VERSION "canboat-NMEA2000-curated"

NS_ :

BS_:

BU_: Vector__XXX

BO_ 2565341184 PGN_59392: 8 Vector__XXX
 SG_ Data : 0|64@1+ (1.0,0) [0|18446744073709551615] "" Vector__XXX

BO_ 2565341184 PGN_59392_isoAcknowledgement: 8 Vector__XXX
 SG_ Control : 0|8@1+ (1.0,0) [0|255] "" Vector__XXX
 SG_ Group_Function : 8|8@1+ (1.0,0) [0|255] "" Vector__XXX
 SG_ PGN : 40|24@1+ (1.0,0) [0.0|262143.0] "" Vector__XXX

BO_ 2565472256 PGN_59904_isoRequest: 8 Vector__XXX
 SG_ PGN : 0|24@1+ (1.0,0) [0.0|262143.0] "" Vector__XXX

BO_ 2565537792 PGN_60160_isoTransportProtocolDataTransfer: 8 Vector__XXX
 SG_ SID : 0|8@1+ (1.0,0) [0|255] "" Vector__XXX
 SG_ Data : 8|56@1+ (1.0,0) [0|72057594037927935] "" Vector__XXX

BO_ 2565603328 PGN_60416_isoTransportProtocolConnectionManagementAbort: 8 Vector__XXX
 SG_ Group_Function_Code : 0|8@1+ (1.0,0) [0|255] "" Vector__XXX
 SG_ Reason : 8|8@1+ (1.0,0) [0|255] "" Vector__XXX
 SG_ PGN : 40|24@1+ (1.0,0) [0.0|262143.0] "" Vector__XXX

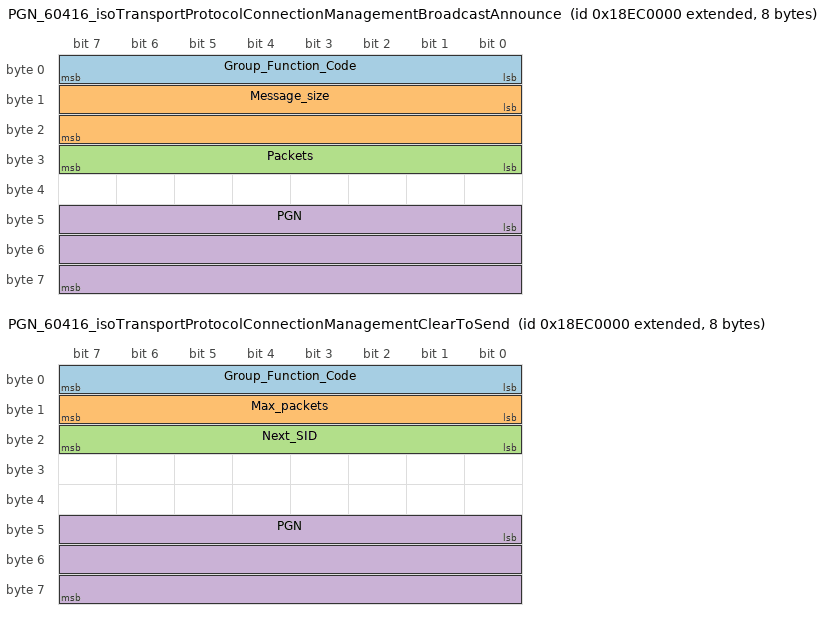
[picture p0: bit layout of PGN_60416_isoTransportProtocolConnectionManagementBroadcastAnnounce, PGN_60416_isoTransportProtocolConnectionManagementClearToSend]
BO_ 2565603328 PGN_60416_isoTransportProtocolConnectionManagementBroadcastAnnounce: 8 Vector__XXX
 SG_ Group_Function_Code : 0|8@1+ (1.0,0) [0|255] "" Vector__XXX
 SG_ Message_size : 8|16@1+ (1.0,0) [0|65535] "" Vector__XXX
 SG_ Packets : 24|8@1+ (1.0,0) [0|255] "" Vector__XXX
 SG_ PGN : 40|24@1+ (1.0,0) [0.0|262143.0] "" Vector__XXX

BO_ 2565603328 PGN_60416_isoTransportProtocolConnectionManagementClearToSend: 8 Vector__XXX
 SG_ Group_Function_Code : 0|8@1+ (1.0,0) [0|255] "" Vector__XXX
 SG_ Max_packets : 8|8@1+ (1.0,0) [0|255] "" Vector__XXX
 SG_ Next_SID : 16|8@1+ (1.0,0) [0|255] "" Vector__XXX
 SG_ PGN : 40|24@1+ (1.0,0) [0.0|262143.0] "" Vector__XXX

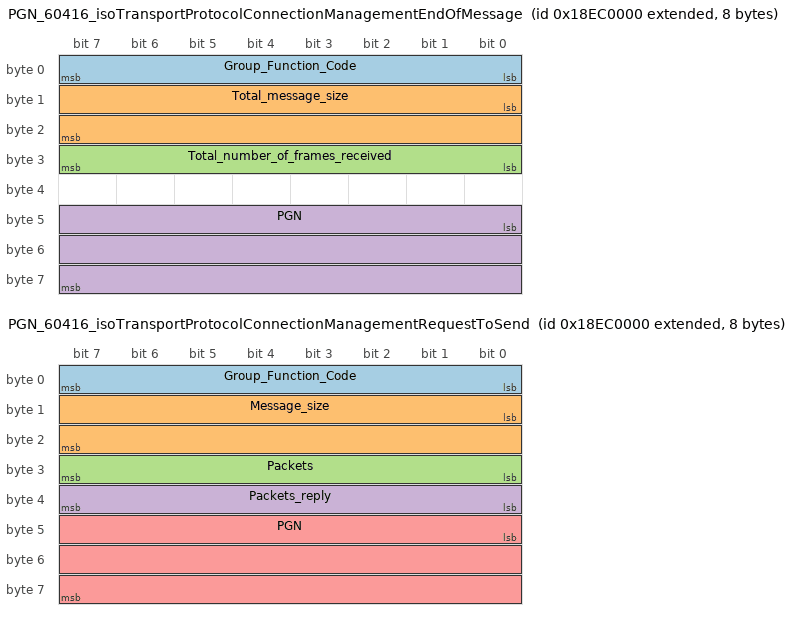
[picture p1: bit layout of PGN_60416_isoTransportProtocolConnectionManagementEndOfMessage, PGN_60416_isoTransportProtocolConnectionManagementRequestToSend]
BO_ 2565603328 PGN_60416_isoTransportProtocolConnectionManagementEndOfMessage: 8 Vector__XXX
 SG_ Group_Function_Code : 0|8@1+ (1.0,0) [0|255] "" Vector__XXX
 SG_ Total_message_size : 8|16@1+ (1.0,0) [0|65535] "" Vector__XXX
 SG_ Total_number_of_frames_received : 24|8@1+ (1.0,0) [0|255] "" Vector__XXX
 SG_ PGN : 40|24@1+ (1.0,0) [0.0|262143.0] "" Vector__XXX

BO_ 2565603328 PGN_60416_isoTransportProtocolConnectionManagementRequestToSend: 8 Vector__XXX
 SG_ Group_Function_Code : 0|8@1+ (1.0,0) [0|255] "" Vector__XXX
 SG_ Message_size : 8|16@1+ (1.0,0) [0|65535] "" Vector__XXX
 SG_ Packets : 24|8@1+ (1.0,0) [0|255] "" Vector__XXX
 SG_ Packets_reply : 32|8@1+ (1.0,0) [0|255] "" Vector__XXX
 SG_ PGN : 40|24@1+ (1.0,0) [0.0|262143.0] "" Vector__XXX

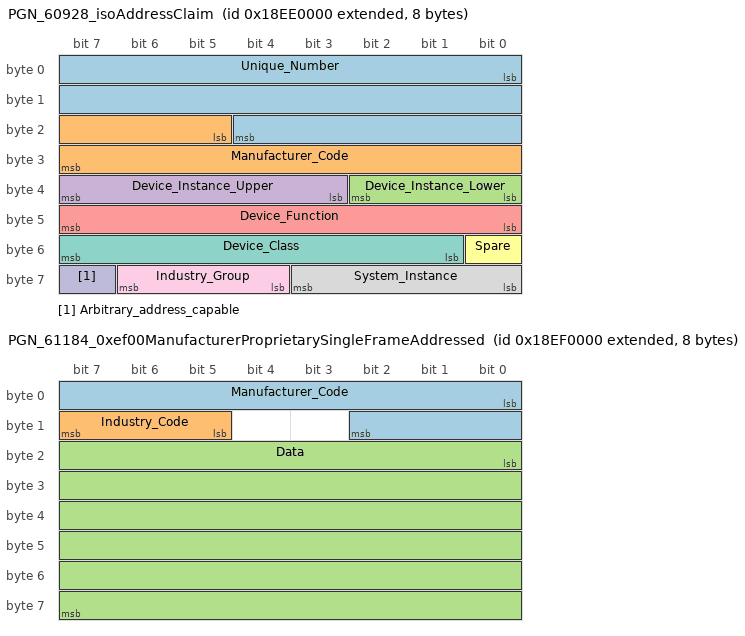
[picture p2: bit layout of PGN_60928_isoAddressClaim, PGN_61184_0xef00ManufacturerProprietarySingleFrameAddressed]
BO_ 2565734400 PGN_60928_isoAddressClaim: 8 Vector__XXX
 SG_ Unique_Number : 0|21@1+ (1.0,0) [0|2097151] "" Vector__XXX
 SG_ Manufacturer_Code : 21|11@1+ (1.0,0) [0|2047] "" Vector__XXX
 SG_ Device_Instance_Lower : 32|3@1+ (1.0,0) [0|7] "" Vector__XXX
 SG_ Device_Instance_Upper : 35|5@1+ (1.0,0) [0|31] "" Vector__XXX
 SG_ Device_Function : 40|8@1+ (1.0,0) [0|255] "" Vector__XXX
 SG_ Spare : 48|1@1+ (1.0,0) [0|1] "" Vector__XXX
 SG_ Device_Class : 49|7@1+ (1.0,0) [0|127] "" Vector__XXX
 SG_ System_Instance : 56|4@1+ (1.0,0) [0|15] "" Vector__XXX
 SG_ Industry_Group : 60|3@1+ (1.0,0) [0|7] "" Vector__XXX
 SG_ Arbitrary_address_capable : 63|1@1+ (1.0,0) [0|1] "" Vector__XXX

BO_ 2565799936 PGN_61184_0xef00ManufacturerProprietarySingleFrameAddressed: 8 Vector__XXX
 SG_ Manufacturer_Code : 0|11@1+ (1.0,0) [0|2047] "" Vector__XXX
 SG_ Industry_Code : 13|3@1+ (1.0,0) [0|7] "" Vector__XXX
 SG_ Data : 16|48@1+ (1.0,0) [0|281474976710655] "" Vector__XXX

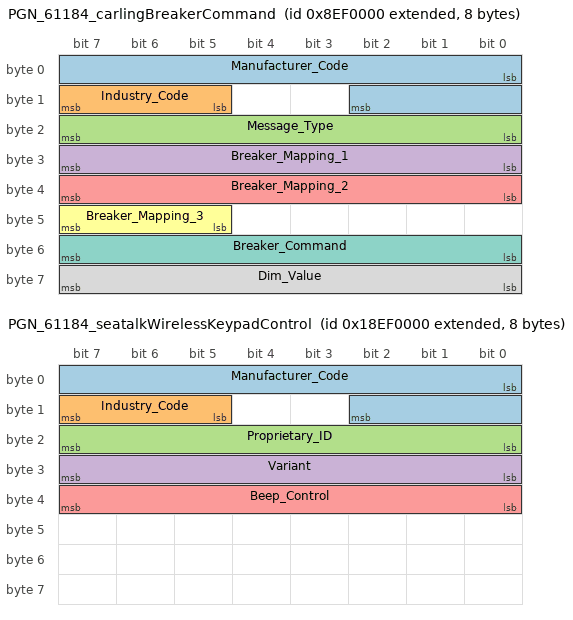
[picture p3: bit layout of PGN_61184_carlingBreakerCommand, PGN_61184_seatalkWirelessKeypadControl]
BO_ 2297364480 PGN_61184_carlingBreakerCommand: 8 Vector__XXX
 SG_ Manufacturer_Code : 0|11@1+ (1.0,0) [0|2047] "" Vector__XXX
 SG_ Industry_Code : 13|3@1+ (1.0,0) [0|7] "" Vector__XXX
 SG_ Message_Type : 16|8@1+ (1.0,0) [0|255] "" Vector__XXX
 SG_ Breaker_Mapping_1 : 24|8@1+ (1.0,0) [0|255] "" Vector__XXX
 SG_ Breaker_Mapping_2 : 32|8@1+ (1.0,0) [0|255] "" Vector__XXX
 SG_ Breaker_Mapping_3 : 45|3@1+ (1.0,0) [0|7] "" Vector__XXX
 SG_ Breaker_Command : 48|8@1+ (1.0,0) [0|255] "" Vector__XXX
 SG_ Dim_Value : 56|8@1+ (1.0,0) [0|255] "" Vector__XXX

BO_ 2565799936 PGN_61184_seatalkWirelessKeypadControl: 8 Vector__XXX
 SG_ Manufacturer_Code : 0|11@1+ (1.0,0) [0|2047] "" Vector__XXX
 SG_ Industry_Code : 13|3@1+ (1.0,0) [0|7] "" Vector__XXX
 SG_ Proprietary_ID : 16|8@1+ (1.0,0) [0|255] "" Vector__XXX
 SG_ Variant : 24|8@1+ (1.0,0) [0|255] "" Vector__XXX
 SG_ Beep_Control : 32|8@1+ (1.0,0) [0|255] "" Vector__XXX

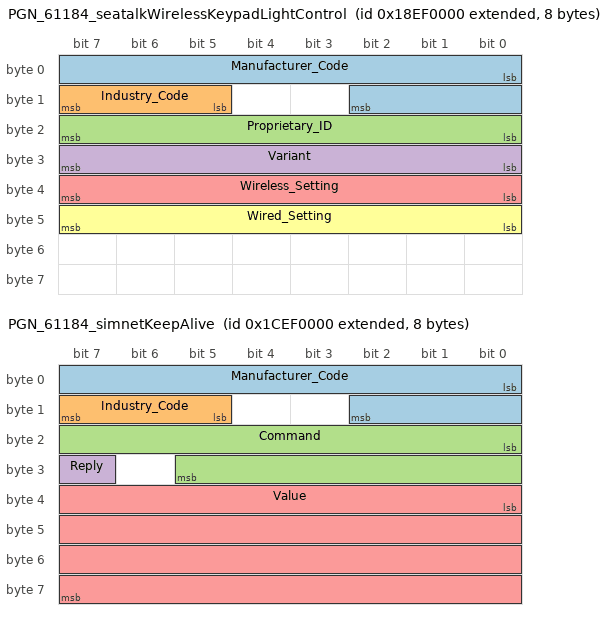
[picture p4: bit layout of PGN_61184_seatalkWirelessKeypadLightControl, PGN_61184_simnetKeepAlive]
BO_ 2565799936 PGN_61184_seatalkWirelessKeypadLightControl: 8 Vector__XXX
 SG_ Manufacturer_Code : 0|11@1+ (1.0,0) [0|2047] "" Vector__XXX
 SG_ Industry_Code : 13|3@1+ (1.0,0) [0|7] "" Vector__XXX
 SG_ Proprietary_ID : 16|8@1+ (1.0,0) [0|255] "" Vector__XXX
 SG_ Variant : 24|8@1+ (1.0,0) [0|255] "" Vector__XXX
 SG_ Wireless_Setting : 32|8@1+ (1.0,0) [0|255] "" Vector__XXX
 SG_ Wired_Setting : 40|8@1+ (1.0,0) [0|255] "" Vector__XXX

BO_ 2632908800 PGN_61184_simnetKeepAlive: 8 Vector__XXX
 SG_ Manufacturer_Code : 0|11@1+ (1.0,0) [0|2047] "" Vector__XXX
 SG_ Industry_Code : 13|3@1+ (1.0,0) [0|7] "" Vector__XXX
 SG_ Command : 16|14@1+ (1.0,0) [0|16383] "" Vector__XXX
 SG_ Reply : 31|1@1+ (1.0,0) [0|1] "" Vector__XXX
 SG_ Value : 32|32@1+ (1.0,0) [0|4294967295] "" Vector__XXX

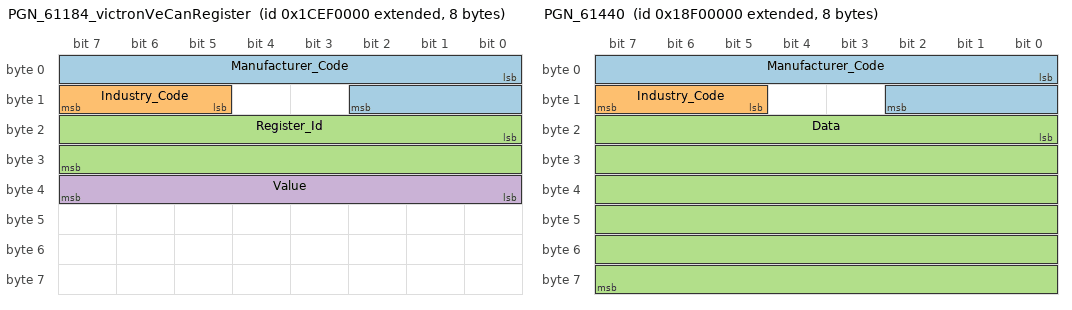
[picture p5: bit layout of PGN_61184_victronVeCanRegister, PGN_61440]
BO_ 2632908800 PGN_61184_victronVeCanRegister: 8 Vector__XXX
 SG_ Manufacturer_Code : 0|11@1+ (1.0,0) [0|2047] "" Vector__XXX
 SG_ Industry_Code : 13|3@1+ (1.0,0) [0|7] "" Vector__XXX
 SG_ Register_Id : 16|16@1+ (1.0,0) [0|65535] "" Vector__XXX
 SG_ Value : 32|8@1+ (1.0,0) [0|255] "" Vector__XXX

BO_ 2565865472 PGN_61440: 8 Vector__XXX
 SG_ Manufacturer_Code : 0|11@1+ (1.0,0) [0|2047] "" Vector__XXX
 SG_ Industry_Code : 13|3@1+ (1.0,0) [0|7] "" Vector__XXX
 SG_ Data : 16|48@1+ (1.0,0) [0|281474976710655] "" Vector__XXX

BO_ 2365450496 PGN_65001_bus1PhaseCBasicAcQuantities: 8 Vector__XXX
 SG_ Line_Line_AC_RMS_Voltage : 0|16@1+ (1.0,0) [0|65535] "" Vector__XXX
 SG_ Line_Neutral_AC_RMS_Voltage : 16|16@1+ (1.0,0) [0|65535] "" Vector__XXX
 SG_ AC_Frequency : 32|16@1+ (0.0078125,0) [0.0|511.9921875] "" Vector__XXX

BO_ 2365450752 PGN_65002_bus1PhaseBBasicAcQuantities: 8 Vector__XXX
 SG_ Line_Line_AC_RMS_Voltage : 0|16@1+ (1.0,0) [0|65535] "" Vector__XXX
 SG_ Line_Neutral_AC_RMS_Voltage : 16|16@1+ (1.0,0) [0|65535] "" Vector__XXX
 SG_ AC_Frequency : 32|16@1+ (0.0078125,0) [0.0|511.9921875] "" Vector__XXX

BO_ 2365451008 PGN_65003_bus1PhaseABasicAcQuantities: 8 Vector__XXX
 SG_ Line_Line_AC_RMS_Voltage : 0|16@1+ (1.0,0) [0|65535] "" Vector__XXX
 SG_ Line_Neutral_AC_RMS_Voltage : 16|16@1+ (1.0,0) [0|65535] "" Vector__XXX
 SG_ AC_Frequency : 32|16@1+ (0.0078125,0) [0.0|511.9921875] "" Vector__XXX

BO_ 2365451264 PGN_65004_bus1AverageBasicAcQuantities: 8 Vector__XXX
 SG_ Line_Line_AC_RMS_Voltage : 0|16@1+ (1.0,0) [0|65535] "" Vector__XXX
 SG_ Line_Neutral_AC_RMS_Voltage : 16|16@1+ (1.0,0) [0|65535] "" Vector__XXX
 SG_ AC_Frequency : 32|16@1+ (0.0078125,0) [0.0|511.9921875] "" Vector__XXX

BO_ 2365451520 PGN_65005_utilityTotalAcEnergy: 8 Vector__XXX
 SG_ Total_Energy_Export : 0|32@1+ (1.0,0) [0|4294967295] "" Vector__XXX
 SG_ Total_Energy_Import : 32|32@1+ (1.0,0) [0|4294967295] "" Vector__XXX

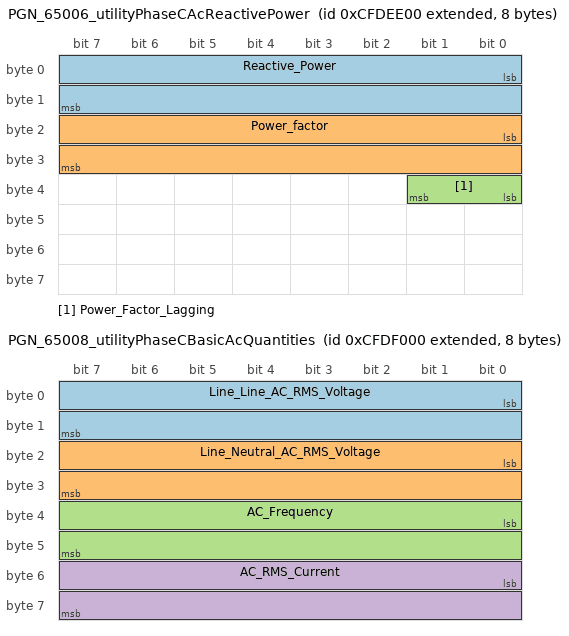
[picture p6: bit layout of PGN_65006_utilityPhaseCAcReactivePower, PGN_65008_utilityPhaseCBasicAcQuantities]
BO_ 2365451776 PGN_65006_utilityPhaseCAcReactivePower: 8 Vector__XXX
 SG_ Reactive_Power : 0|16@1+ (1.0,0) [0|65535] "VAR" Vector__XXX
 SG_ Power_factor : 16|16@1+ (6.103515625e-05,0) [0.0|3.99993896484375] "Cos Phi" Vector__XXX
 SG_ Power_Factor_Lagging : 32|2@1+ (1.0,0) [0|3] "" Vector__XXX

BO_ 2365452032 PGN_65007_utilityPhaseCAcPower: 8 Vector__XXX
 SG_ Real_Power : 0|32@1- (1.0,0) [-2147483648|2147483647] "" Vector__XXX
 SG_ Apparent_Power : 32|32@1- (1.0,0) [-2147483648|2147483647] "" Vector__XXX

BO_ 2365452288 PGN_65008_utilityPhaseCBasicAcQuantities: 8 Vector__XXX
 SG_ Line_Line_AC_RMS_Voltage : 0|16@1+ (1.0,0) [0|65535] "" Vector__XXX
 SG_ Line_Neutral_AC_RMS_Voltage : 16|16@1+ (1.0,0) [0|65535] "" Vector__XXX
 SG_ AC_Frequency : 32|16@1+ (0.0078125,0) [0.0|511.9921875] "" Vector__XXX
 SG_ AC_RMS_Current : 48|16@1+ (1.0,0) [0|65535] "" Vector__XXX

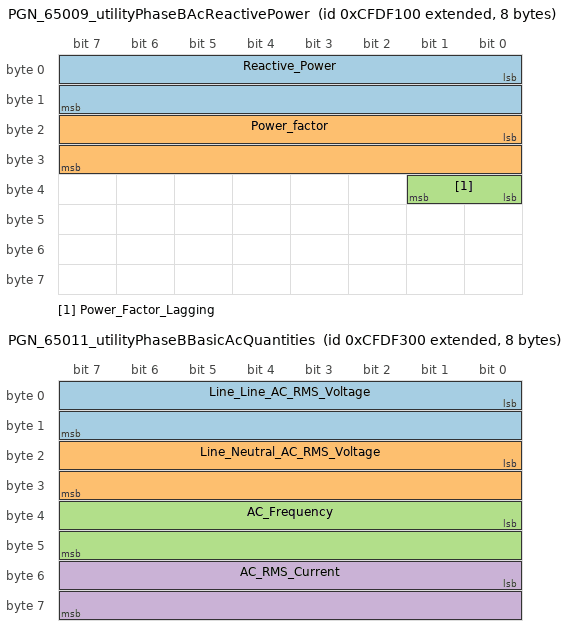
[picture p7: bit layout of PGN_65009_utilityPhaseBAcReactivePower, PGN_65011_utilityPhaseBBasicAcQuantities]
BO_ 2365452544 PGN_65009_utilityPhaseBAcReactivePower: 8 Vector__XXX
 SG_ Reactive_Power : 0|16@1+ (1.0,0) [0|65535] "VAR" Vector__XXX
 SG_ Power_factor : 16|16@1+ (6.103515625e-05,0) [0.0|3.99993896484375] "Cos Phi" Vector__XXX
 SG_ Power_Factor_Lagging : 32|2@1+ (1.0,0) [0|3] "" Vector__XXX

BO_ 2365452800 PGN_65010_utilityPhaseBAcPower: 8 Vector__XXX
 SG_ Real_Power : 0|32@1- (1.0,0) [-2147483648|2147483647] "" Vector__XXX
 SG_ Apparent_Power : 32|32@1- (1.0,0) [-2147483648|2147483647] "" Vector__XXX

BO_ 2365453056 PGN_65011_utilityPhaseBBasicAcQuantities: 8 Vector__XXX
 SG_ Line_Line_AC_RMS_Voltage : 0|16@1+ (1.0,0) [0|65535] "" Vector__XXX
 SG_ Line_Neutral_AC_RMS_Voltage : 16|16@1+ (1.0,0) [0|65535] "" Vector__XXX
 SG_ AC_Frequency : 32|16@1+ (0.0078125,0) [0.0|511.9921875] "" Vector__XXX
 SG_ AC_RMS_Current : 48|16@1+ (1.0,0) [0|65535] "" Vector__XXX

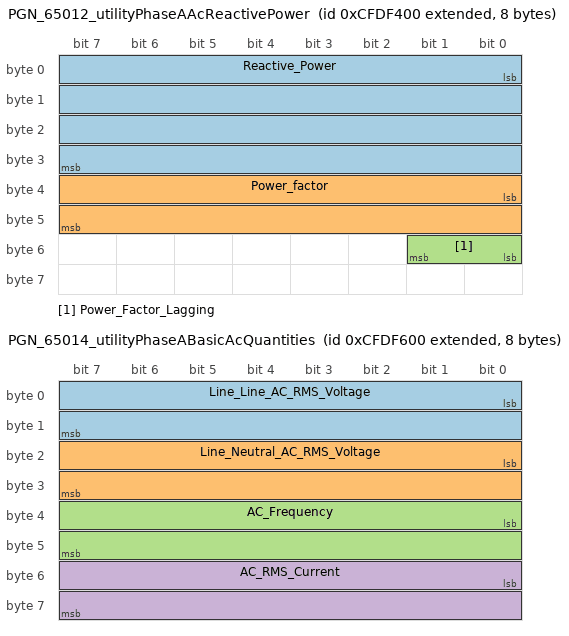
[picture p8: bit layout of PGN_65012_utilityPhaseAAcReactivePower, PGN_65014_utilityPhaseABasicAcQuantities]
BO_ 2365453312 PGN_65012_utilityPhaseAAcReactivePower: 8 Vector__XXX
 SG_ Reactive_Power : 0|32@1- (1.0,0) [-2147483648|2147483647] "" Vector__XXX
 SG_ Power_factor : 32|16@1+ (6.103515625e-05,0) [0.0|3.99993896484375] "Cos Phi" Vector__XXX
 SG_ Power_Factor_Lagging : 48|2@1+ (1.0,0) [0|3] "" Vector__XXX

BO_ 2365453568 PGN_65013_utilityPhaseAAcPower: 8 Vector__XXX
 SG_ Real_Power : 0|32@1- (1.0,0) [-2147483648|2147483647] "" Vector__XXX
 SG_ Apparent_Power : 32|32@1- (1.0,0) [-2147483648|2147483647] "" Vector__XXX

BO_ 2365453824 PGN_65014_utilityPhaseABasicAcQuantities: 8 Vector__XXX
 SG_ Line_Line_AC_RMS_Voltage : 0|16@1+ (1.0,0) [0|65535] "" Vector__XXX
 SG_ Line_Neutral_AC_RMS_Voltage : 16|16@1+ (1.0,0) [0|65535] "" Vector__XXX
 SG_ AC_Frequency : 32|16@1+ (0.0078125,0) [0.0|511.9921875] "" Vector__XXX
 SG_ AC_RMS_Current : 48|16@1+ (1.0,0) [0|65535] "" Vector__XXX

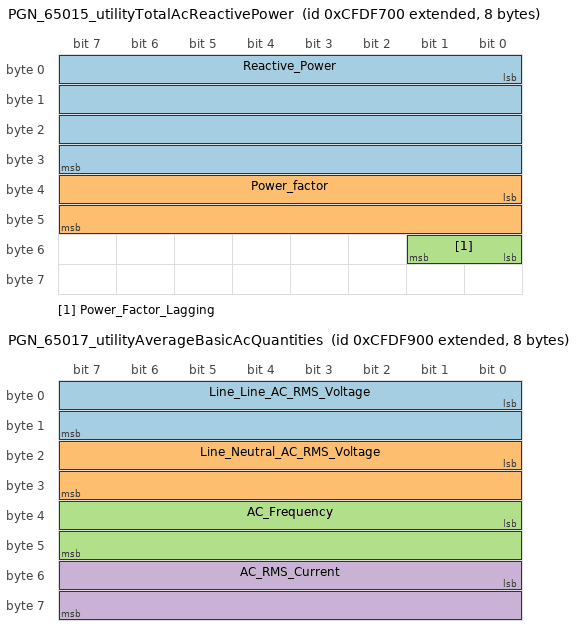
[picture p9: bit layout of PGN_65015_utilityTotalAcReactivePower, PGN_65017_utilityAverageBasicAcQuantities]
BO_ 2365454080 PGN_65015_utilityTotalAcReactivePower: 8 Vector__XXX
 SG_ Reactive_Power : 0|32@1- (1.0,0) [-2147483648|2147483647] "" Vector__XXX
 SG_ Power_factor : 32|16@1+ (6.103515625e-05,0) [0.0|3.99993896484375] "Cos Phi" Vector__XXX
 SG_ Power_Factor_Lagging : 48|2@1+ (1.0,0) [0|3] "" Vector__XXX

BO_ 2365454336 PGN_65016_utilityTotalAcPower: 8 Vector__XXX
 SG_ Real_Power : 0|32@1- (1.0,0) [-2147483648|2147483647] "" Vector__XXX
 SG_ Apparent_Power : 32|32@1- (1.0,0) [-2147483648|2147483647] "" Vector__XXX

BO_ 2365454592 PGN_65017_utilityAverageBasicAcQuantities: 8 Vector__XXX
 SG_ Line_Line_AC_RMS_Voltage : 0|16@1+ (1.0,0) [0|65535] "" Vector__XXX
 SG_ Line_Neutral_AC_RMS_Voltage : 16|16@1+ (1.0,0) [0|65535] "" Vector__XXX
 SG_ AC_Frequency : 32|16@1+ (0.0078125,0) [0.0|511.9921875] "" Vector__XXX
 SG_ AC_RMS_Current : 48|16@1+ (1.0,0) [0|65535] "" Vector__XXX

BO_ 2365454848 PGN_65018_generatorTotalAcEnergy: 8 Vector__XXX
 SG_ Total_Energy_Export : 0|32@1+ (1.0,0) [0|4294967295] "" Vector__XXX
 SG_ Total_Energy_Import : 32|32@1+ (1.0,0) [0|4294967295] "" Vector__XXX

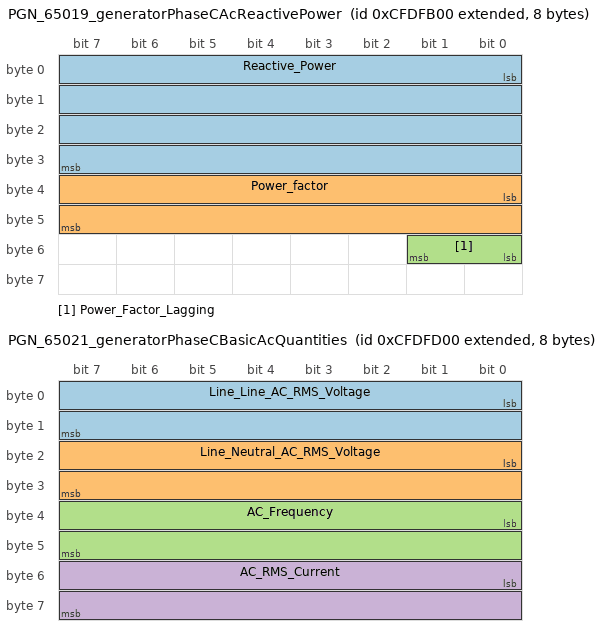
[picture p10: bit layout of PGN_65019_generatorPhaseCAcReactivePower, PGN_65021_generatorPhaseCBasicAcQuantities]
BO_ 2365455104 PGN_65019_generatorPhaseCAcReactivePower: 8 Vector__XXX
 SG_ Reactive_Power : 0|32@1- (1.0,0) [-2147483648|2147483647] "" Vector__XXX
 SG_ Power_factor : 32|16@1+ (6.103515625e-05,0) [0.0|3.99993896484375] "Cos Phi" Vector__XXX
 SG_ Power_Factor_Lagging : 48|2@1+ (1.0,0) [0|3] "" Vector__XXX

BO_ 2365455360 PGN_65020_generatorPhaseCAcPower: 8 Vector__XXX
 SG_ Real_Power : 0|32@1- (1.0,0) [-2147483648|2147483647] "" Vector__XXX
 SG_ Apparent_Power : 32|32@1- (1.0,0) [-2147483648|2147483647] "" Vector__XXX

BO_ 2365455616 PGN_65021_generatorPhaseCBasicAcQuantities: 8 Vector__XXX
 SG_ Line_Line_AC_RMS_Voltage : 0|16@1+ (1.0,0) [0|65535] "" Vector__XXX
 SG_ Line_Neutral_AC_RMS_Voltage : 16|16@1+ (1.0,0) [0|65535] "" Vector__XXX
 SG_ AC_Frequency : 32|16@1+ (0.0078125,0) [0.0|511.9921875] "" Vector__XXX
 SG_ AC_RMS_Current : 48|16@1+ (1.0,0) [0|65535] "" Vector__XXX

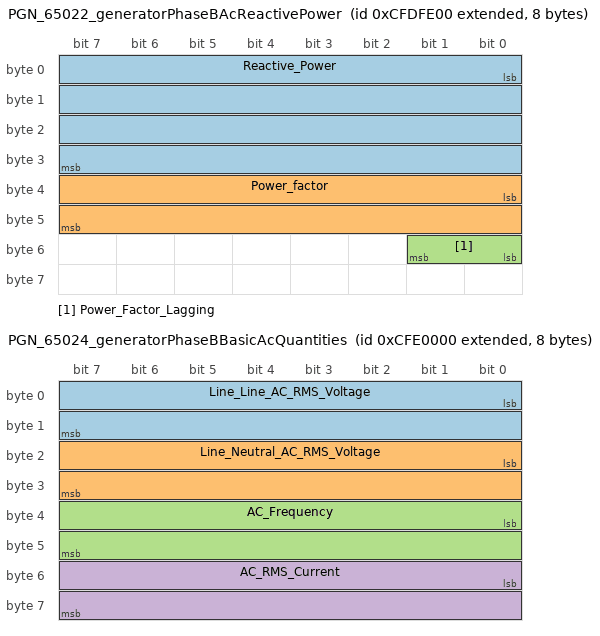
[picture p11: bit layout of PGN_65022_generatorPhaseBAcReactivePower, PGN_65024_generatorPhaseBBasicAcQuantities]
BO_ 2365455872 PGN_65022_generatorPhaseBAcReactivePower: 8 Vector__XXX
 SG_ Reactive_Power : 0|32@1- (1.0,0) [-2147483648|2147483647] "" Vector__XXX
 SG_ Power_factor : 32|16@1+ (6.103515625e-05,0) [0.0|3.99993896484375] "Cos Phi" Vector__XXX
 SG_ Power_Factor_Lagging : 48|2@1+ (1.0,0) [0|3] "" Vector__XXX

BO_ 2365456128 PGN_65023_generatorPhaseBAcPower: 8 Vector__XXX
 SG_ Real_Power : 0|32@1- (1.0,0) [-2147483648|2147483647] "" Vector__XXX
 SG_ Apparent_Power : 32|32@1- (1.0,0) [-2147483648|2147483647] "" Vector__XXX

BO_ 2365456384 PGN_65024_generatorPhaseBBasicAcQuantities: 8 Vector__XXX
 SG_ Line_Line_AC_RMS_Voltage : 0|16@1+ (1.0,0) [0|65535] "" Vector__XXX
 SG_ Line_Neutral_AC_RMS_Voltage : 16|16@1+ (1.0,0) [0|65535] "" Vector__XXX
 SG_ AC_Frequency : 32|16@1+ (0.0078125,0) [0.0|511.9921875] "" Vector__XXX
 SG_ AC_RMS_Current : 48|16@1+ (1.0,0) [0|65535] "" Vector__XXX

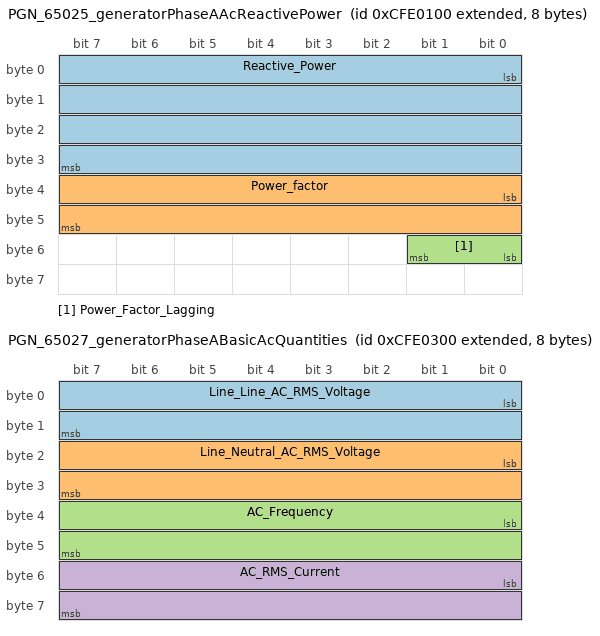
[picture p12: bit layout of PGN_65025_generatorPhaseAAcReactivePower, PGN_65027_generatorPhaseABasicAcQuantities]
BO_ 2365456640 PGN_65025_generatorPhaseAAcReactivePower: 8 Vector__XXX
 SG_ Reactive_Power : 0|32@1- (1.0,0) [-2147483648|2147483647] "" Vector__XXX
 SG_ Power_factor : 32|16@1+ (6.103515625e-05,0) [0.0|3.99993896484375] "Cos Phi" Vector__XXX
 SG_ Power_Factor_Lagging : 48|2@1+ (1.0,0) [0|3] "" Vector__XXX

BO_ 2365456896 PGN_65026_generatorPhaseAAcPower: 8 Vector__XXX
 SG_ Real_Power : 0|32@1- (1.0,0) [-2147483648|2147483647] "" Vector__XXX
 SG_ Apparent_Power : 32|32@1- (1.0,0) [-2147483648|2147483647] "" Vector__XXX

BO_ 2365457152 PGN_65027_generatorPhaseABasicAcQuantities: 8 Vector__XXX
 SG_ Line_Line_AC_RMS_Voltage : 0|16@1+ (1.0,0) [0|65535] "" Vector__XXX
 SG_ Line_Neutral_AC_RMS_Voltage : 16|16@1+ (1.0,0) [0|65535] "" Vector__XXX
 SG_ AC_Frequency : 32|16@1+ (0.0078125,0) [0.0|511.9921875] "" Vector__XXX
 SG_ AC_RMS_Current : 48|16@1+ (1.0,0) [0|65535] "" Vector__XXX

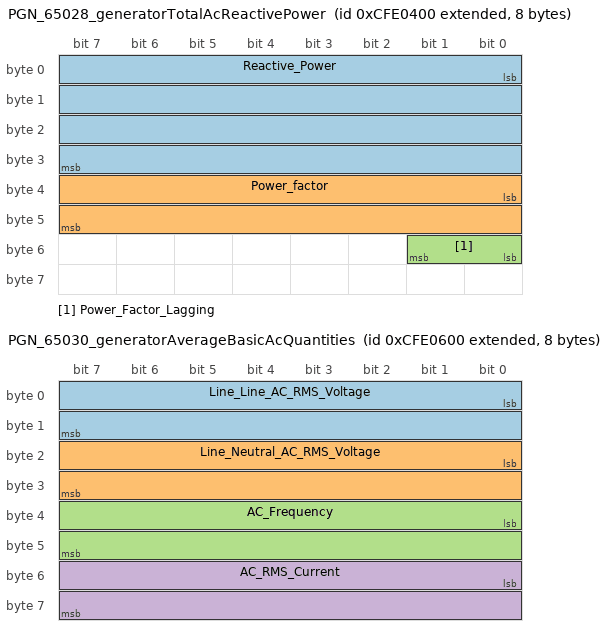
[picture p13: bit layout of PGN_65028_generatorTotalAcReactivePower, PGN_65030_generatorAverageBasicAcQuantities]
BO_ 2365457408 PGN_65028_generatorTotalAcReactivePower: 8 Vector__XXX
 SG_ Reactive_Power : 0|32@1- (1.0,0) [-2147483648|2147483647] "" Vector__XXX
 SG_ Power_factor : 32|16@1+ (6.103515625e-05,0) [0.0|3.99993896484375] "Cos Phi" Vector__XXX
 SG_ Power_Factor_Lagging : 48|2@1+ (1.0,0) [0|3] "" Vector__XXX

BO_ 2365457664 PGN_65029_generatorTotalAcPower: 8 Vector__XXX
 SG_ Real_Power : 0|32@1- (1.0,0) [-2147483648|2147483647] "" Vector__XXX
 SG_ Apparent_Power : 32|32@1- (1.0,0) [-2147483648|2147483647] "" Vector__XXX

BO_ 2365457920 PGN_65030_generatorAverageBasicAcQuantities: 8 Vector__XXX
 SG_ Line_Line_AC_RMS_Voltage : 0|16@1+ (1.0,0) [0|65535] "" Vector__XXX
 SG_ Line_Neutral_AC_RMS_Voltage : 16|16@1+ (1.0,0) [0|65535] "" Vector__XXX
 SG_ AC_Frequency : 32|16@1+ (0.0078125,0) [0.0|511.9921875] "" Vector__XXX
 SG_ AC_RMS_Current : 48|16@1+ (1.0,0) [0|65535] "" Vector__XXX

BO_ 2566838272 PGN_65240_isoCommandedAddress: 9 Vector__XXX
 SG_ Unique_Number : 0|21@1+ (1.0,0) [0|2097151] "" Vector__XXX
 SG_ Manufacturer_Code : 21|11@1+ (1.0,0) [0|2047] "" Vector__XXX
 SG_ Device_Instance_Lower : 32|3@1+ (1.0,0) [0|7] "" Vector__XXX
 SG_ Device_Instance_Upper : 35|5@1+ (1.0,0) [0|31] "" Vector__XXX
 SG_ Device_Function : 40|8@1+ (1.0,0) [0|255] "" Vector__XXX
 SG_ Device_Class : 49|7@1+ (1.0,0) [0|127] "" Vector__XXX
 SG_ System_Instance : 56|4@1+ (1.0,0) [0|15] "" Vector__XXX
 SG_ Industry_Code : 60|3@1+ (1.0,0) [0|7] "" Vector__XXX
 SG_ New_Source_Address : 64|8@1+ (1.0,0) [0|255] "" Vector__XXX

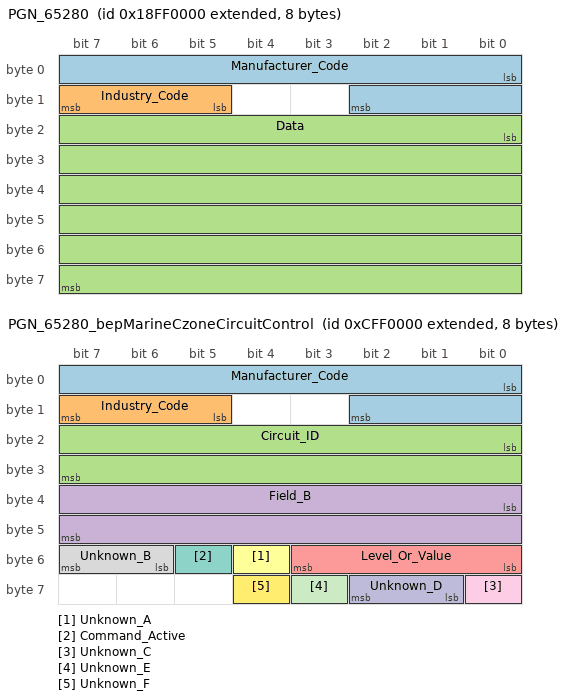
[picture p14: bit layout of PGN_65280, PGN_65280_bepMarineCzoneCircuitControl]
BO_ 2566848512 PGN_65280: 8 Vector__XXX
 SG_ Manufacturer_Code : 0|11@1+ (1.0,0) [0|2047] "" Vector__XXX
 SG_ Industry_Code : 13|3@1+ (1.0,0) [0|7] "" Vector__XXX
 SG_ Data : 16|48@1+ (1.0,0) [0|281474976710655] "" Vector__XXX

BO_ 2365521920 PGN_65280_bepMarineCzoneCircuitControl: 8 Vector__XXX
 SG_ Manufacturer_Code : 0|11@1+ (1.0,0) [0|2047] "" Vector__XXX
 SG_ Industry_Code : 13|3@1+ (1.0,0) [0|7] "" Vector__XXX
 SG_ Circuit_ID : 16|16@1+ (1.0,0) [0|65535] "" Vector__XXX
 SG_ Field_B : 32|16@1+ (1.0,0) [0|65535] "" Vector__XXX
 SG_ Level_Or_Value : 48|4@1+ (1.0,0) [0|15] "" Vector__XXX
 SG_ Unknown_A : 52|1@1+ (1.0,0) [0|1] "" Vector__XXX
 SG_ Command_Active : 53|1@1+ (1.0,0) [0|1] "" Vector__XXX
 SG_ Unknown_B : 54|2@1+ (1.0,0) [0|3] "" Vector__XXX
 SG_ Unknown_C : 56|1@1+ (1.0,0) [0|1] "" Vector__XXX
 SG_ Unknown_D : 57|2@1+ (1.0,0) [0|3] "" Vector__XXX
 SG_ Unknown_E : 59|1@1+ (1.0,0) [0|1] "" Vector__XXX
 SG_ Unknown_F : 60|1@1+ (1.0,0) [0|1] "" Vector__XXX

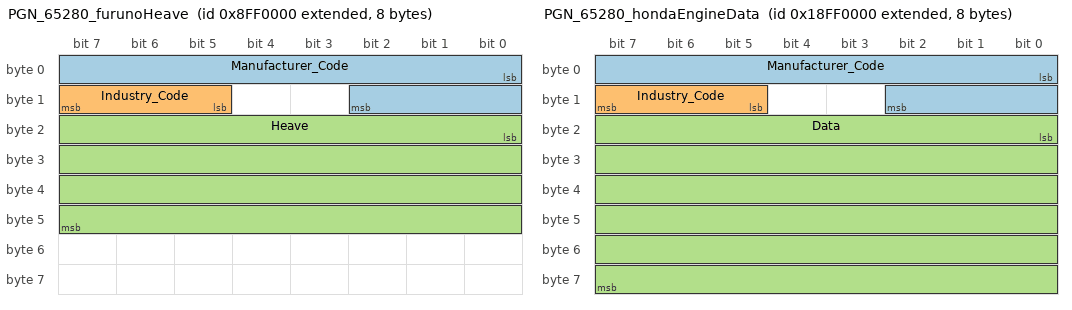
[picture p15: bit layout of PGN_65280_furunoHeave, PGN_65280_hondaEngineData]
BO_ 2298413056 PGN_65280_furunoHeave: 8 Vector__XXX
 SG_ Manufacturer_Code : 0|11@1+ (1.0,0) [0|2047] "" Vector__XXX
 SG_ Industry_Code : 13|3@1+ (1.0,0) [0|7] "" Vector__XXX
 SG_ Heave : 16|32@1- (0.001,0) [-2147483.648|2147483.647] "" Vector__XXX

BO_ 2566848512 PGN_65280_hondaEngineData: 8 Vector__XXX
 SG_ Manufacturer_Code : 0|11@1+ (1.0,0) [0|2047] "" Vector__XXX
 SG_ Industry_Code : 13|3@1+ (1.0,0) [0|7] "" Vector__XXX
 SG_ Data : 16|48@1+ (1.0,0) [0|281474976710655] "" Vector__XXX

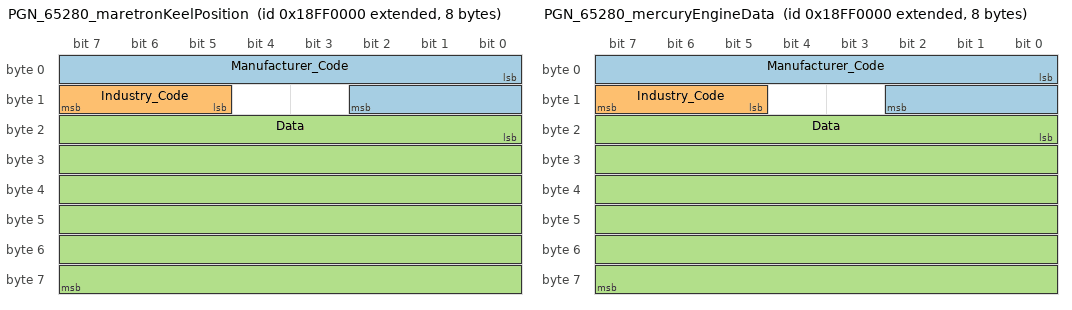
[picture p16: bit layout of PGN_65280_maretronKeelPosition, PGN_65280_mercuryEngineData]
BO_ 2566848512 PGN_65280_maretronKeelPosition: 8 Vector__XXX
 SG_ Manufacturer_Code : 0|11@1+ (1.0,0) [0|2047] "" Vector__XXX
 SG_ Industry_Code : 13|3@1+ (1.0,0) [0|7] "" Vector__XXX
 SG_ Data : 16|48@1+ (1.0,0) [0|281474976710655] "" Vector__XXX

BO_ 2566848512 PGN_65280_mercuryEngineData: 8 Vector__XXX
 SG_ Manufacturer_Code : 0|11@1+ (1.0,0) [0|2047] "" Vector__XXX
 SG_ Industry_Code : 13|3@1+ (1.0,0) [0|7] "" Vector__XXX
 SG_ Data : 16|48@1+ (1.0,0) [0|281474976710655] "" Vector__XXX

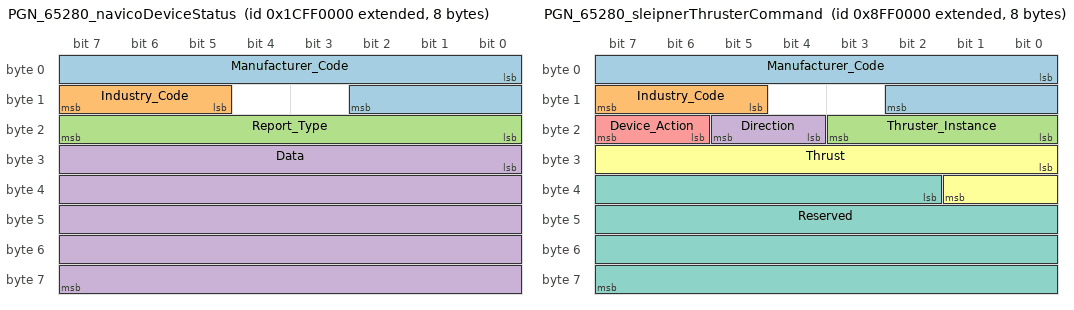
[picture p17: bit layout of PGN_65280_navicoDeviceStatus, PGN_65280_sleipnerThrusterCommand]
BO_ 2633957376 PGN_65280_navicoDeviceStatus: 8 Vector__XXX
 SG_ Manufacturer_Code : 0|11@1+ (1.0,0) [0|2047] "" Vector__XXX
 SG_ Industry_Code : 13|3@1+ (1.0,0) [0|7] "" Vector__XXX
 SG_ Report_Type : 16|8@1+ (1.0,0) [0|255] "" Vector__XXX
 SG_ Data : 24|40@1+ (1.0,0) [0|1099511627775] "" Vector__XXX

BO_ 2298413056 PGN_65280_sleipnerThrusterCommand: 8 Vector__XXX
 SG_ Manufacturer_Code : 0|11@1+ (1.0,0) [0|2047] "" Vector__XXX
 SG_ Industry_Code : 13|3@1+ (1.0,0) [0|7] "" Vector__XXX
 SG_ Thruster_Instance : 16|4@1+ (1.0,0) [0|15] "" Vector__XXX
 SG_ Direction : 20|2@1+ (1.0,0) [0|3] "" Vector__XXX
 SG_ Device_Action : 22|2@1+ (1.0,0) [0|3] "" Vector__XXX
 SG_ Thrust : 24|10@1+ (0.1,0) [0.0|102.30000000000001] "%" Vector__XXX
 SG_ Reserved : 34|30@1+ (1.0,0) [0|1073741823] "" Vector__XXX

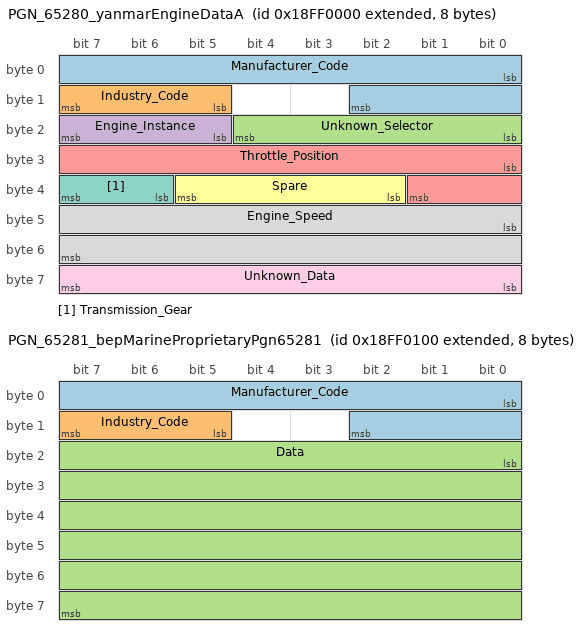
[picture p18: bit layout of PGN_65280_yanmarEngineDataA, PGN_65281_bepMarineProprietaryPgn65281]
BO_ 2566848512 PGN_65280_yanmarEngineDataA: 8 Vector__XXX
 SG_ Manufacturer_Code : 0|11@1+ (1.0,0) [0|2047] "" Vector__XXX
 SG_ Industry_Code : 13|3@1+ (1.0,0) [0|7] "" Vector__XXX
 SG_ Unknown_Selector : 16|5@1+ (1.0,0) [0|31] "" Vector__XXX
 SG_ Engine_Instance : 21|3@1+ (1.0,0) [0|7] "" Vector__XXX
 SG_ Throttle_Position : 24|10@1+ (0.1,0) [0.0|102.30000000000001] "%" Vector__XXX
 SG_ Spare : 34|4@1+ (1.0,0) [0|15] "" Vector__XXX
 SG_ Transmission_Gear : 38|2@1+ (1.0,0) [0|3] "" Vector__XXX
 SG_ Engine_Speed : 40|16@1+ (1.0,0) [0|65535] "rpm" Vector__XXX
 SG_ Unknown_Data : 56|8@1+ (1.0,0) [0|255] "" Vector__XXX

BO_ 2566848768 PGN_65281_bepMarineProprietaryPgn65281: 8 Vector__XXX
 SG_ Manufacturer_Code : 0|11@1+ (1.0,0) [0|2047] "" Vector__XXX
 SG_ Industry_Code : 13|3@1+ (1.0,0) [0|7] "" Vector__XXX
 SG_ Data : 16|48@1+ (1.0,0) [0|281474976710655] "" Vector__XXX

BO_ 2566848768 PGN_65281_yanmarEngineDataB: 8 Vector__XXX
 SG_ Manufacturer_Code : 0|11@1+ (1.0,0) [0|2047] "" Vector__XXX
 SG_ Industry_Code : 13|3@1+ (1.0,0) [0|7] "" Vector__XXX
 SG_ Data : 16|48@1+ (1.0,0) [0|281474976710655] "" Vector__XXX

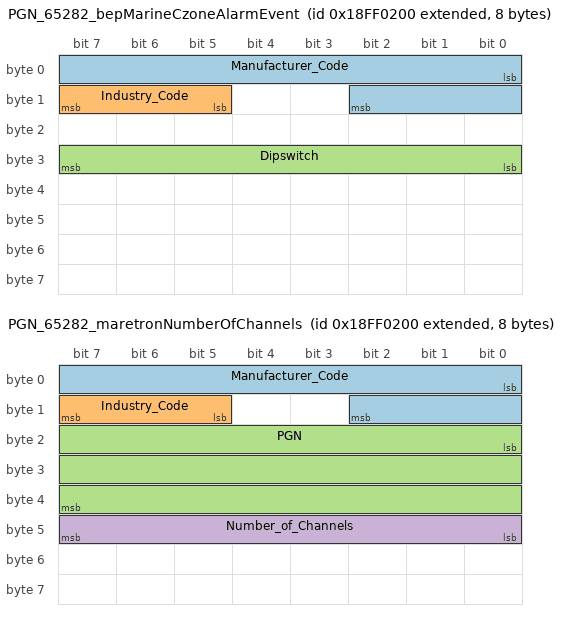
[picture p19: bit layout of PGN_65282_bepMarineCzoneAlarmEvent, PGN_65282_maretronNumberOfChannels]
BO_ 2566849024 PGN_65282_bepMarineCzoneAlarmEvent: 8 Vector__XXX
 SG_ Manufacturer_Code : 0|11@1+ (1.0,0) [0|2047] "" Vector__XXX
 SG_ Industry_Code : 13|3@1+ (1.0,0) [0|7] "" Vector__XXX
 SG_ Dipswitch : 24|8@1+ (1.0,0) [0|255] "" Vector__XXX

BO_ 2566849024 PGN_65282_maretronNumberOfChannels: 8 Vector__XXX
 SG_ Manufacturer_Code : 0|11@1+ (1.0,0) [0|2047] "" Vector__XXX
 SG_ Industry_Code : 13|3@1+ (1.0,0) [0|7] "" Vector__XXX
 SG_ PGN : 16|24@1+ (1.0,0) [0.0|262143.0] "" Vector__XXX
 SG_ Number_of_Channels : 40|8@1+ (1.0,0) [0|255] "" Vector__XXX

CM_ BO_ 2565341184 "NMEA2000: PGN 59392 - 0xE800-0xEE00: Standardized single-frame addressed (type: Single)";
CM_ BO_ 2565341184 "NMEA2000: PGN 59392 - ISO Acknowledgement (type: Single)";
CM_ BO_ 2565472256 "NMEA2000: PGN 59904 - ISO Request (type: Single)";
CM_ BO_ 2565537792 "NMEA2000: PGN 60160 - ISO Transport Protocol, Data Transfer (type: Single)";
CM_ BO_ 2565603328 "NMEA2000: PGN 60416 - ISO Transport Protocol, Connection Management - Abort (type: Single)";
CM_ BO_ 2565603328 "NMEA2000: PGN 60416 - ISO Transport Protocol, Connection Management - Broadcast Announce (type: Single)";
CM_ BO_ 2565603328 "NMEA2000: PGN 60416 - ISO Transport Protocol, Connection Management - Clear To Send (type: Single)";
CM_ BO_ 2565603328 "NMEA2000: PGN 60416 - ISO Transport Protocol, Connection Management - End Of Message (type: Single)";
CM_ BO_ 2565603328 "NMEA2000: PGN 60416 - ISO Transport Protocol, Connection Management - Request To Send (type: Single)";
CM_ BO_ 2565734400 "NMEA2000: PGN 60928 - ISO Address Claim (type: Single)";
CM_ BO_ 2565799936 "NMEA2000: PGN 61184 - 0xEF00: Manufacturer Proprietary single-frame addressed (type: Single)";
CM_ BO_ 2297364480 "NMEA2000: PGN 61184 - Carling: Breaker Command (type: Single)";
CM_ BO_ 2565799936 "NMEA2000: PGN 61184 - Seatalk: Wireless Keypad Control (type: Single)";
CM_ BO_ 2565799936 "NMEA2000: PGN 61184 - Seatalk: Wireless Keypad Light Control (type: Single)";
CM_ BO_ 2632908800 "NMEA2000: PGN 61184 - Simnet: Keep Alive (type: Single)";
CM_ BO_ 2632908800 "NMEA2000: PGN 61184 - Victron: VE.Can Register (type: Single)";
CM_ BO_ 2565865472 "NMEA2000: PGN 61440 - 0xF000-0xFEFF: Standardized single-frame non-addressed (type: Single)";
CM_ BO_ 2365450496 "NMEA2000: PGN 65001 - Bus #1 Phase C Basic AC Quantities (type: Single)";
CM_ BO_ 2365450752 "NMEA2000: PGN 65002 - Bus #1 Phase B Basic AC Quantities (type: Single)";
CM_ BO_ 2365451008 "NMEA2000: PGN 65003 - Bus #1 Phase A Basic AC Quantities (type: Single)";
CM_ BO_ 2365451264 "NMEA2000: PGN 65004 - Bus #1 Average Basic AC Quantities (type: Single)";
CM_ BO_ 2365451520 "NMEA2000: PGN 65005 - Utility Total AC Energy (type: Single)";
CM_ BO_ 2365451776 "NMEA2000: PGN 65006 - Utility Phase C AC Reactive Power (type: Single)";
CM_ BO_ 2365452032 "NMEA2000: PGN 65007 - Utility Phase C AC Power (type: Single)";
CM_ BO_ 2365452288 "NMEA2000: PGN 65008 - Utility Phase C Basic AC Quantities (type: Single)";
CM_ BO_ 2365452544 "NMEA2000: PGN 65009 - Utility Phase B AC Reactive Power (type: Single)";
CM_ BO_ 2365452800 "NMEA2000: PGN 65010 - Utility Phase B AC Power (type: Single)";
CM_ BO_ 2365453056 "NMEA2000: PGN 65011 - Utility Phase B Basic AC Quantities (type: Single)";
CM_ BO_ 2365453312 "NMEA2000: PGN 65012 - Utility Phase A AC Reactive Power (type: Single)";
CM_ BO_ 2365453568 "NMEA2000: PGN 65013 - Utility Phase A AC Power (type: Single)";
CM_ BO_ 2365453824 "NMEA2000: PGN 65014 - Utility Phase A Basic AC Quantities (type: Single)";
CM_ BO_ 2365454080 "NMEA2000: PGN 65015 - Utility Total AC Reactive Power (type: Single)";
CM_ BO_ 2365454336 "NMEA2000: PGN 65016 - Utility Total AC Power (type: Single)";
CM_ BO_ 2365454592 "NMEA2000: PGN 65017 - Utility Average Basic AC Quantities (type: Single)";
CM_ BO_ 2365454848 "NMEA2000: PGN 65018 - Generator Total AC Energy (type: Single)";
CM_ BO_ 2365455104 "NMEA2000: PGN 65019 - Generator Phase C AC Reactive Power (type: Single)";
CM_ BO_ 2365455360 "NMEA2000: PGN 65020 - Generator Phase C AC Power (type: Single)";
CM_ BO_ 2365455616 "NMEA2000: PGN 65021 - Generator Phase C Basic AC Quantities (type: Single)";
CM_ BO_ 2365455872 "NMEA2000: PGN 65022 - Generator Phase B AC Reactive Power (type: Single)";
CM_ BO_ 2365456128 "NMEA2000: PGN 65023 - Generator Phase B AC Power (type: Single)";
CM_ BO_ 2365456384 "NMEA2000: PGN 65024 - Generator Phase B Basic AC Quantities (type: Single)";
CM_ BO_ 2365456640 "NMEA2000: PGN 65025 - Generator Phase A AC Reactive Power (type: Single)";
CM_ BO_ 2365456896 "NMEA2000: PGN 65026 - Generator Phase A AC Power (type: Single)";
CM_ BO_ 2365457152 "NMEA2000: PGN 65027 - Generator Phase A Basic AC Quantities (type: Single)";
CM_ BO_ 2365457408 "NMEA2000: PGN 65028 - Generator Total AC Reactive Power (type: Single)";
CM_ BO_ 2365457664 "NMEA2000: PGN 65029 - Generator Total AC Power (type: Single)";
CM_ BO_ 2365457920 "NMEA2000: PGN 65030 - Generator Average Basic AC Quantities (type: Single)";
CM_ BO_ 2566838272 "NMEA2000: PGN 65240 - ISO Commanded Address (type: ISO)";
CM_ BO_ 2566848512 "NMEA2000: PGN 65280 - 0xFF00-0xFFFF: Manufacturer Proprietary single-frame non-addressed (type: Single)";
CM_ BO_ 2365521920 "NMEA2000: PGN 65280 - BEP Marine: CZone Circuit Control (type: Single)";
CM_ BO_ 2298413056 "NMEA2000: PGN 65280 - Furuno: Heave (type: Single)";
CM_ BO_ 2566848512 "NMEA2000: PGN 65280 - Honda: Engine Data (type: Single)";
CM_ BO_ 2566848512 "NMEA2000: PGN 65280 - Maretron: Keel Position (type: Single)";
CM_ BO_ 2566848512 "NMEA2000: PGN 65280 - Mercury: Engine Data (type: Single)";
CM_ BO_ 2633957376 "NMEA2000: PGN 65280 - Navico: Device Status (type: Single)";
CM_ BO_ 2298413056 "NMEA2000: PGN 65280 - Sleipner: Thruster Command (type: Single)";
CM_ BO_ 2566848512 "NMEA2000: PGN 65280 - Yanmar: Engine Data A (type: Single)";
CM_ BO_ 2566848768 "NMEA2000: PGN 65281 - BEP Marine: Proprietary PGN 65281 (type: Single)";
CM_ BO_ 2566848768 "NMEA2000: PGN 65281 - Yanmar: Engine Data B (type: Single)";
CM_ BO_ 2566849024 "NMEA2000: PGN 65282 - BEP Marine: CZone Alarm Event (type: Single)";
CM_ BO_ 2566849024 "NMEA2000: PGN 65282 - Maretron: Number of Channels (type: Single)";
CM_ SG_ 2565341184 Data "canboat type: BINARY";
CM_ SG_ 2565341184 Control "canboat type: LOOKUP";
CM_ SG_ 2565341184 Group_Function "canboat type: UINT8";
CM_ SG_ 2565341184 PGN "Parameter Group Number of requested information; canboat type: PGN";
CM_ SG_ 2565472256 PGN "canboat type: PGN";
CM_ SG_ 2565537792 SID "Sequence number of multi-packet frame; canboat type: UINT8";
CM_ SG_ 2565537792 Data "Multi-packet packetized data - 56 bits organized as seven 8-bit bytes, each of the bytes is transmitted in the same order as it would in a standard (i.e., single frame) message. Unused bytes shall be filled with 0xFF.; canboat type: BINARY";
CM_ SG_ 2565603328 Group_Function_Code "Abort; canboat type: LOOKUP";
CM_ SG_ 2565603328 Reason "canboat type: BINARY";
CM_ SG_ 2565603328 PGN "canboat type: PGN";
CM_ SG_ 2565603328 Group_Function_Code "BAM; canboat type: LOOKUP";
CM_ SG_ 2565603328 Message_size "bytes; canboat type: UINT16";
CM_ SG_ 2565603328 Packets "frames; canboat type: UINT8";
CM_ SG_ 2565603328 PGN "canboat type: PGN";
CM_ SG_ 2565603328 Group_Function_Code "CTS; canboat type: LOOKUP";
CM_ SG_ 2565603328 Max_packets "Number of frames that can be sent before another CTS is required; canboat type: UINT8";
CM_ SG_ 2565603328 Next_SID "Number of next frame to be transmitted; canboat type: UINT8";
CM_ SG_ 2565603328 PGN "canboat type: PGN";
CM_ SG_ 2565603328 Group_Function_Code "EOM; canboat type: LOOKUP";
CM_ SG_ 2565603328 Total_message_size "bytes; canboat type: UINT16";
CM_ SG_ 2565603328 Total_number_of_frames_received "Total number of of frames received; canboat type: UINT8";
CM_ SG_ 2565603328 PGN "canboat type: PGN";
CM_ SG_ 2565603328 Group_Function_Code "RTS; canboat type: LOOKUP";
CM_ SG_ 2565603328 Message_size "bytes; canboat type: UINT16";
CM_ SG_ 2565603328 Packets "packets; canboat type: UINT8";
CM_ SG_ 2565603328 Packets_reply "packets sent in response to CTS; canboat type: UINT8";
CM_ SG_ 2565603328 PGN "canboat type: PGN";
CM_ SG_ 2565734400 Unique_Number "ISO Identity Number; canboat type: UNSIGNED_INTEGER";
CM_ SG_ 2565734400 Manufacturer_Code "canboat type: LOOKUP";
CM_ SG_ 2565734400 Device_Instance_Lower "ISO ECU Instance; canboat type: UNSIGNED_INTEGER";
CM_ SG_ 2565734400 Device_Instance_Upper "ISO Function Instance; canboat type: UNSIGNED_INTEGER";
CM_ SG_ 2565734400 Device_Function "ISO Function; canboat type: INDIRECT_LOOKUP";
CM_ SG_ 2565734400 Spare "canboat type: SPARE";
CM_ SG_ 2565734400 Device_Class "canboat type: LOOKUP";
CM_ SG_ 2565734400 System_Instance "ISO Device Class Instance; canboat type: UNSIGNED_INTEGER";
CM_ SG_ 2565734400 Industry_Group "canboat type: LOOKUP";
CM_ SG_ 2565734400 Arbitrary_address_capable "Field indicates whether the device is capable to claim arbitrary source address. Value is 1 for NMEA200 devices. Could be 0 for J1939 device claims; canboat type: LOOKUP";
CM_ SG_ 2565799936 Manufacturer_Code "canboat type: LOOKUP";
CM_ SG_ 2565799936 Industry_Code "canboat type: LOOKUP";
CM_ SG_ 2565799936 Data "canboat type: BINARY";
CM_ SG_ 2297364480 Manufacturer_Code "Carling Technologies Inc. (Moritz Aerospace); canboat type: LOOKUP";
CM_ SG_ 2297364480 Industry_Code "Marine Industry; canboat type: LOOKUP";
CM_ SG_ 2297364480 Message_Type "Breaker Command; canboat type: UINT8";
CM_ SG_ 2297364480 Breaker_Mapping_1 "canboat type: UINT8";
CM_ SG_ 2297364480 Breaker_Mapping_2 "canboat type: UINT8";
CM_ SG_ 2297364480 Breaker_Mapping_3 "canboat type: UNSIGNED_INTEGER";
CM_ SG_ 2297364480 Breaker_Command "canboat type: UINT8";
CM_ SG_ 2297364480 Dim_Value "canboat type: UINT8";
CM_ SG_ 2565799936 Manufacturer_Code "Raymarine; canboat type: LOOKUP";
CM_ SG_ 2565799936 Industry_Code "Marine Industry; canboat type: LOOKUP";
CM_ SG_ 2565799936 Proprietary_ID "canboat type: UINT8";
CM_ SG_ 2565799936 Variant "canboat type: UINT8";
CM_ SG_ 2565799936 Beep_Control "canboat type: UINT8";
CM_ SG_ 2565799936 Manufacturer_Code "Raymarine; canboat type: LOOKUP";
CM_ SG_ 2565799936 Industry_Code "Marine Industry; canboat type: LOOKUP";
CM_ SG_ 2565799936 Proprietary_ID "Wireless Keypad Light Control; canboat type: UINT8";
CM_ SG_ 2565799936 Variant "canboat type: UINT8";
CM_ SG_ 2565799936 Wireless_Setting "canboat type: UINT8";
CM_ SG_ 2565799936 Wired_Setting "canboat type: UINT8";
CM_ SG_ 2632908800 Manufacturer_Code "Simrad; canboat type: LOOKUP";
CM_ SG_ 2632908800 Industry_Code "Marine Industry; canboat type: LOOKUP";
CM_ SG_ 2632908800 Command "Command selector; 49 keeps the addressed device awake; canboat type: UNSIGNED_INTEGER";
CM_ SG_ 2632908800 Reply "0 = request, 1 = reply; canboat type: UNSIGNED_INTEGER";
CM_ SG_ 2632908800 Value "Only meaningful in a reply (carries a status); left unset (0xFF) in a request; canboat type: BINARY";
CM_ SG_ 2632908800 Manufacturer_Code "Victron Energy; canboat type: LOOKUP";
CM_ SG_ 2632908800 Industry_Code "Marine Industry; canboat type: LOOKUP";
CM_ SG_ 2632908800 Register_Id "canboat type: DYNAMIC_FIELD_KEY";
CM_ SG_ 2632908800 Value "Register value; its type is selected by Register Id; canboat type: DYNAMIC_FIELD_VALUE";
CM_ SG_ 2565865472 Manufacturer_Code "canboat type: LOOKUP";
CM_ SG_ 2565865472 Industry_Code "canboat type: LOOKUP";
CM_ SG_ 2565865472 Data "canboat type: BINARY";
CM_ SG_ 2365450496 Line_Line_AC_RMS_Voltage "canboat type: VOLTAGE_UFIX16_V";
CM_ SG_ 2365450496 Line_Neutral_AC_RMS_Voltage "canboat type: VOLTAGE_UFIX16_V";
CM_ SG_ 2365450496 AC_Frequency "canboat type: FREQUENCY_UFIX16";
CM_ SG_ 2365450752 Line_Line_AC_RMS_Voltage "canboat type: VOLTAGE_UFIX16_V";
CM_ SG_ 2365450752 Line_Neutral_AC_RMS_Voltage "canboat type: VOLTAGE_UFIX16_V";
CM_ SG_ 2365450752 AC_Frequency "canboat type: FREQUENCY_UFIX16";
CM_ SG_ 2365451008 Line_Line_AC_RMS_Voltage "canboat type: VOLTAGE_UFIX16_V";
CM_ SG_ 2365451008 Line_Neutral_AC_RMS_Voltage "canboat type: VOLTAGE_UFIX16_V";
CM_ SG_ 2365451008 AC_Frequency "canboat type: FREQUENCY_UFIX16";
CM_ SG_ 2365451264 Line_Line_AC_RMS_Voltage "canboat type: VOLTAGE_UFIX16_V";
CM_ SG_ 2365451264 Line_Neutral_AC_RMS_Voltage "canboat type: VOLTAGE_UFIX16_V";
CM_ SG_ 2365451264 AC_Frequency "canboat type: FREQUENCY_UFIX16";
CM_ SG_ 2365451520 Total_Energy_Export "canboat type: ENERGY_UINT32";
CM_ SG_ 2365451520 Total_Energy_Import "canboat type: ENERGY_UINT32";
CM_ SG_ 2365451776 Reactive_Power "canboat type: POWER_UINT16_VAR";
CM_ SG_ 2365451776 Power_factor "canboat type: UINT16";
CM_ SG_ 2365451776 Power_Factor_Lagging "canboat type: LOOKUP";
CM_ SG_ 2365452032 Real_Power "canboat type: POWER_FIX32_OFFSET";
CM_ SG_ 2365452032 Apparent_Power "canboat type: POWER_FIX32_VA_OFFSET";
CM_ SG_ 2365452288 Line_Line_AC_RMS_Voltage "canboat type: VOLTAGE_UFIX16_V";
CM_ SG_ 2365452288 Line_Neutral_AC_RMS_Voltage "canboat type: VOLTAGE_UFIX16_V";
CM_ SG_ 2365452288 AC_Frequency "canboat type: FREQUENCY_UFIX16";
CM_ SG_ 2365452288 AC_RMS_Current "canboat type: CURRENT_UFIX16_A";
CM_ SG_ 2365452544 Reactive_Power "canboat type: POWER_UINT16_VAR";
CM_ SG_ 2365452544 Power_factor "canboat type: UINT16";
CM_ SG_ 2365452544 Power_Factor_Lagging "canboat type: LOOKUP";
CM_ SG_ 2365452800 Real_Power "canboat type: POWER_FIX32_OFFSET";
CM_ SG_ 2365452800 Apparent_Power "canboat type: POWER_FIX32_VA_OFFSET";
CM_ SG_ 2365453056 Line_Line_AC_RMS_Voltage "canboat type: VOLTAGE_UFIX16_V";
CM_ SG_ 2365453056 Line_Neutral_AC_RMS_Voltage "canboat type: VOLTAGE_UFIX16_V";
CM_ SG_ 2365453056 AC_Frequency "canboat type: FREQUENCY_UFIX16";
CM_ SG_ 2365453056 AC_RMS_Current "canboat type: CURRENT_UFIX16_A";
CM_ SG_ 2365453312 Reactive_Power "canboat type: POWER_FIX32_VAR_OFFSET";
CM_ SG_ 2365453312 Power_factor "canboat type: UINT16";
CM_ SG_ 2365453312 Power_Factor_Lagging "canboat type: LOOKUP";
CM_ SG_ 2365453568 Real_Power "canboat type: POWER_FIX32_OFFSET";
CM_ SG_ 2365453568 Apparent_Power "canboat type: POWER_FIX32_VA_OFFSET";
CM_ SG_ 2365453824 Line_Line_AC_RMS_Voltage "canboat type: VOLTAGE_UFIX16_V";
CM_ SG_ 2365453824 Line_Neutral_AC_RMS_Voltage "canboat type: VOLTAGE_UFIX16_V";
CM_ SG_ 2365453824 AC_Frequency "canboat type: FREQUENCY_UFIX16";
CM_ SG_ 2365453824 AC_RMS_Current "canboat type: CURRENT_UFIX16_A";
CM_ SG_ 2365454080 Reactive_Power "canboat type: POWER_FIX32_VAR_OFFSET";
CM_ SG_ 2365454080 Power_factor "canboat type: UINT16";
CM_ SG_ 2365454080 Power_Factor_Lagging "canboat type: LOOKUP";
CM_ SG_ 2365454336 Real_Power "canboat type: POWER_FIX32_OFFSET";
CM_ SG_ 2365454336 Apparent_Power "canboat type: POWER_FIX32_VA_OFFSET";
CM_ SG_ 2365454592 Line_Line_AC_RMS_Voltage "canboat type: VOLTAGE_UFIX16_V";
CM_ SG_ 2365454592 Line_Neutral_AC_RMS_Voltage "canboat type: VOLTAGE_UFIX16_V";
CM_ SG_ 2365454592 AC_Frequency "canboat type: FREQUENCY_UFIX16";
CM_ SG_ 2365454592 AC_RMS_Current "canboat type: CURRENT_UFIX16_A";
CM_ SG_ 2365454848 Total_Energy_Export "canboat type: ENERGY_UINT32";
CM_ SG_ 2365454848 Total_Energy_Import "canboat type: ENERGY_UINT32";
CM_ SG_ 2365455104 Reactive_Power "canboat type: POWER_FIX32_VAR_OFFSET";
CM_ SG_ 2365455104 Power_factor "canboat type: UINT16";
CM_ SG_ 2365455104 Power_Factor_Lagging "canboat type: LOOKUP";
CM_ SG_ 2365455360 Real_Power "canboat type: POWER_FIX32_OFFSET";
CM_ SG_ 2365455360 Apparent_Power "canboat type: POWER_FIX32_VA_OFFSET";
CM_ SG_ 2365455616 Line_Line_AC_RMS_Voltage "canboat type: VOLTAGE_UFIX16_V";
CM_ SG_ 2365455616 Line_Neutral_AC_RMS_Voltage "canboat type: VOLTAGE_UFIX16_V";
CM_ SG_ 2365455616 AC_Frequency "canboat type: FREQUENCY_UFIX16";
CM_ SG_ 2365455616 AC_RMS_Current "canboat type: CURRENT_UFIX16_A";
CM_ SG_ 2365455872 Reactive_Power "canboat type: POWER_FIX32_VAR_OFFSET";
CM_ SG_ 2365455872 Power_factor "canboat type: UINT16";
CM_ SG_ 2365455872 Power_Factor_Lagging "canboat type: LOOKUP";
CM_ SG_ 2365456128 Real_Power "canboat type: POWER_FIX32_OFFSET";
CM_ SG_ 2365456128 Apparent_Power "canboat type: POWER_FIX32_VA_OFFSET";
CM_ SG_ 2365456384 Line_Line_AC_RMS_Voltage "canboat type: VOLTAGE_UFIX16_V";
CM_ SG_ 2365456384 Line_Neutral_AC_RMS_Voltage "canboat type: VOLTAGE_UFIX16_V";
CM_ SG_ 2365456384 AC_Frequency "canboat type: FREQUENCY_UFIX16";
CM_ SG_ 2365456384 AC_RMS_Current "canboat type: CURRENT_UFIX16_A";
CM_ SG_ 2365456640 Reactive_Power "canboat type: POWER_FIX32_VAR_OFFSET";
CM_ SG_ 2365456640 Power_factor "canboat type: UINT16";
CM_ SG_ 2365456640 Power_Factor_Lagging "canboat type: LOOKUP";
CM_ SG_ 2365456896 Real_Power "canboat type: POWER_FIX32_OFFSET";
CM_ SG_ 2365456896 Apparent_Power "canboat type: POWER_FIX32_VA_OFFSET";
CM_ SG_ 2365457152 Line_Line_AC_RMS_Voltage "canboat type: VOLTAGE_UFIX16_V";
CM_ SG_ 2365457152 Line_Neutral_AC_RMS_Voltage "canboat type: VOLTAGE_UFIX16_V";
CM_ SG_ 2365457152 AC_Frequency "canboat type: FREQUENCY_UFIX16";
CM_ SG_ 2365457152 AC_RMS_Current "canboat type: CURRENT_UFIX16_A";
CM_ SG_ 2365457408 Reactive_Power "canboat type: POWER_FIX32_VAR_OFFSET";
CM_ SG_ 2365457408 Power_factor "canboat type: UINT16";
CM_ SG_ 2365457408 Power_Factor_Lagging "canboat type: LOOKUP";
CM_ SG_ 2365457664 Real_Power "canboat type: POWER_FIX32_OFFSET";
CM_ SG_ 2365457664 Apparent_Power "canboat type: POWER_FIX32_VA_OFFSET";
CM_ SG_ 2365457920 Line_Line_AC_RMS_Voltage "canboat type: VOLTAGE_UFIX16_V";
CM_ SG_ 2365457920 Line_Neutral_AC_RMS_Voltage "canboat type: VOLTAGE_UFIX16_V";
CM_ SG_ 2365457920 AC_Frequency "canboat type: FREQUENCY_UFIX16";
CM_ SG_ 2365457920 AC_RMS_Current "canboat type: CURRENT_UFIX16_A";
CM_ SG_ 2566838272 Unique_Number "ISO Identity Number; canboat type: BINARY";
CM_ SG_ 2566838272 Manufacturer_Code "canboat type: LOOKUP";
CM_ SG_ 2566838272 Device_Instance_Lower "ISO ECU Instance; canboat type: UNSIGNED_INTEGER";
CM_ SG_ 2566838272 Device_Instance_Upper "ISO Function Instance; canboat type: UNSIGNED_INTEGER";
CM_ SG_ 2566838272 Device_Function "ISO Function; canboat type: INDIRECT_LOOKUP";
CM_ SG_ 2566838272 Device_Class "canboat type: LOOKUP";
CM_ SG_ 2566838272 System_Instance "ISO Device Class Instance; canboat type: UNSIGNED_INTEGER";
CM_ SG_ 2566838272 Industry_Code "canboat type: LOOKUP";
CM_ SG_ 2566838272 New_Source_Address "canboat type: UINT8";
CM_ SG_ 2566848512 Manufacturer_Code "canboat type: LOOKUP";
CM_ SG_ 2566848512 Industry_Code "canboat type: LOOKUP";
CM_ SG_ 2566848512 Data "canboat type: BINARY";
CM_ SG_ 2365521920 Manufacturer_Code "BEP Marine; canboat type: LOOKUP";
CM_ SG_ 2365521920 Industry_Code "Marine Industry; canboat type: LOOKUP";
CM_ SG_ 2365521920 Circuit_ID "Low 16 bits of the .zcf-stored 32-bit circuit ID; canboat type: UINT16";
CM_ SG_ 2365521920 Field_B "Purpose unknown; observed 0x0000 in all known traffic; canboat type: UINT16";
CM_ SG_ 2365521920 Level_Or_Value "0x1 for ON, 0x2 for OFF; possibly a control mode; canboat type: UNSIGNED_INTEGER";
CM_ SG_ 2365521920 Unknown_A "canboat type: UNSIGNED_INTEGER";
CM_ SG_ 2365521920 Command_Active "Receiver ignores frame if zero; canboat type: UNSIGNED_INTEGER";
CM_ SG_ 2365521920 Unknown_B "canboat type: UNSIGNED_INTEGER";
CM_ SG_ 2365521920 Unknown_C "canboat type: UNSIGNED_INTEGER";
CM_ SG_ 2365521920 Unknown_D "canboat type: UNSIGNED_INTEGER";
CM_ SG_ 2365521920 Unknown_E "canboat type: UNSIGNED_INTEGER";
CM_ SG_ 2365521920 Unknown_F "canboat type: UNSIGNED_INTEGER";
CM_ SG_ 2298413056 Manufacturer_Code "Furuno; canboat type: LOOKUP";
CM_ SG_ 2298413056 Industry_Code "Marine Industry; canboat type: LOOKUP";
CM_ SG_ 2298413056 Heave "canboat type: DISTANCE_FIX32_MM";
CM_ SG_ 2566848512 Manufacturer_Code "Honda Motor; canboat type: LOOKUP";
CM_ SG_ 2566848512 Industry_Code "Marine Industry; canboat type: LOOKUP";
CM_ SG_ 2566848512 Data "canboat type: BINARY";
CM_ SG_ 2566848512 Manufacturer_Code "Maretron; canboat type: LOOKUP";
CM_ SG_ 2566848512 Industry_Code "Marine Industry; canboat type: LOOKUP";
CM_ SG_ 2566848512 Data "canboat type: BINARY";
CM_ SG_ 2566848512 Manufacturer_Code "Mercury Marine; canboat type: LOOKUP";
CM_ SG_ 2566848512 Industry_Code "Marine Industry; canboat type: LOOKUP";
CM_ SG_ 2566848512 Data "canboat type: BINARY";
CM_ SG_ 2633957376 Manufacturer_Code "Navico; canboat type: LOOKUP";
CM_ SG_ 2633957376 Industry_Code "Marine Industry; canboat type: LOOKUP";
CM_ SG_ 2633957376 Report_Type "Tracks the emitting device's software platform: 4 = NOS, 5 = NEON. NOS devices broadcast this roughly four times a second, NEON devices at a much lower rate.; canboat type: UINT8";
CM_ SG_ 2633957376 Data "Payload; constant in all observed traffic; canboat type: BINARY";
CM_ SG_ 2298413056 Manufacturer_Code "Sleipner Motor; canboat type: LOOKUP";
CM_ SG_ 2298413056 Industry_Code "Marine Industry; canboat type: LOOKUP";
CM_ SG_ 2298413056 Thruster_Instance "Selects the thruster (pair) the command applies to; canboat type: UNSIGNED_INTEGER";
CM_ SG_ 2298413056 Direction "canboat type: LOOKUP";
CM_ SG_ 2298413056 Device_Action "canboat type: LOOKUP";
CM_ SG_ 2298413056 Thrust "Commanded thrust, 0 to 100%; canboat type: UNSIGNED_INTEGER";
CM_ SG_ 2298413056 Reserved "Zero in every observed frame, including at full deflection; canboat type: BINARY";
CM_ SG_ 2566848512 Manufacturer_Code "Yanmar Marine; canboat type: LOOKUP";
CM_ SG_ 2566848512 Industry_Code "Marine Industry; canboat type: LOOKUP";
CM_ SG_ 2566848512 Unknown_Selector "Observed as 1; the individual bit semantics are not yet known.; canboat type: UNSIGNED_INTEGER";
CM_ SG_ 2566848512 Engine_Instance "Uses the standard NMEA 2000 engine-instance values; observed as 0 for port and 1 for starboard.; canboat type: LOOKUP";
CM_ SG_ 2566848512 Throttle_Position "Observed control-lever position with 0.1 percent resolution.; canboat type: UNSIGNED_INTEGER";
CM_ SG_ 2566848512 Spare "canboat type: SPARE";
CM_ SG_ 2566848512 Transmission_Gear "Observed as Forward, Neutral, and Reverse, matching PGN 127493 for the corresponding engine instance.; canboat type: LOOKUP";
CM_ SG_ 2566848512 Engine_Speed "Observed whole engine RPM; agrees with PGN 127488 after applying that PGN's 0.25 RPM resolution.; canboat type: UINT16";
CM_ SG_ 2566848512 Unknown_Data "Observed as 0x64.; canboat type: BINARY";
CM_ SG_ 2566848768 Manufacturer_Code "BEP Marine; canboat type: LOOKUP";
CM_ SG_ 2566848768 Industry_Code "Marine Industry; canboat type: LOOKUP";
CM_ SG_ 2566848768 Data "canboat type: BINARY";
CM_ SG_ 2566848768 Manufacturer_Code "Yanmar Marine; canboat type: LOOKUP";
CM_ SG_ 2566848768 Industry_Code "Marine Industry; canboat type: LOOKUP";
CM_ SG_ 2566848768 Data "canboat type: BINARY";
CM_ SG_ 2566849024 Manufacturer_Code "BEP Marine; canboat type: LOOKUP";
CM_ SG_ 2566849024 Industry_Code "Marine Industry; canboat type: LOOKUP";
CM_ SG_ 2566849024 Dipswitch "canboat type: UINT8";
CM_ SG_ 2566849024 Manufacturer_Code "Maretron; canboat type: LOOKUP";
CM_ SG_ 2566849024 Industry_Code "Marine Industry; canboat type: LOOKUP";
CM_ SG_ 2566849024 PGN "PGN for which the number of channels is reported; canboat type: PGN";
CM_ SG_ 2566849024 Number_of_Channels "canboat type: UINT8";

VAL_ 2565341184 Control 0 "ACK" 1 "NAK" 2 "Access Denied" 3 "Address Busy" ;
VAL_ 2565603328 Group_Function_Code 0 "ACK" 16 "RTS" 17 "CTS" 19 "EOM" 32 "BAM" 255 "Abort" ;
VAL_ 2565603328 Group_Function_Code 0 "ACK" 16 "RTS" 17 "CTS" 19 "EOM" 32 "BAM" 255 "Abort" ;
VAL_ 2565603328 Group_Function_Code 0 "ACK" 16 "RTS" 17 "CTS" 19 "EOM" 32 "BAM" 255 "Abort" ;
VAL_ 2565603328 Group_Function_Code 0 "ACK" 16 "RTS" 17 "CTS" 19 "EOM" 32 "BAM" 255 "Abort" ;
VAL_ 2565603328 Group_Function_Code 0 "ACK" 16 "RTS" 17 "CTS" 19 "EOM" 32 "BAM" 255 "Abort" ;
VAL_ 2565734400 Manufacturer_Code 69 "ARKS Enterprises" 78 "FW Murphy/Enovation Controls" 80 "Twin Disc" 85 "Kohler Power Systems" 88 "Hemisphere GPS" 135 "Airmar" 137 "Maretron" 140 "Lowrance" 144 "Mercury Marine" 147 "Nautibus Electronic" 148 "Blue Water Data" 154 "Westerbeke" 157 "ISSPRO" 161 "Offshore Systems (UK)" 163 "Evinrude/BRP" 165 "CPAC Systems" 168 "Xantrex Technology" 169 "Marlin Technologies" 172 "Yanmar Marine" 174 "Volvo Penta" 176 "Carling Technologies Inc. (Moritz Aerospace)" 185 "Beede Instruments" 192 "Floscan Instrument" 193 "Nobeltec" 198 "Mystic Valley Communications" 199 "Actia" 201 "Disenos Y Technologia" 211 "Digital Switching Systems" 215 "Xintex/Atena" 224 "EMMI NETWORK" 228 "ZF" 229 "Garmin" 233 "Yacht Monitoring Solutions" 235 "Sailormade Marine Telemetry/Tetra Technology" 243 "Eride" 257 "Honda Motor" 272 "Groco" 273 "Actisense" 274 "Amphenol LTW Technology" 275 "Navico" 283 "Hamilton Jet" 285 "Sea Recovery" 286 "Coelmo SRL Italy" 295 "BEP Marine" 304 "Empir Bus" 305 "NovAtel" 306 "Sleipner Motor" 307 "MBW Technologies" 315 "ICOM" 328 "Qwerty" 329 "Dief" 341 "Boening Automationstechnologie" 345 "Korean Maritime University" 351 "Thrane and Thrane" 355 "Mastervolt" 356 "Fischer Panda Generators" 358 "Victron Energy" 370 "Rolls Royce Marine" 373 "Electronic Design" 374 "Northern Lights" 378 "Glendinning" 381 "B & G" 384 "Rose Point Navigation Systems" 385 "Johnson Outdoors Marine Electronics Inc Geonav" 394 "Capi 2" 396 "Beyond Measure" 400 "Livorsi Marine" 404 "ComNav" 409 "Chetco" 419 "Fusion Electronics" 421 "Standard Horizon" 422 "True Heading" 426 "Egersund Marine Electronics" 427 "em-trak Marine Electronics" 431 "Tohatsu Co, JP" 437 "Digital Yacht" 438 "Comar Systems Limited" 440 "Cummins" 443 "VDO (aka Continental-Corporation)" 451 "Parker Hannifin aka Village Marine Tech" 459 "Alltek Marine Electronics" 460 "SAN GIORGIO S.E.I.N" 466 "Veethree Electronics & Marine" 470 "SI-TEX Marine Electronics" 471 "Sea Cross Marine" 475 "GME aka Standard Communications" 476 "Humminbird Marine Electronics" 478 "Ocean Sat" 481 "Chetco Digital Instruments" 493 "Watcheye" 499 "Lcj Capteurs" 502 "Attwood Marine" 503 "Naviop S.R.L." 504 "Vesper Marine" 510 "Marinesoft" 513 "Simarine" 517 "NoLand Engineering" 518 "Transas USA" 529 "National Instruments Korea" 530 "National Marine Electronics Association" 532 "Onwa Marine" 540 "Webasto" 571 "Marinecraft (South Korea)" 573 "McMurdo Group aka Orolia" 578 "Advansea" 579 "KVH" 580 "San Jose Technology" 583 "Yacht Control" 586 "Suzuki Motor" 591 "US Coast Guard" 595 "Ship Module aka Customware" 600 "Aquatic AV" 605 "Aventics" 606 "Intellian" 612 "SamwonIT" 614 "Arlt Tecnologies" 637 "Bavaria Yachts" 641 "Diverse Yacht Services" 644 "Wema U.S.A dba KUS" 658 "Shenzhen Jiuzhou Himunication" 688 "Rockford" 699 "Harman International" 704 "JL Audio" 708 "Lars Thrane" 715 "Autonnic" 717 "Yacht Devices" 734 "REAP Systems" 735 "AEM Performance Electronics" 739 "LxNav" 741 "Littelfuse, Inc (formerly Carling Technologies)" 743 "DaeMyung" 744 "Woosung" 748 "ISOTTA IFRA srl" 773 "Clarion US" 776 "HMI Systems" 777 "Ocean Signal" 778 "Seakeeper" 781 "Poly Planar" 785 "Fischer Panda DE" 795 "Broyda Industries" 796 "Canadian Automotive" 797 "Tides Marine" 798 "Lumishore" 799 "Still Water Designs and Audio" 802 "BJ Technologies (Beneteau)" 803 "Gill Sensors" 811 "Blue Water Desalination" 815 "FLIR" 824 "Undheim Systems" 826 "Lewmar" 838 "TeamSurv" 844 "Fell Marine" 847 "Oceanvolt" 862 "Prospec" 868 "Data Panel" 890 "L3 Technologies" 894 "Rhodan Marine Systems" 896 "Nexfour Solutions" 905 "ASA Electronics" 909 "Marines Co (South Korea)" 911 "Nautic-on" 917 "Sentinel" 929 "JL Marine Systems" 930 "Ecotronix" 944 "Zontisa Marine" 951 "EXOR International" 962 "Timbolier Industries" 963 "TJC Micro" 968 "Cox Powertrain" 969 "Blue Seas" 981 "Kobelt Manufacturing" 992 "Blue Ocean IOT" 997 "Xenta Systems" 999 "Signal K" 1004 "Ultraflex" 1008 "Lintest SmartBoat" 1011 "Soundmax" 1020 "Team Italia Marine (Onyx Marine Automation s.r.l)" 1021 "Entratech" 1022 "ITC" 1029 "The Marine Guardian" 1047 "Sonic" 1051 "ProNav" 1053 "Vetus Maxwell INC." 1056 "Lithium Pros" 1059 "Boatrax" 1062 "Marol Co ltd" 1065 "CALYPSO Instruments" 1066 "Spot Zero Water" 1069 "Lithionics Battery" 1070 "Quick-teck Electronics" 1075 "Uniden America" 1083 "Nauticoncept" 1084 "Shadow-Caster LED lighting" 1085 "Wet Sounds" 1088 "E-T-A Circuit Breakers" 1092 "Scheiber" 1100 "Smart Yachts International Limited" 1109 "Dockmate" 1114 "Bobs Machine" 1118 "L3Harris ASV" 1119 "Balmar" 1120 "Elettromedia" 1127 "Electromaax" 1140 "Across Oceans Systems" 1145 "Kiwi Yachting" 1150 "BSB Artificial Intelligence" 1151 "Orca Technologies" 1154 "TBS Electronics" 1158 "Technoton Electroics" 1160 "MG Energy Systems" 1169 "Sea Machine Robotics" 1171 "Vista Manufacturing" 1183 "Zipwake" 1186 "Sailmon" 1192 "Airmoniq Pro Kft" 1194 "Sierra Marine" 1200 "Xinuo Information Technology (Xiamen)" 1218 "Septentrio" 1233 "NKE Marine Electronics" 1238 "SuperTrack Aps" 1239 "Honda Electronics" 1245 "Raritan Engineering" 1249 "Integrated Power Solutions AG" 1260 "Interactive Technologies" 1283 "LTG-Tech" 1299 "Energy Solutions (UK)" 1300 "WATT Fuel Cell" 1302 "Pro Mainer" 1305 "Dragonfly Energy" 1306 "Koden Electronics" 1311 "Humphree" 1316 "Hinkley Yachts" 1317 "Global Marine Management GmbH (GMM)" 1320 "Triskel Marine" 1330 "Warwick Control Technologies" 1331 "Dolphin Charger" 1337 "Barnacle Systems" 1348 "Radian IoT" 1353 "Ocean LED Marine" 1359 "BluNav" 1361 "OVA (Nantong Saiyang Electronics Co., Ltd)" 1368 "RAD Propulsion" 1369 "Electric Yacht" 1372 "Elco Motor Yachts" 1384 "Tecnoseal Foundry S.r.l" 1385 "Pro Charging Systems" 1389 "EVEX" 1398 "Gobius Sensor Technology" 1403 "Arco Marine" 1408 "Lenco Marine" 1413 "Naocontrol" 1417 "Revatek" 1438 "Aeolionics" 1439 "PredictWind" 1440 "Egis Mobile Electric" 1445 "Starboard Yacht Group" 1446 "Roswell Marine" 1451 "ePropulsion (Guangdong ePropulsion Technology Ltd.)" 1452 "Micro-Air" 1453 "Vital Battery" 1458 "Ride Controller" 1460 "Tocaro Blue" 1461 "Vanquish Yachts" 1471 "FT Technologies" 1478 "Alps Alpine" 1481 "E-Force Marine" 1482 "CMC Marine" 1483 "Nanjing Sandemarine Information Technology" 1850 "Teleflex Marine (SeaStar Solutions)" 1851 "Raymarine" 1852 "Navionics" 1853 "Japan Radio" 1854 "Northstar Technologies" 1855 "Furuno" 1856 "Trimble" 1857 "Simrad" 1858 "Litton" 1859 "Kvasar" 1860 "MMP" 1861 "Vector Cantech" 1862 "Yamaha Marine" 1863 "Faria Instruments" ;
VAL_ 2565734400 Device_Class 0 "Reserved for 2000 Use" 10 "System tools" 20 "Safety systems" 25 "Internetwork device" 30 "Electrical Distribution" 35 "Electrical Generation" 40 "Steering and Control surfaces" 50 "Propulsion" 60 "Navigation" 70 "Communication" 75 "Sensor Communication Interface" 80 "Instrumentation/general systems" 85 "External Environment" 90 "Internal Environment" 100 "Deck + cargo + fishing equipment systems" 110 "Human Interface" 120 "Display" 125 "Entertainment" ;
VAL_ 2565734400 Industry_Group 0 "Global" 1 "Highway" 2 "Agriculture" 3 "Construction" 4 "Marine Industry" 5 "Industrial" ;
VAL_ 2565734400 Arbitrary_address_capable 0 "No" 1 "Yes" ;
VAL_ 2565799936 Manufacturer_Code 69 "ARKS Enterprises" 78 "FW Murphy/Enovation Controls" 80 "Twin Disc" 85 "Kohler Power Systems" 88 "Hemisphere GPS" 135 "Airmar" 137 "Maretron" 140 "Lowrance" 144 "Mercury Marine" 147 "Nautibus Electronic" 148 "Blue Water Data" 154 "Westerbeke" 157 "ISSPRO" 161 "Offshore Systems (UK)" 163 "Evinrude/BRP" 165 "CPAC Systems" 168 "Xantrex Technology" 169 "Marlin Technologies" 172 "Yanmar Marine" 174 "Volvo Penta" 176 "Carling Technologies Inc. (Moritz Aerospace)" 185 "Beede Instruments" 192 "Floscan Instrument" 193 "Nobeltec" 198 "Mystic Valley Communications" 199 "Actia" 201 "Disenos Y Technologia" 211 "Digital Switching Systems" 215 "Xintex/Atena" 224 "EMMI NETWORK" 228 "ZF" 229 "Garmin" 233 "Yacht Monitoring Solutions" 235 "Sailormade Marine Telemetry/Tetra Technology" 243 "Eride" 257 "Honda Motor" 272 "Groco" 273 "Actisense" 274 "Amphenol LTW Technology" 275 "Navico" 283 "Hamilton Jet" 285 "Sea Recovery" 286 "Coelmo SRL Italy" 295 "BEP Marine" 304 "Empir Bus" 305 "NovAtel" 306 "Sleipner Motor" 307 "MBW Technologies" 315 "ICOM" 328 "Qwerty" 329 "Dief" 341 "Boening Automationstechnologie" 345 "Korean Maritime University" 351 "Thrane and Thrane" 355 "Mastervolt" 356 "Fischer Panda Generators" 358 "Victron Energy" 370 "Rolls Royce Marine" 373 "Electronic Design" 374 "Northern Lights" 378 "Glendinning" 381 "B & G" 384 "Rose Point Navigation Systems" 385 "Johnson Outdoors Marine Electronics Inc Geonav" 394 "Capi 2" 396 "Beyond Measure" 400 "Livorsi Marine" 404 "ComNav" 409 "Chetco" 419 "Fusion Electronics" 421 "Standard Horizon" 422 "True Heading" 426 "Egersund Marine Electronics" 427 "em-trak Marine Electronics" 431 "Tohatsu Co, JP" 437 "Digital Yacht" 438 "Comar Systems Limited" 440 "Cummins" 443 "VDO (aka Continental-Corporation)" 451 "Parker Hannifin aka Village Marine Tech" 459 "Alltek Marine Electronics" 460 "SAN GIORGIO S.E.I.N" 466 "Veethree Electronics & Marine" 470 "SI-TEX Marine Electronics" 471 "Sea Cross Marine" 475 "GME aka Standard Communications" 476 "Humminbird Marine Electronics" 478 "Ocean Sat" 481 "Chetco Digital Instruments" 493 "Watcheye" 499 "Lcj Capteurs" 502 "Attwood Marine" 503 "Naviop S.R.L." 504 "Vesper Marine" 510 "Marinesoft" 513 "Simarine" 517 "NoLand Engineering" 518 "Transas USA" 529 "National Instruments Korea" 530 "National Marine Electronics Association" 532 "Onwa Marine" 540 "Webasto" 571 "Marinecraft (South Korea)" 573 "McMurdo Group aka Orolia" 578 "Advansea" 579 "KVH" 580 "San Jose Technology" 583 "Yacht Control" 586 "Suzuki Motor" 591 "US Coast Guard" 595 "Ship Module aka Customware" 600 "Aquatic AV" 605 "Aventics" 606 "Intellian" 612 "SamwonIT" 614 "Arlt Tecnologies" 637 "Bavaria Yachts" 641 "Diverse Yacht Services" 644 "Wema U.S.A dba KUS" 658 "Shenzhen Jiuzhou Himunication" 688 "Rockford" 699 "Harman International" 704 "JL Audio" 708 "Lars Thrane" 715 "Autonnic" 717 "Yacht Devices" 734 "REAP Systems" 735 "AEM Performance Electronics" 739 "LxNav" 741 "Littelfuse, Inc (formerly Carling Technologies)" 743 "DaeMyung" 744 "Woosung" 748 "ISOTTA IFRA srl" 773 "Clarion US" 776 "HMI Systems" 777 "Ocean Signal" 778 "Seakeeper" 781 "Poly Planar" 785 "Fischer Panda DE" 795 "Broyda Industries" 796 "Canadian Automotive" 797 "Tides Marine" 798 "Lumishore" 799 "Still Water Designs and Audio" 802 "BJ Technologies (Beneteau)" 803 "Gill Sensors" 811 "Blue Water Desalination" 815 "FLIR" 824 "Undheim Systems" 826 "Lewmar" 838 "TeamSurv" 844 "Fell Marine" 847 "Oceanvolt" 862 "Prospec" 868 "Data Panel" 890 "L3 Technologies" 894 "Rhodan Marine Systems" 896 "Nexfour Solutions" 905 "ASA Electronics" 909 "Marines Co (South Korea)" 911 "Nautic-on" 917 "Sentinel" 929 "JL Marine Systems" 930 "Ecotronix" 944 "Zontisa Marine" 951 "EXOR International" 962 "Timbolier Industries" 963 "TJC Micro" 968 "Cox Powertrain" 969 "Blue Seas" 981 "Kobelt Manufacturing" 992 "Blue Ocean IOT" 997 "Xenta Systems" 999 "Signal K" 1004 "Ultraflex" 1008 "Lintest SmartBoat" 1011 "Soundmax" 1020 "Team Italia Marine (Onyx Marine Automation s.r.l)" 1021 "Entratech" 1022 "ITC" 1029 "The Marine Guardian" 1047 "Sonic" 1051 "ProNav" 1053 "Vetus Maxwell INC." 1056 "Lithium Pros" 1059 "Boatrax" 1062 "Marol Co ltd" 1065 "CALYPSO Instruments" 1066 "Spot Zero Water" 1069 "Lithionics Battery" 1070 "Quick-teck Electronics" 1075 "Uniden America" 1083 "Nauticoncept" 1084 "Shadow-Caster LED lighting" 1085 "Wet Sounds" 1088 "E-T-A Circuit Breakers" 1092 "Scheiber" 1100 "Smart Yachts International Limited" 1109 "Dockmate" 1114 "Bobs Machine" 1118 "L3Harris ASV" 1119 "Balmar" 1120 "Elettromedia" 1127 "Electromaax" 1140 "Across Oceans Systems" 1145 "Kiwi Yachting" 1150 "BSB Artificial Intelligence" 1151 "Orca Technologies" 1154 "TBS Electronics" 1158 "Technoton Electroics" 1160 "MG Energy Systems" 1169 "Sea Machine Robotics" 1171 "Vista Manufacturing" 1183 "Zipwake" 1186 "Sailmon" 1192 "Airmoniq Pro Kft" 1194 "Sierra Marine" 1200 "Xinuo Information Technology (Xiamen)" 1218 "Septentrio" 1233 "NKE Marine Electronics" 1238 "SuperTrack Aps" 1239 "Honda Electronics" 1245 "Raritan Engineering" 1249 "Integrated Power Solutions AG" 1260 "Interactive Technologies" 1283 "LTG-Tech" 1299 "Energy Solutions (UK)" 1300 "WATT Fuel Cell" 1302 "Pro Mainer" 1305 "Dragonfly Energy" 1306 "Koden Electronics" 1311 "Humphree" 1316 "Hinkley Yachts" 1317 "Global Marine Management GmbH (GMM)" 1320 "Triskel Marine" 1330 "Warwick Control Technologies" 1331 "Dolphin Charger" 1337 "Barnacle Systems" 1348 "Radian IoT" 1353 "Ocean LED Marine" 1359 "BluNav" 1361 "OVA (Nantong Saiyang Electronics Co., Ltd)" 1368 "RAD Propulsion" 1369 "Electric Yacht" 1372 "Elco Motor Yachts" 1384 "Tecnoseal Foundry S.r.l" 1385 "Pro Charging Systems" 1389 "EVEX" 1398 "Gobius Sensor Technology" 1403 "Arco Marine" 1408 "Lenco Marine" 1413 "Naocontrol" 1417 "Revatek" 1438 "Aeolionics" 1439 "PredictWind" 1440 "Egis Mobile Electric" 1445 "Starboard Yacht Group" 1446 "Roswell Marine" 1451 "ePropulsion (Guangdong ePropulsion Technology Ltd.)" 1452 "Micro-Air" 1453 "Vital Battery" 1458 "Ride Controller" 1460 "Tocaro Blue" 1461 "Vanquish Yachts" 1471 "FT Technologies" 1478 "Alps Alpine" 1481 "E-Force Marine" 1482 "CMC Marine" 1483 "Nanjing Sandemarine Information Technology" 1850 "Teleflex Marine (SeaStar Solutions)" 1851 "Raymarine" 1852 "Navionics" 1853 "Japan Radio" 1854 "Northstar Technologies" 1855 "Furuno" 1856 "Trimble" 1857 "Simrad" 1858 "Litton" 1859 "Kvasar" 1860 "MMP" 1861 "Vector Cantech" 1862 "Yamaha Marine" 1863 "Faria Instruments" ;
VAL_ 2565799936 Industry_Code 0 "Global" 1 "Highway" 2 "Agriculture" 3 "Construction" 4 "Marine Industry" 5 "Industrial" ;
VAL_ 2297364480 Manufacturer_Code 69 "ARKS Enterprises" 78 "FW Murphy/Enovation Controls" 80 "Twin Disc" 85 "Kohler Power Systems" 88 "Hemisphere GPS" 135 "Airmar" 137 "Maretron" 140 "Lowrance" 144 "Mercury Marine" 147 "Nautibus Electronic" 148 "Blue Water Data" 154 "Westerbeke" 157 "ISSPRO" 161 "Offshore Systems (UK)" 163 "Evinrude/BRP" 165 "CPAC Systems" 168 "Xantrex Technology" 169 "Marlin Technologies" 172 "Yanmar Marine" 174 "Volvo Penta" 176 "Carling Technologies Inc. (Moritz Aerospace)" 185 "Beede Instruments" 192 "Floscan Instrument" 193 "Nobeltec" 198 "Mystic Valley Communications" 199 "Actia" 201 "Disenos Y Technologia" 211 "Digital Switching Systems" 215 "Xintex/Atena" 224 "EMMI NETWORK" 228 "ZF" 229 "Garmin" 233 "Yacht Monitoring Solutions" 235 "Sailormade Marine Telemetry/Tetra Technology" 243 "Eride" 257 "Honda Motor" 272 "Groco" 273 "Actisense" 274 "Amphenol LTW Technology" 275 "Navico" 283 "Hamilton Jet" 285 "Sea Recovery" 286 "Coelmo SRL Italy" 295 "BEP Marine" 304 "Empir Bus" 305 "NovAtel" 306 "Sleipner Motor" 307 "MBW Technologies" 315 "ICOM" 328 "Qwerty" 329 "Dief" 341 "Boening Automationstechnologie" 345 "Korean Maritime University" 351 "Thrane and Thrane" 355 "Mastervolt" 356 "Fischer Panda Generators" 358 "Victron Energy" 370 "Rolls Royce Marine" 373 "Electronic Design" 374 "Northern Lights" 378 "Glendinning" 381 "B & G" 384 "Rose Point Navigation Systems" 385 "Johnson Outdoors Marine Electronics Inc Geonav" 394 "Capi 2" 396 "Beyond Measure" 400 "Livorsi Marine" 404 "ComNav" 409 "Chetco" 419 "Fusion Electronics" 421 "Standard Horizon" 422 "True Heading" 426 "Egersund Marine Electronics" 427 "em-trak Marine Electronics" 431 "Tohatsu Co, JP" 437 "Digital Yacht" 438 "Comar Systems Limited" 440 "Cummins" 443 "VDO (aka Continental-Corporation)" 451 "Parker Hannifin aka Village Marine Tech" 459 "Alltek Marine Electronics" 460 "SAN GIORGIO S.E.I.N" 466 "Veethree Electronics & Marine" 470 "SI-TEX Marine Electronics" 471 "Sea Cross Marine" 475 "GME aka Standard Communications" 476 "Humminbird Marine Electronics" 478 "Ocean Sat" 481 "Chetco Digital Instruments" 493 "Watcheye" 499 "Lcj Capteurs" 502 "Attwood Marine" 503 "Naviop S.R.L." 504 "Vesper Marine" 510 "Marinesoft" 513 "Simarine" 517 "NoLand Engineering" 518 "Transas USA" 529 "National Instruments Korea" 530 "National Marine Electronics Association" 532 "Onwa Marine" 540 "Webasto" 571 "Marinecraft (South Korea)" 573 "McMurdo Group aka Orolia" 578 "Advansea" 579 "KVH" 580 "San Jose Technology" 583 "Yacht Control" 586 "Suzuki Motor" 591 "US Coast Guard" 595 "Ship Module aka Customware" 600 "Aquatic AV" 605 "Aventics" 606 "Intellian" 612 "SamwonIT" 614 "Arlt Tecnologies" 637 "Bavaria Yachts" 641 "Diverse Yacht Services" 644 "Wema U.S.A dba KUS" 658 "Shenzhen Jiuzhou Himunication" 688 "Rockford" 699 "Harman International" 704 "JL Audio" 708 "Lars Thrane" 715 "Autonnic" 717 "Yacht Devices" 734 "REAP Systems" 735 "AEM Performance Electronics" 739 "LxNav" 741 "Littelfuse, Inc (formerly Carling Technologies)" 743 "DaeMyung" 744 "Woosung" 748 "ISOTTA IFRA srl" 773 "Clarion US" 776 "HMI Systems" 777 "Ocean Signal" 778 "Seakeeper" 781 "Poly Planar" 785 "Fischer Panda DE" 795 "Broyda Industries" 796 "Canadian Automotive" 797 "Tides Marine" 798 "Lumishore" 799 "Still Water Designs and Audio" 802 "BJ Technologies (Beneteau)" 803 "Gill Sensors" 811 "Blue Water Desalination" 815 "FLIR" 824 "Undheim Systems" 826 "Lewmar" 838 "TeamSurv" 844 "Fell Marine" 847 "Oceanvolt" 862 "Prospec" 868 "Data Panel" 890 "L3 Technologies" 894 "Rhodan Marine Systems" 896 "Nexfour Solutions" 905 "ASA Electronics" 909 "Marines Co (South Korea)" 911 "Nautic-on" 917 "Sentinel" 929 "JL Marine Systems" 930 "Ecotronix" 944 "Zontisa Marine" 951 "EXOR International" 962 "Timbolier Industries" 963 "TJC Micro" 968 "Cox Powertrain" 969 "Blue Seas" 981 "Kobelt Manufacturing" 992 "Blue Ocean IOT" 997 "Xenta Systems" 999 "Signal K" 1004 "Ultraflex" 1008 "Lintest SmartBoat" 1011 "Soundmax" 1020 "Team Italia Marine (Onyx Marine Automation s.r.l)" 1021 "Entratech" 1022 "ITC" 1029 "The Marine Guardian" 1047 "Sonic" 1051 "ProNav" 1053 "Vetus Maxwell INC." 1056 "Lithium Pros" 1059 "Boatrax" 1062 "Marol Co ltd" 1065 "CALYPSO Instruments" 1066 "Spot Zero Water" 1069 "Lithionics Battery" 1070 "Quick-teck Electronics" 1075 "Uniden America" 1083 "Nauticoncept" 1084 "Shadow-Caster LED lighting" 1085 "Wet Sounds" 1088 "E-T-A Circuit Breakers" 1092 "Scheiber" 1100 "Smart Yachts International Limited" 1109 "Dockmate" 1114 "Bobs Machine" 1118 "L3Harris ASV" 1119 "Balmar" 1120 "Elettromedia" 1127 "Electromaax" 1140 "Across Oceans Systems" 1145 "Kiwi Yachting" 1150 "BSB Artificial Intelligence" 1151 "Orca Technologies" 1154 "TBS Electronics" 1158 "Technoton Electroics" 1160 "MG Energy Systems" 1169 "Sea Machine Robotics" 1171 "Vista Manufacturing" 1183 "Zipwake" 1186 "Sailmon" 1192 "Airmoniq Pro Kft" 1194 "Sierra Marine" 1200 "Xinuo Information Technology (Xiamen)" 1218 "Septentrio" 1233 "NKE Marine Electronics" 1238 "SuperTrack Aps" 1239 "Honda Electronics" 1245 "Raritan Engineering" 1249 "Integrated Power Solutions AG" 1260 "Interactive Technologies" 1283 "LTG-Tech" 1299 "Energy Solutions (UK)" 1300 "WATT Fuel Cell" 1302 "Pro Mainer" 1305 "Dragonfly Energy" 1306 "Koden Electronics" 1311 "Humphree" 1316 "Hinkley Yachts" 1317 "Global Marine Management GmbH (GMM)" 1320 "Triskel Marine" 1330 "Warwick Control Technologies" 1331 "Dolphin Charger" 1337 "Barnacle Systems" 1348 "Radian IoT" 1353 "Ocean LED Marine" 1359 "BluNav" 1361 "OVA (Nantong Saiyang Electronics Co., Ltd)" 1368 "RAD Propulsion" 1369 "Electric Yacht" 1372 "Elco Motor Yachts" 1384 "Tecnoseal Foundry S.r.l" 1385 "Pro Charging Systems" 1389 "EVEX" 1398 "Gobius Sensor Technology" 1403 "Arco Marine" 1408 "Lenco Marine" 1413 "Naocontrol" 1417 "Revatek" 1438 "Aeolionics" 1439 "PredictWind" 1440 "Egis Mobile Electric" 1445 "Starboard Yacht Group" 1446 "Roswell Marine" 1451 "ePropulsion (Guangdong ePropulsion Technology Ltd.)" 1452 "Micro-Air" 1453 "Vital Battery" 1458 "Ride Controller" 1460 "Tocaro Blue" 1461 "Vanquish Yachts" 1471 "FT Technologies" 1478 "Alps Alpine" 1481 "E-Force Marine" 1482 "CMC Marine" 1483 "Nanjing Sandemarine Information Technology" 1850 "Teleflex Marine (SeaStar Solutions)" 1851 "Raymarine" 1852 "Navionics" 1853 "Japan Radio" 1854 "Northstar Technologies" 1855 "Furuno" 1856 "Trimble" 1857 "Simrad" 1858 "Litton" 1859 "Kvasar" 1860 "MMP" 1861 "Vector Cantech" 1862 "Yamaha Marine" 1863 "Faria Instruments" ;
VAL_ 2297364480 Industry_Code 0 "Global" 1 "Highway" 2 "Agriculture" 3 "Construction" 4 "Marine Industry" 5 "Industrial" ;
VAL_ 2565799936 Manufacturer_Code 69 "ARKS Enterprises" 78 "FW Murphy/Enovation Controls" 80 "Twin Disc" 85 "Kohler Power Systems" 88 "Hemisphere GPS" 135 "Airmar" 137 "Maretron" 140 "Lowrance" 144 "Mercury Marine" 147 "Nautibus Electronic" 148 "Blue Water Data" 154 "Westerbeke" 157 "ISSPRO" 161 "Offshore Systems (UK)" 163 "Evinrude/BRP" 165 "CPAC Systems" 168 "Xantrex Technology" 169 "Marlin Technologies" 172 "Yanmar Marine" 174 "Volvo Penta" 176 "Carling Technologies Inc. (Moritz Aerospace)" 185 "Beede Instruments" 192 "Floscan Instrument" 193 "Nobeltec" 198 "Mystic Valley Communications" 199 "Actia" 201 "Disenos Y Technologia" 211 "Digital Switching Systems" 215 "Xintex/Atena" 224 "EMMI NETWORK" 228 "ZF" 229 "Garmin" 233 "Yacht Monitoring Solutions" 235 "Sailormade Marine Telemetry/Tetra Technology" 243 "Eride" 257 "Honda Motor" 272 "Groco" 273 "Actisense" 274 "Amphenol LTW Technology" 275 "Navico" 283 "Hamilton Jet" 285 "Sea Recovery" 286 "Coelmo SRL Italy" 295 "BEP Marine" 304 "Empir Bus" 305 "NovAtel" 306 "Sleipner Motor" 307 "MBW Technologies" 315 "ICOM" 328 "Qwerty" 329 "Dief" 341 "Boening Automationstechnologie" 345 "Korean Maritime University" 351 "Thrane and Thrane" 355 "Mastervolt" 356 "Fischer Panda Generators" 358 "Victron Energy" 370 "Rolls Royce Marine" 373 "Electronic Design" 374 "Northern Lights" 378 "Glendinning" 381 "B & G" 384 "Rose Point Navigation Systems" 385 "Johnson Outdoors Marine Electronics Inc Geonav" 394 "Capi 2" 396 "Beyond Measure" 400 "Livorsi Marine" 404 "ComNav" 409 "Chetco" 419 "Fusion Electronics" 421 "Standard Horizon" 422 "True Heading" 426 "Egersund Marine Electronics" 427 "em-trak Marine Electronics" 431 "Tohatsu Co, JP" 437 "Digital Yacht" 438 "Comar Systems Limited" 440 "Cummins" 443 "VDO (aka Continental-Corporation)" 451 "Parker Hannifin aka Village Marine Tech" 459 "Alltek Marine Electronics" 460 "SAN GIORGIO S.E.I.N" 466 "Veethree Electronics & Marine" 470 "SI-TEX Marine Electronics" 471 "Sea Cross Marine" 475 "GME aka Standard Communications" 476 "Humminbird Marine Electronics" 478 "Ocean Sat" 481 "Chetco Digital Instruments" 493 "Watcheye" 499 "Lcj Capteurs" 502 "Attwood Marine" 503 "Naviop S.R.L." 504 "Vesper Marine" 510 "Marinesoft" 513 "Simarine" 517 "NoLand Engineering" 518 "Transas USA" 529 "National Instruments Korea" 530 "National Marine Electronics Association" 532 "Onwa Marine" 540 "Webasto" 571 "Marinecraft (South Korea)" 573 "McMurdo Group aka Orolia" 578 "Advansea" 579 "KVH" 580 "San Jose Technology" 583 "Yacht Control" 586 "Suzuki Motor" 591 "US Coast Guard" 595 "Ship Module aka Customware" 600 "Aquatic AV" 605 "Aventics" 606 "Intellian" 612 "SamwonIT" 614 "Arlt Tecnologies" 637 "Bavaria Yachts" 641 "Diverse Yacht Services" 644 "Wema U.S.A dba KUS" 658 "Shenzhen Jiuzhou Himunication" 688 "Rockford" 699 "Harman International" 704 "JL Audio" 708 "Lars Thrane" 715 "Autonnic" 717 "Yacht Devices" 734 "REAP Systems" 735 "AEM Performance Electronics" 739 "LxNav" 741 "Littelfuse, Inc (formerly Carling Technologies)" 743 "DaeMyung" 744 "Woosung" 748 "ISOTTA IFRA srl" 773 "Clarion US" 776 "HMI Systems" 777 "Ocean Signal" 778 "Seakeeper" 781 "Poly Planar" 785 "Fischer Panda DE" 795 "Broyda Industries" 796 "Canadian Automotive" 797 "Tides Marine" 798 "Lumishore" 799 "Still Water Designs and Audio" 802 "BJ Technologies (Beneteau)" 803 "Gill Sensors" 811 "Blue Water Desalination" 815 "FLIR" 824 "Undheim Systems" 826 "Lewmar" 838 "TeamSurv" 844 "Fell Marine" 847 "Oceanvolt" 862 "Prospec" 868 "Data Panel" 890 "L3 Technologies" 894 "Rhodan Marine Systems" 896 "Nexfour Solutions" 905 "ASA Electronics" 909 "Marines Co (South Korea)" 911 "Nautic-on" 917 "Sentinel" 929 "JL Marine Systems" 930 "Ecotronix" 944 "Zontisa Marine" 951 "EXOR International" 962 "Timbolier Industries" 963 "TJC Micro" 968 "Cox Powertrain" 969 "Blue Seas" 981 "Kobelt Manufacturing" 992 "Blue Ocean IOT" 997 "Xenta Systems" 999 "Signal K" 1004 "Ultraflex" 1008 "Lintest SmartBoat" 1011 "Soundmax" 1020 "Team Italia Marine (Onyx Marine Automation s.r.l)" 1021 "Entratech" 1022 "ITC" 1029 "The Marine Guardian" 1047 "Sonic" 1051 "ProNav" 1053 "Vetus Maxwell INC." 1056 "Lithium Pros" 1059 "Boatrax" 1062 "Marol Co ltd" 1065 "CALYPSO Instruments" 1066 "Spot Zero Water" 1069 "Lithionics Battery" 1070 "Quick-teck Electronics" 1075 "Uniden America" 1083 "Nauticoncept" 1084 "Shadow-Caster LED lighting" 1085 "Wet Sounds" 1088 "E-T-A Circuit Breakers" 1092 "Scheiber" 1100 "Smart Yachts International Limited" 1109 "Dockmate" 1114 "Bobs Machine" 1118 "L3Harris ASV" 1119 "Balmar" 1120 "Elettromedia" 1127 "Electromaax" 1140 "Across Oceans Systems" 1145 "Kiwi Yachting" 1150 "BSB Artificial Intelligence" 1151 "Orca Technologies" 1154 "TBS Electronics" 1158 "Technoton Electroics" 1160 "MG Energy Systems" 1169 "Sea Machine Robotics" 1171 "Vista Manufacturing" 1183 "Zipwake" 1186 "Sailmon" 1192 "Airmoniq Pro Kft" 1194 "Sierra Marine" 1200 "Xinuo Information Technology (Xiamen)" 1218 "Septentrio" 1233 "NKE Marine Electronics" 1238 "SuperTrack Aps" 1239 "Honda Electronics" 1245 "Raritan Engineering" 1249 "Integrated Power Solutions AG" 1260 "Interactive Technologies" 1283 "LTG-Tech" 1299 "Energy Solutions (UK)" 1300 "WATT Fuel Cell" 1302 "Pro Mainer" 1305 "Dragonfly Energy" 1306 "Koden Electronics" 1311 "Humphree" 1316 "Hinkley Yachts" 1317 "Global Marine Management GmbH (GMM)" 1320 "Triskel Marine" 1330 "Warwick Control Technologies" 1331 "Dolphin Charger" 1337 "Barnacle Systems" 1348 "Radian IoT" 1353 "Ocean LED Marine" 1359 "BluNav" 1361 "OVA (Nantong Saiyang Electronics Co., Ltd)" 1368 "RAD Propulsion" 1369 "Electric Yacht" 1372 "Elco Motor Yachts" 1384 "Tecnoseal Foundry S.r.l" 1385 "Pro Charging Systems" 1389 "EVEX" 1398 "Gobius Sensor Technology" 1403 "Arco Marine" 1408 "Lenco Marine" 1413 "Naocontrol" 1417 "Revatek" 1438 "Aeolionics" 1439 "PredictWind" 1440 "Egis Mobile Electric" 1445 "Starboard Yacht Group" 1446 "Roswell Marine" 1451 "ePropulsion (Guangdong ePropulsion Technology Ltd.)" 1452 "Micro-Air" 1453 "Vital Battery" 1458 "Ride Controller" 1460 "Tocaro Blue" 1461 "Vanquish Yachts" 1471 "FT Technologies" 1478 "Alps Alpine" 1481 "E-Force Marine" 1482 "CMC Marine" 1483 "Nanjing Sandemarine Information Technology" 1850 "Teleflex Marine (SeaStar Solutions)" 1851 "Raymarine" 1852 "Navionics" 1853 "Japan Radio" 1854 "Northstar Technologies" 1855 "Furuno" 1856 "Trimble" 1857 "Simrad" 1858 "Litton" 1859 "Kvasar" 1860 "MMP" 1861 "Vector Cantech" 1862 "Yamaha Marine" 1863 "Faria Instruments" ;
VAL_ 2565799936 Industry_Code 0 "Global" 1 "Highway" 2 "Agriculture" 3 "Construction" 4 "Marine Industry" 5 "Industrial" ;
VAL_ 2565799936 Manufacturer_Code 69 "ARKS Enterprises" 78 "FW Murphy/Enovation Controls" 80 "Twin Disc" 85 "Kohler Power Systems" 88 "Hemisphere GPS" 135 "Airmar" 137 "Maretron" 140 "Lowrance" 144 "Mercury Marine" 147 "Nautibus Electronic" 148 "Blue Water Data" 154 "Westerbeke" 157 "ISSPRO" 161 "Offshore Systems (UK)" 163 "Evinrude/BRP" 165 "CPAC Systems" 168 "Xantrex Technology" 169 "Marlin Technologies" 172 "Yanmar Marine" 174 "Volvo Penta" 176 "Carling Technologies Inc. (Moritz Aerospace)" 185 "Beede Instruments" 192 "Floscan Instrument" 193 "Nobeltec" 198 "Mystic Valley Communications" 199 "Actia" 201 "Disenos Y Technologia" 211 "Digital Switching Systems" 215 "Xintex/Atena" 224 "EMMI NETWORK" 228 "ZF" 229 "Garmin" 233 "Yacht Monitoring Solutions" 235 "Sailormade Marine Telemetry/Tetra Technology" 243 "Eride" 257 "Honda Motor" 272 "Groco" 273 "Actisense" 274 "Amphenol LTW Technology" 275 "Navico" 283 "Hamilton Jet" 285 "Sea Recovery" 286 "Coelmo SRL Italy" 295 "BEP Marine" 304 "Empir Bus" 305 "NovAtel" 306 "Sleipner Motor" 307 "MBW Technologies" 315 "ICOM" 328 "Qwerty" 329 "Dief" 341 "Boening Automationstechnologie" 345 "Korean Maritime University" 351 "Thrane and Thrane" 355 "Mastervolt" 356 "Fischer Panda Generators" 358 "Victron Energy" 370 "Rolls Royce Marine" 373 "Electronic Design" 374 "Northern Lights" 378 "Glendinning" 381 "B & G" 384 "Rose Point Navigation Systems" 385 "Johnson Outdoors Marine Electronics Inc Geonav" 394 "Capi 2" 396 "Beyond Measure" 400 "Livorsi Marine" 404 "ComNav" 409 "Chetco" 419 "Fusion Electronics" 421 "Standard Horizon" 422 "True Heading" 426 "Egersund Marine Electronics" 427 "em-trak Marine Electronics" 431 "Tohatsu Co, JP" 437 "Digital Yacht" 438 "Comar Systems Limited" 440 "Cummins" 443 "VDO (aka Continental-Corporation)" 451 "Parker Hannifin aka Village Marine Tech" 459 "Alltek Marine Electronics" 460 "SAN GIORGIO S.E.I.N" 466 "Veethree Electronics & Marine" 470 "SI-TEX Marine Electronics" 471 "Sea Cross Marine" 475 "GME aka Standard Communications" 476 "Humminbird Marine Electronics" 478 "Ocean Sat" 481 "Chetco Digital Instruments" 493 "Watcheye" 499 "Lcj Capteurs" 502 "Attwood Marine" 503 "Naviop S.R.L." 504 "Vesper Marine" 510 "Marinesoft" 513 "Simarine" 517 "NoLand Engineering" 518 "Transas USA" 529 "National Instruments Korea" 530 "National Marine Electronics Association" 532 "Onwa Marine" 540 "Webasto" 571 "Marinecraft (South Korea)" 573 "McMurdo Group aka Orolia" 578 "Advansea" 579 "KVH" 580 "San Jose Technology" 583 "Yacht Control" 586 "Suzuki Motor" 591 "US Coast Guard" 595 "Ship Module aka Customware" 600 "Aquatic AV" 605 "Aventics" 606 "Intellian" 612 "SamwonIT" 614 "Arlt Tecnologies" 637 "Bavaria Yachts" 641 "Diverse Yacht Services" 644 "Wema U.S.A dba KUS" 658 "Shenzhen Jiuzhou Himunication" 688 "Rockford" 699 "Harman International" 704 "JL Audio" 708 "Lars Thrane" 715 "Autonnic" 717 "Yacht Devices" 734 "REAP Systems" 735 "AEM Performance Electronics" 739 "LxNav" 741 "Littelfuse, Inc (formerly Carling Technologies)" 743 "DaeMyung" 744 "Woosung" 748 "ISOTTA IFRA srl" 773 "Clarion US" 776 "HMI Systems" 777 "Ocean Signal" 778 "Seakeeper" 781 "Poly Planar" 785 "Fischer Panda DE" 795 "Broyda Industries" 796 "Canadian Automotive" 797 "Tides Marine" 798 "Lumishore" 799 "Still Water Designs and Audio" 802 "BJ Technologies (Beneteau)" 803 "Gill Sensors" 811 "Blue Water Desalination" 815 "FLIR" 824 "Undheim Systems" 826 "Lewmar" 838 "TeamSurv" 844 "Fell Marine" 847 "Oceanvolt" 862 "Prospec" 868 "Data Panel" 890 "L3 Technologies" 894 "Rhodan Marine Systems" 896 "Nexfour Solutions" 905 "ASA Electronics" 909 "Marines Co (South Korea)" 911 "Nautic-on" 917 "Sentinel" 929 "JL Marine Systems" 930 "Ecotronix" 944 "Zontisa Marine" 951 "EXOR International" 962 "Timbolier Industries" 963 "TJC Micro" 968 "Cox Powertrain" 969 "Blue Seas" 981 "Kobelt Manufacturing" 992 "Blue Ocean IOT" 997 "Xenta Systems" 999 "Signal K" 1004 "Ultraflex" 1008 "Lintest SmartBoat" 1011 "Soundmax" 1020 "Team Italia Marine (Onyx Marine Automation s.r.l)" 1021 "Entratech" 1022 "ITC" 1029 "The Marine Guardian" 1047 "Sonic" 1051 "ProNav" 1053 "Vetus Maxwell INC." 1056 "Lithium Pros" 1059 "Boatrax" 1062 "Marol Co ltd" 1065 "CALYPSO Instruments" 1066 "Spot Zero Water" 1069 "Lithionics Battery" 1070 "Quick-teck Electronics" 1075 "Uniden America" 1083 "Nauticoncept" 1084 "Shadow-Caster LED lighting" 1085 "Wet Sounds" 1088 "E-T-A Circuit Breakers" 1092 "Scheiber" 1100 "Smart Yachts International Limited" 1109 "Dockmate" 1114 "Bobs Machine" 1118 "L3Harris ASV" 1119 "Balmar" 1120 "Elettromedia" 1127 "Electromaax" 1140 "Across Oceans Systems" 1145 "Kiwi Yachting" 1150 "BSB Artificial Intelligence" 1151 "Orca Technologies" 1154 "TBS Electronics" 1158 "Technoton Electroics" 1160 "MG Energy Systems" 1169 "Sea Machine Robotics" 1171 "Vista Manufacturing" 1183 "Zipwake" 1186 "Sailmon" 1192 "Airmoniq Pro Kft" 1194 "Sierra Marine" 1200 "Xinuo Information Technology (Xiamen)" 1218 "Septentrio" 1233 "NKE Marine Electronics" 1238 "SuperTrack Aps" 1239 "Honda Electronics" 1245 "Raritan Engineering" 1249 "Integrated Power Solutions AG" 1260 "Interactive Technologies" 1283 "LTG-Tech" 1299 "Energy Solutions (UK)" 1300 "WATT Fuel Cell" 1302 "Pro Mainer" 1305 "Dragonfly Energy" 1306 "Koden Electronics" 1311 "Humphree" 1316 "Hinkley Yachts" 1317 "Global Marine Management GmbH (GMM)" 1320 "Triskel Marine" 1330 "Warwick Control Technologies" 1331 "Dolphin Charger" 1337 "Barnacle Systems" 1348 "Radian IoT" 1353 "Ocean LED Marine" 1359 "BluNav" 1361 "OVA (Nantong Saiyang Electronics Co., Ltd)" 1368 "RAD Propulsion" 1369 "Electric Yacht" 1372 "Elco Motor Yachts" 1384 "Tecnoseal Foundry S.r.l" 1385 "Pro Charging Systems" 1389 "EVEX" 1398 "Gobius Sensor Technology" 1403 "Arco Marine" 1408 "Lenco Marine" 1413 "Naocontrol" 1417 "Revatek" 1438 "Aeolionics" 1439 "PredictWind" 1440 "Egis Mobile Electric" 1445 "Starboard Yacht Group" 1446 "Roswell Marine" 1451 "ePropulsion (Guangdong ePropulsion Technology Ltd.)" 1452 "Micro-Air" 1453 "Vital Battery" 1458 "Ride Controller" 1460 "Tocaro Blue" 1461 "Vanquish Yachts" 1471 "FT Technologies" 1478 "Alps Alpine" 1481 "E-Force Marine" 1482 "CMC Marine" 1483 "Nanjing Sandemarine Information Technology" 1850 "Teleflex Marine (SeaStar Solutions)" 1851 "Raymarine" 1852 "Navionics" 1853 "Japan Radio" 1854 "Northstar Technologies" 1855 "Furuno" 1856 "Trimble" 1857 "Simrad" 1858 "Litton" 1859 "Kvasar" 1860 "MMP" 1861 "Vector Cantech" 1862 "Yamaha Marine" 1863 "Faria Instruments" ;
VAL_ 2565799936 Industry_Code 0 "Global" 1 "Highway" 2 "Agriculture" 3 "Construction" 4 "Marine Industry" 5 "Industrial" ;
VAL_ 2632908800 Manufacturer_Code 69 "ARKS Enterprises" 78 "FW Murphy/Enovation Controls" 80 "Twin Disc" 85 "Kohler Power Systems" 88 "Hemisphere GPS" 135 "Airmar" 137 "Maretron" 140 "Lowrance" 144 "Mercury Marine" 147 "Nautibus Electronic" 148 "Blue Water Data" 154 "Westerbeke" 157 "ISSPRO" 161 "Offshore Systems (UK)" 163 "Evinrude/BRP" 165 "CPAC Systems" 168 "Xantrex Technology" 169 "Marlin Technologies" 172 "Yanmar Marine" 174 "Volvo Penta" 176 "Carling Technologies Inc. (Moritz Aerospace)" 185 "Beede Instruments" 192 "Floscan Instrument" 193 "Nobeltec" 198 "Mystic Valley Communications" 199 "Actia" 201 "Disenos Y Technologia" 211 "Digital Switching Systems" 215 "Xintex/Atena" 224 "EMMI NETWORK" 228 "ZF" 229 "Garmin" 233 "Yacht Monitoring Solutions" 235 "Sailormade Marine Telemetry/Tetra Technology" 243 "Eride" 257 "Honda Motor" 272 "Groco" 273 "Actisense" 274 "Amphenol LTW Technology" 275 "Navico" 283 "Hamilton Jet" 285 "Sea Recovery" 286 "Coelmo SRL Italy" 295 "BEP Marine" 304 "Empir Bus" 305 "NovAtel" 306 "Sleipner Motor" 307 "MBW Technologies" 315 "ICOM" 328 "Qwerty" 329 "Dief" 341 "Boening Automationstechnologie" 345 "Korean Maritime University" 351 "Thrane and Thrane" 355 "Mastervolt" 356 "Fischer Panda Generators" 358 "Victron Energy" 370 "Rolls Royce Marine" 373 "Electronic Design" 374 "Northern Lights" 378 "Glendinning" 381 "B & G" 384 "Rose Point Navigation Systems" 385 "Johnson Outdoors Marine Electronics Inc Geonav" 394 "Capi 2" 396 "Beyond Measure" 400 "Livorsi Marine" 404 "ComNav" 409 "Chetco" 419 "Fusion Electronics" 421 "Standard Horizon" 422 "True Heading" 426 "Egersund Marine Electronics" 427 "em-trak Marine Electronics" 431 "Tohatsu Co, JP" 437 "Digital Yacht" 438 "Comar Systems Limited" 440 "Cummins" 443 "VDO (aka Continental-Corporation)" 451 "Parker Hannifin aka Village Marine Tech" 459 "Alltek Marine Electronics" 460 "SAN GIORGIO S.E.I.N" 466 "Veethree Electronics & Marine" 470 "SI-TEX Marine Electronics" 471 "Sea Cross Marine" 475 "GME aka Standard Communications" 476 "Humminbird Marine Electronics" 478 "Ocean Sat" 481 "Chetco Digital Instruments" 493 "Watcheye" 499 "Lcj Capteurs" 502 "Attwood Marine" 503 "Naviop S.R.L." 504 "Vesper Marine" 510 "Marinesoft" 513 "Simarine" 517 "NoLand Engineering" 518 "Transas USA" 529 "National Instruments Korea" 530 "National Marine Electronics Association" 532 "Onwa Marine" 540 "Webasto" 571 "Marinecraft (South Korea)" 573 "McMurdo Group aka Orolia" 578 "Advansea" 579 "KVH" 580 "San Jose Technology" 583 "Yacht Control" 586 "Suzuki Motor" 591 "US Coast Guard" 595 "Ship Module aka Customware" 600 "Aquatic AV" 605 "Aventics" 606 "Intellian" 612 "SamwonIT" 614 "Arlt Tecnologies" 637 "Bavaria Yachts" 641 "Diverse Yacht Services" 644 "Wema U.S.A dba KUS" 658 "Shenzhen Jiuzhou Himunication" 688 "Rockford" 699 "Harman International" 704 "JL Audio" 708 "Lars Thrane" 715 "Autonnic" 717 "Yacht Devices" 734 "REAP Systems" 735 "AEM Performance Electronics" 739 "LxNav" 741 "Littelfuse, Inc (formerly Carling Technologies)" 743 "DaeMyung" 744 "Woosung" 748 "ISOTTA IFRA srl" 773 "Clarion US" 776 "HMI Systems" 777 "Ocean Signal" 778 "Seakeeper" 781 "Poly Planar" 785 "Fischer Panda DE" 795 "Broyda Industries" 796 "Canadian Automotive" 797 "Tides Marine" 798 "Lumishore" 799 "Still Water Designs and Audio" 802 "BJ Technologies (Beneteau)" 803 "Gill Sensors" 811 "Blue Water Desalination" 815 "FLIR" 824 "Undheim Systems" 826 "Lewmar" 838 "TeamSurv" 844 "Fell Marine" 847 "Oceanvolt" 862 "Prospec" 868 "Data Panel" 890 "L3 Technologies" 894 "Rhodan Marine Systems" 896 "Nexfour Solutions" 905 "ASA Electronics" 909 "Marines Co (South Korea)" 911 "Nautic-on" 917 "Sentinel" 929 "JL Marine Systems" 930 "Ecotronix" 944 "Zontisa Marine" 951 "EXOR International" 962 "Timbolier Industries" 963 "TJC Micro" 968 "Cox Powertrain" 969 "Blue Seas" 981 "Kobelt Manufacturing" 992 "Blue Ocean IOT" 997 "Xenta Systems" 999 "Signal K" 1004 "Ultraflex" 1008 "Lintest SmartBoat" 1011 "Soundmax" 1020 "Team Italia Marine (Onyx Marine Automation s.r.l)" 1021 "Entratech" 1022 "ITC" 1029 "The Marine Guardian" 1047 "Sonic" 1051 "ProNav" 1053 "Vetus Maxwell INC." 1056 "Lithium Pros" 1059 "Boatrax" 1062 "Marol Co ltd" 1065 "CALYPSO Instruments" 1066 "Spot Zero Water" 1069 "Lithionics Battery" 1070 "Quick-teck Electronics" 1075 "Uniden America" 1083 "Nauticoncept" 1084 "Shadow-Caster LED lighting" 1085 "Wet Sounds" 1088 "E-T-A Circuit Breakers" 1092 "Scheiber" 1100 "Smart Yachts International Limited" 1109 "Dockmate" 1114 "Bobs Machine" 1118 "L3Harris ASV" 1119 "Balmar" 1120 "Elettromedia" 1127 "Electromaax" 1140 "Across Oceans Systems" 1145 "Kiwi Yachting" 1150 "BSB Artificial Intelligence" 1151 "Orca Technologies" 1154 "TBS Electronics" 1158 "Technoton Electroics" 1160 "MG Energy Systems" 1169 "Sea Machine Robotics" 1171 "Vista Manufacturing" 1183 "Zipwake" 1186 "Sailmon" 1192 "Airmoniq Pro Kft" 1194 "Sierra Marine" 1200 "Xinuo Information Technology (Xiamen)" 1218 "Septentrio" 1233 "NKE Marine Electronics" 1238 "SuperTrack Aps" 1239 "Honda Electronics" 1245 "Raritan Engineering" 1249 "Integrated Power Solutions AG" 1260 "Interactive Technologies" 1283 "LTG-Tech" 1299 "Energy Solutions (UK)" 1300 "WATT Fuel Cell" 1302 "Pro Mainer" 1305 "Dragonfly Energy" 1306 "Koden Electronics" 1311 "Humphree" 1316 "Hinkley Yachts" 1317 "Global Marine Management GmbH (GMM)" 1320 "Triskel Marine" 1330 "Warwick Control Technologies" 1331 "Dolphin Charger" 1337 "Barnacle Systems" 1348 "Radian IoT" 1353 "Ocean LED Marine" 1359 "BluNav" 1361 "OVA (Nantong Saiyang Electronics Co., Ltd)" 1368 "RAD Propulsion" 1369 "Electric Yacht" 1372 "Elco Motor Yachts" 1384 "Tecnoseal Foundry S.r.l" 1385 "Pro Charging Systems" 1389 "EVEX" 1398 "Gobius Sensor Technology" 1403 "Arco Marine" 1408 "Lenco Marine" 1413 "Naocontrol" 1417 "Revatek" 1438 "Aeolionics" 1439 "PredictWind" 1440 "Egis Mobile Electric" 1445 "Starboard Yacht Group" 1446 "Roswell Marine" 1451 "ePropulsion (Guangdong ePropulsion Technology Ltd.)" 1452 "Micro-Air" 1453 "Vital Battery" 1458 "Ride Controller" 1460 "Tocaro Blue" 1461 "Vanquish Yachts" 1471 "FT Technologies" 1478 "Alps Alpine" 1481 "E-Force Marine" 1482 "CMC Marine" 1483 "Nanjing Sandemarine Information Technology" 1850 "Teleflex Marine (SeaStar Solutions)" 1851 "Raymarine" 1852 "Navionics" 1853 "Japan Radio" 1854 "Northstar Technologies" 1855 "Furuno" 1856 "Trimble" 1857 "Simrad" 1858 "Litton" 1859 "Kvasar" 1860 "MMP" 1861 "Vector Cantech" 1862 "Yamaha Marine" 1863 "Faria Instruments" ;
VAL_ 2632908800 Industry_Code 0 "Global" 1 "Highway" 2 "Agriculture" 3 "Construction" 4 "Marine Industry" 5 "Industrial" ;
VAL_ 2632908800 Manufacturer_Code 69 "ARKS Enterprises" 78 "FW Murphy/Enovation Controls" 80 "Twin Disc" 85 "Kohler Power Systems" 88 "Hemisphere GPS" 135 "Airmar" 137 "Maretron" 140 "Lowrance" 144 "Mercury Marine" 147 "Nautibus Electronic" 148 "Blue Water Data" 154 "Westerbeke" 157 "ISSPRO" 161 "Offshore Systems (UK)" 163 "Evinrude/BRP" 165 "CPAC Systems" 168 "Xantrex Technology" 169 "Marlin Technologies" 172 "Yanmar Marine" 174 "Volvo Penta" 176 "Carling Technologies Inc. (Moritz Aerospace)" 185 "Beede Instruments" 192 "Floscan Instrument" 193 "Nobeltec" 198 "Mystic Valley Communications" 199 "Actia" 201 "Disenos Y Technologia" 211 "Digital Switching Systems" 215 "Xintex/Atena" 224 "EMMI NETWORK" 228 "ZF" 229 "Garmin" 233 "Yacht Monitoring Solutions" 235 "Sailormade Marine Telemetry/Tetra Technology" 243 "Eride" 257 "Honda Motor" 272 "Groco" 273 "Actisense" 274 "Amphenol LTW Technology" 275 "Navico" 283 "Hamilton Jet" 285 "Sea Recovery" 286 "Coelmo SRL Italy" 295 "BEP Marine" 304 "Empir Bus" 305 "NovAtel" 306 "Sleipner Motor" 307 "MBW Technologies" 315 "ICOM" 328 "Qwerty" 329 "Dief" 341 "Boening Automationstechnologie" 345 "Korean Maritime University" 351 "Thrane and Thrane" 355 "Mastervolt" 356 "Fischer Panda Generators" 358 "Victron Energy" 370 "Rolls Royce Marine" 373 "Electronic Design" 374 "Northern Lights" 378 "Glendinning" 381 "B & G" 384 "Rose Point Navigation Systems" 385 "Johnson Outdoors Marine Electronics Inc Geonav" 394 "Capi 2" 396 "Beyond Measure" 400 "Livorsi Marine" 404 "ComNav" 409 "Chetco" 419 "Fusion Electronics" 421 "Standard Horizon" 422 "True Heading" 426 "Egersund Marine Electronics" 427 "em-trak Marine Electronics" 431 "Tohatsu Co, JP" 437 "Digital Yacht" 438 "Comar Systems Limited" 440 "Cummins" 443 "VDO (aka Continental-Corporation)" 451 "Parker Hannifin aka Village Marine Tech" 459 "Alltek Marine Electronics" 460 "SAN GIORGIO S.E.I.N" 466 "Veethree Electronics & Marine" 470 "SI-TEX Marine Electronics" 471 "Sea Cross Marine" 475 "GME aka Standard Communications" 476 "Humminbird Marine Electronics" 478 "Ocean Sat" 481 "Chetco Digital Instruments" 493 "Watcheye" 499 "Lcj Capteurs" 502 "Attwood Marine" 503 "Naviop S.R.L." 504 "Vesper Marine" 510 "Marinesoft" 513 "Simarine" 517 "NoLand Engineering" 518 "Transas USA" 529 "National Instruments Korea" 530 "National Marine Electronics Association" 532 "Onwa Marine" 540 "Webasto" 571 "Marinecraft (South Korea)" 573 "McMurdo Group aka Orolia" 578 "Advansea" 579 "KVH" 580 "San Jose Technology" 583 "Yacht Control" 586 "Suzuki Motor" 591 "US Coast Guard" 595 "Ship Module aka Customware" 600 "Aquatic AV" 605 "Aventics" 606 "Intellian" 612 "SamwonIT" 614 "Arlt Tecnologies" 637 "Bavaria Yachts" 641 "Diverse Yacht Services" 644 "Wema U.S.A dba KUS" 658 "Shenzhen Jiuzhou Himunication" 688 "Rockford" 699 "Harman International" 704 "JL Audio" 708 "Lars Thrane" 715 "Autonnic" 717 "Yacht Devices" 734 "REAP Systems" 735 "AEM Performance Electronics" 739 "LxNav" 741 "Littelfuse, Inc (formerly Carling Technologies)" 743 "DaeMyung" 744 "Woosung" 748 "ISOTTA IFRA srl" 773 "Clarion US" 776 "HMI Systems" 777 "Ocean Signal" 778 "Seakeeper" 781 "Poly Planar" 785 "Fischer Panda DE" 795 "Broyda Industries" 796 "Canadian Automotive" 797 "Tides Marine" 798 "Lumishore" 799 "Still Water Designs and Audio" 802 "BJ Technologies (Beneteau)" 803 "Gill Sensors" 811 "Blue Water Desalination" 815 "FLIR" 824 "Undheim Systems" 826 "Lewmar" 838 "TeamSurv" 844 "Fell Marine" 847 "Oceanvolt" 862 "Prospec" 868 "Data Panel" 890 "L3 Technologies" 894 "Rhodan Marine Systems" 896 "Nexfour Solutions" 905 "ASA Electronics" 909 "Marines Co (South Korea)" 911 "Nautic-on" 917 "Sentinel" 929 "JL Marine Systems" 930 "Ecotronix" 944 "Zontisa Marine" 951 "EXOR International" 962 "Timbolier Industries" 963 "TJC Micro" 968 "Cox Powertrain" 969 "Blue Seas" 981 "Kobelt Manufacturing" 992 "Blue Ocean IOT" 997 "Xenta Systems" 999 "Signal K" 1004 "Ultraflex" 1008 "Lintest SmartBoat" 1011 "Soundmax" 1020 "Team Italia Marine (Onyx Marine Automation s.r.l)" 1021 "Entratech" 1022 "ITC" 1029 "The Marine Guardian" 1047 "Sonic" 1051 "ProNav" 1053 "Vetus Maxwell INC." 1056 "Lithium Pros" 1059 "Boatrax" 1062 "Marol Co ltd" 1065 "CALYPSO Instruments" 1066 "Spot Zero Water" 1069 "Lithionics Battery" 1070 "Quick-teck Electronics" 1075 "Uniden America" 1083 "Nauticoncept" 1084 "Shadow-Caster LED lighting" 1085 "Wet Sounds" 1088 "E-T-A Circuit Breakers" 1092 "Scheiber" 1100 "Smart Yachts International Limited" 1109 "Dockmate" 1114 "Bobs Machine" 1118 "L3Harris ASV" 1119 "Balmar" 1120 "Elettromedia" 1127 "Electromaax" 1140 "Across Oceans Systems" 1145 "Kiwi Yachting" 1150 "BSB Artificial Intelligence" 1151 "Orca Technologies" 1154 "TBS Electronics" 1158 "Technoton Electroics" 1160 "MG Energy Systems" 1169 "Sea Machine Robotics" 1171 "Vista Manufacturing" 1183 "Zipwake" 1186 "Sailmon" 1192 "Airmoniq Pro Kft" 1194 "Sierra Marine" 1200 "Xinuo Information Technology (Xiamen)" 1218 "Septentrio" 1233 "NKE Marine Electronics" 1238 "SuperTrack Aps" 1239 "Honda Electronics" 1245 "Raritan Engineering" 1249 "Integrated Power Solutions AG" 1260 "Interactive Technologies" 1283 "LTG-Tech" 1299 "Energy Solutions (UK)" 1300 "WATT Fuel Cell" 1302 "Pro Mainer" 1305 "Dragonfly Energy" 1306 "Koden Electronics" 1311 "Humphree" 1316 "Hinkley Yachts" 1317 "Global Marine Management GmbH (GMM)" 1320 "Triskel Marine" 1330 "Warwick Control Technologies" 1331 "Dolphin Charger" 1337 "Barnacle Systems" 1348 "Radian IoT" 1353 "Ocean LED Marine" 1359 "BluNav" 1361 "OVA (Nantong Saiyang Electronics Co., Ltd)" 1368 "RAD Propulsion" 1369 "Electric Yacht" 1372 "Elco Motor Yachts" 1384 "Tecnoseal Foundry S.r.l" 1385 "Pro Charging Systems" 1389 "EVEX" 1398 "Gobius Sensor Technology" 1403 "Arco Marine" 1408 "Lenco Marine" 1413 "Naocontrol" 1417 "Revatek" 1438 "Aeolionics" 1439 "PredictWind" 1440 "Egis Mobile Electric" 1445 "Starboard Yacht Group" 1446 "Roswell Marine" 1451 "ePropulsion (Guangdong ePropulsion Technology Ltd.)" 1452 "Micro-Air" 1453 "Vital Battery" 1458 "Ride Controller" 1460 "Tocaro Blue" 1461 "Vanquish Yachts" 1471 "FT Technologies" 1478 "Alps Alpine" 1481 "E-Force Marine" 1482 "CMC Marine" 1483 "Nanjing Sandemarine Information Technology" 1850 "Teleflex Marine (SeaStar Solutions)" 1851 "Raymarine" 1852 "Navionics" 1853 "Japan Radio" 1854 "Northstar Technologies" 1855 "Furuno" 1856 "Trimble" 1857 "Simrad" 1858 "Litton" 1859 "Kvasar" 1860 "MMP" 1861 "Vector Cantech" 1862 "Yamaha Marine" 1863 "Faria Instruments" ;
VAL_ 2632908800 Industry_Code 0 "Global" 1 "Highway" 2 "Agriculture" 3 "Construction" 4 "Marine Industry" 5 "Industrial" ;
VAL_ 2565865472 Manufacturer_Code 69 "ARKS Enterprises" 78 "FW Murphy/Enovation Controls" 80 "Twin Disc" 85 "Kohler Power Systems" 88 "Hemisphere GPS" 135 "Airmar" 137 "Maretron" 140 "Lowrance" 144 "Mercury Marine" 147 "Nautibus Electronic" 148 "Blue Water Data" 154 "Westerbeke" 157 "ISSPRO" 161 "Offshore Systems (UK)" 163 "Evinrude/BRP" 165 "CPAC Systems" 168 "Xantrex Technology" 169 "Marlin Technologies" 172 "Yanmar Marine" 174 "Volvo Penta" 176 "Carling Technologies Inc. (Moritz Aerospace)" 185 "Beede Instruments" 192 "Floscan Instrument" 193 "Nobeltec" 198 "Mystic Valley Communications" 199 "Actia" 201 "Disenos Y Technologia" 211 "Digital Switching Systems" 215 "Xintex/Atena" 224 "EMMI NETWORK" 228 "ZF" 229 "Garmin" 233 "Yacht Monitoring Solutions" 235 "Sailormade Marine Telemetry/Tetra Technology" 243 "Eride" 257 "Honda Motor" 272 "Groco" 273 "Actisense" 274 "Amphenol LTW Technology" 275 "Navico" 283 "Hamilton Jet" 285 "Sea Recovery" 286 "Coelmo SRL Italy" 295 "BEP Marine" 304 "Empir Bus" 305 "NovAtel" 306 "Sleipner Motor" 307 "MBW Technologies" 315 "ICOM" 328 "Qwerty" 329 "Dief" 341 "Boening Automationstechnologie" 345 "Korean Maritime University" 351 "Thrane and Thrane" 355 "Mastervolt" 356 "Fischer Panda Generators" 358 "Victron Energy" 370 "Rolls Royce Marine" 373 "Electronic Design" 374 "Northern Lights" 378 "Glendinning" 381 "B & G" 384 "Rose Point Navigation Systems" 385 "Johnson Outdoors Marine Electronics Inc Geonav" 394 "Capi 2" 396 "Beyond Measure" 400 "Livorsi Marine" 404 "ComNav" 409 "Chetco" 419 "Fusion Electronics" 421 "Standard Horizon" 422 "True Heading" 426 "Egersund Marine Electronics" 427 "em-trak Marine Electronics" 431 "Tohatsu Co, JP" 437 "Digital Yacht" 438 "Comar Systems Limited" 440 "Cummins" 443 "VDO (aka Continental-Corporation)" 451 "Parker Hannifin aka Village Marine Tech" 459 "Alltek Marine Electronics" 460 "SAN GIORGIO S.E.I.N" 466 "Veethree Electronics & Marine" 470 "SI-TEX Marine Electronics" 471 "Sea Cross Marine" 475 "GME aka Standard Communications" 476 "Humminbird Marine Electronics" 478 "Ocean Sat" 481 "Chetco Digital Instruments" 493 "Watcheye" 499 "Lcj Capteurs" 502 "Attwood Marine" 503 "Naviop S.R.L." 504 "Vesper Marine" 510 "Marinesoft" 513 "Simarine" 517 "NoLand Engineering" 518 "Transas USA" 529 "National Instruments Korea" 530 "National Marine Electronics Association" 532 "Onwa Marine" 540 "Webasto" 571 "Marinecraft (South Korea)" 573 "McMurdo Group aka Orolia" 578 "Advansea" 579 "KVH" 580 "San Jose Technology" 583 "Yacht Control" 586 "Suzuki Motor" 591 "US Coast Guard" 595 "Ship Module aka Customware" 600 "Aquatic AV" 605 "Aventics" 606 "Intellian" 612 "SamwonIT" 614 "Arlt Tecnologies" 637 "Bavaria Yachts" 641 "Diverse Yacht Services" 644 "Wema U.S.A dba KUS" 658 "Shenzhen Jiuzhou Himunication" 688 "Rockford" 699 "Harman International" 704 "JL Audio" 708 "Lars Thrane" 715 "Autonnic" 717 "Yacht Devices" 734 "REAP Systems" 735 "AEM Performance Electronics" 739 "LxNav" 741 "Littelfuse, Inc (formerly Carling Technologies)" 743 "DaeMyung" 744 "Woosung" 748 "ISOTTA IFRA srl" 773 "Clarion US" 776 "HMI Systems" 777 "Ocean Signal" 778 "Seakeeper" 781 "Poly Planar" 785 "Fischer Panda DE" 795 "Broyda Industries" 796 "Canadian Automotive" 797 "Tides Marine" 798 "Lumishore" 799 "Still Water Designs and Audio" 802 "BJ Technologies (Beneteau)" 803 "Gill Sensors" 811 "Blue Water Desalination" 815 "FLIR" 824 "Undheim Systems" 826 "Lewmar" 838 "TeamSurv" 844 "Fell Marine" 847 "Oceanvolt" 862 "Prospec" 868 "Data Panel" 890 "L3 Technologies" 894 "Rhodan Marine Systems" 896 "Nexfour Solutions" 905 "ASA Electronics" 909 "Marines Co (South Korea)" 911 "Nautic-on" 917 "Sentinel" 929 "JL Marine Systems" 930 "Ecotronix" 944 "Zontisa Marine" 951 "EXOR International" 962 "Timbolier Industries" 963 "TJC Micro" 968 "Cox Powertrain" 969 "Blue Seas" 981 "Kobelt Manufacturing" 992 "Blue Ocean IOT" 997 "Xenta Systems" 999 "Signal K" 1004 "Ultraflex" 1008 "Lintest SmartBoat" 1011 "Soundmax" 1020 "Team Italia Marine (Onyx Marine Automation s.r.l)" 1021 "Entratech" 1022 "ITC" 1029 "The Marine Guardian" 1047 "Sonic" 1051 "ProNav" 1053 "Vetus Maxwell INC." 1056 "Lithium Pros" 1059 "Boatrax" 1062 "Marol Co ltd" 1065 "CALYPSO Instruments" 1066 "Spot Zero Water" 1069 "Lithionics Battery" 1070 "Quick-teck Electronics" 1075 "Uniden America" 1083 "Nauticoncept" 1084 "Shadow-Caster LED lighting" 1085 "Wet Sounds" 1088 "E-T-A Circuit Breakers" 1092 "Scheiber" 1100 "Smart Yachts International Limited" 1109 "Dockmate" 1114 "Bobs Machine" 1118 "L3Harris ASV" 1119 "Balmar" 1120 "Elettromedia" 1127 "Electromaax" 1140 "Across Oceans Systems" 1145 "Kiwi Yachting" 1150 "BSB Artificial Intelligence" 1151 "Orca Technologies" 1154 "TBS Electronics" 1158 "Technoton Electroics" 1160 "MG Energy Systems" 1169 "Sea Machine Robotics" 1171 "Vista Manufacturing" 1183 "Zipwake" 1186 "Sailmon" 1192 "Airmoniq Pro Kft" 1194 "Sierra Marine" 1200 "Xinuo Information Technology (Xiamen)" 1218 "Septentrio" 1233 "NKE Marine Electronics" 1238 "SuperTrack Aps" 1239 "Honda Electronics" 1245 "Raritan Engineering" 1249 "Integrated Power Solutions AG" 1260 "Interactive Technologies" 1283 "LTG-Tech" 1299 "Energy Solutions (UK)" 1300 "WATT Fuel Cell" 1302 "Pro Mainer" 1305 "Dragonfly Energy" 1306 "Koden Electronics" 1311 "Humphree" 1316 "Hinkley Yachts" 1317 "Global Marine Management GmbH (GMM)" 1320 "Triskel Marine" 1330 "Warwick Control Technologies" 1331 "Dolphin Charger" 1337 "Barnacle Systems" 1348 "Radian IoT" 1353 "Ocean LED Marine" 1359 "BluNav" 1361 "OVA (Nantong Saiyang Electronics Co., Ltd)" 1368 "RAD Propulsion" 1369 "Electric Yacht" 1372 "Elco Motor Yachts" 1384 "Tecnoseal Foundry S.r.l" 1385 "Pro Charging Systems" 1389 "EVEX" 1398 "Gobius Sensor Technology" 1403 "Arco Marine" 1408 "Lenco Marine" 1413 "Naocontrol" 1417 "Revatek" 1438 "Aeolionics" 1439 "PredictWind" 1440 "Egis Mobile Electric" 1445 "Starboard Yacht Group" 1446 "Roswell Marine" 1451 "ePropulsion (Guangdong ePropulsion Technology Ltd.)" 1452 "Micro-Air" 1453 "Vital Battery" 1458 "Ride Controller" 1460 "Tocaro Blue" 1461 "Vanquish Yachts" 1471 "FT Technologies" 1478 "Alps Alpine" 1481 "E-Force Marine" 1482 "CMC Marine" 1483 "Nanjing Sandemarine Information Technology" 1850 "Teleflex Marine (SeaStar Solutions)" 1851 "Raymarine" 1852 "Navionics" 1853 "Japan Radio" 1854 "Northstar Technologies" 1855 "Furuno" 1856 "Trimble" 1857 "Simrad" 1858 "Litton" 1859 "Kvasar" 1860 "MMP" 1861 "Vector Cantech" 1862 "Yamaha Marine" 1863 "Faria Instruments" ;
VAL_ 2565865472 Industry_Code 0 "Global" 1 "Highway" 2 "Agriculture" 3 "Construction" 4 "Marine Industry" 5 "Industrial" ;
VAL_ 2365451776 Power_Factor_Lagging 0 "Leading" 1 "Lagging" 2 "Error" ;
VAL_ 2365452544 Power_Factor_Lagging 0 "Leading" 1 "Lagging" 2 "Error" ;
VAL_ 2365453312 Power_Factor_Lagging 0 "Leading" 1 "Lagging" 2 "Error" ;
VAL_ 2365454080 Power_Factor_Lagging 0 "Leading" 1 "Lagging" 2 "Error" ;
VAL_ 2365455104 Power_Factor_Lagging 0 "Leading" 1 "Lagging" 2 "Error" ;
VAL_ 2365455872 Power_Factor_Lagging 0 "Leading" 1 "Lagging" 2 "Error" ;
VAL_ 2365456640 Power_Factor_Lagging 0 "Leading" 1 "Lagging" 2 "Error" ;
VAL_ 2365457408 Power_Factor_Lagging 0 "Leading" 1 "Lagging" 2 "Error" ;
VAL_ 2566838272 Manufacturer_Code 69 "ARKS Enterprises" 78 "FW Murphy/Enovation Controls" 80 "Twin Disc" 85 "Kohler Power Systems" 88 "Hemisphere GPS" 135 "Airmar" 137 "Maretron" 140 "Lowrance" 144 "Mercury Marine" 147 "Nautibus Electronic" 148 "Blue Water Data" 154 "Westerbeke" 157 "ISSPRO" 161 "Offshore Systems (UK)" 163 "Evinrude/BRP" 165 "CPAC Systems" 168 "Xantrex Technology" 169 "Marlin Technologies" 172 "Yanmar Marine" 174 "Volvo Penta" 176 "Carling Technologies Inc. (Moritz Aerospace)" 185 "Beede Instruments" 192 "Floscan Instrument" 193 "Nobeltec" 198 "Mystic Valley Communications" 199 "Actia" 201 "Disenos Y Technologia" 211 "Digital Switching Systems" 215 "Xintex/Atena" 224 "EMMI NETWORK" 228 "ZF" 229 "Garmin" 233 "Yacht Monitoring Solutions" 235 "Sailormade Marine Telemetry/Tetra Technology" 243 "Eride" 257 "Honda Motor" 272 "Groco" 273 "Actisense" 274 "Amphenol LTW Technology" 275 "Navico" 283 "Hamilton Jet" 285 "Sea Recovery" 286 "Coelmo SRL Italy" 295 "BEP Marine" 304 "Empir Bus" 305 "NovAtel" 306 "Sleipner Motor" 307 "MBW Technologies" 315 "ICOM" 328 "Qwerty" 329 "Dief" 341 "Boening Automationstechnologie" 345 "Korean Maritime University" 351 "Thrane and Thrane" 355 "Mastervolt" 356 "Fischer Panda Generators" 358 "Victron Energy" 370 "Rolls Royce Marine" 373 "Electronic Design" 374 "Northern Lights" 378 "Glendinning" 381 "B & G" 384 "Rose Point Navigation Systems" 385 "Johnson Outdoors Marine Electronics Inc Geonav" 394 "Capi 2" 396 "Beyond Measure" 400 "Livorsi Marine" 404 "ComNav" 409 "Chetco" 419 "Fusion Electronics" 421 "Standard Horizon" 422 "True Heading" 426 "Egersund Marine Electronics" 427 "em-trak Marine Electronics" 431 "Tohatsu Co, JP" 437 "Digital Yacht" 438 "Comar Systems Limited" 440 "Cummins" 443 "VDO (aka Continental-Corporation)" 451 "Parker Hannifin aka Village Marine Tech" 459 "Alltek Marine Electronics" 460 "SAN GIORGIO S.E.I.N" 466 "Veethree Electronics & Marine" 470 "SI-TEX Marine Electronics" 471 "Sea Cross Marine" 475 "GME aka Standard Communications" 476 "Humminbird Marine Electronics" 478 "Ocean Sat" 481 "Chetco Digital Instruments" 493 "Watcheye" 499 "Lcj Capteurs" 502 "Attwood Marine" 503 "Naviop S.R.L." 504 "Vesper Marine" 510 "Marinesoft" 513 "Simarine" 517 "NoLand Engineering" 518 "Transas USA" 529 "National Instruments Korea" 530 "National Marine Electronics Association" 532 "Onwa Marine" 540 "Webasto" 571 "Marinecraft (South Korea)" 573 "McMurdo Group aka Orolia" 578 "Advansea" 579 "KVH" 580 "San Jose Technology" 583 "Yacht Control" 586 "Suzuki Motor" 591 "US Coast Guard" 595 "Ship Module aka Customware" 600 "Aquatic AV" 605 "Aventics" 606 "Intellian" 612 "SamwonIT" 614 "Arlt Tecnologies" 637 "Bavaria Yachts" 641 "Diverse Yacht Services" 644 "Wema U.S.A dba KUS" 658 "Shenzhen Jiuzhou Himunication" 688 "Rockford" 699 "Harman International" 704 "JL Audio" 708 "Lars Thrane" 715 "Autonnic" 717 "Yacht Devices" 734 "REAP Systems" 735 "AEM Performance Electronics" 739 "LxNav" 741 "Littelfuse, Inc (formerly Carling Technologies)" 743 "DaeMyung" 744 "Woosung" 748 "ISOTTA IFRA srl" 773 "Clarion US" 776 "HMI Systems" 777 "Ocean Signal" 778 "Seakeeper" 781 "Poly Planar" 785 "Fischer Panda DE" 795 "Broyda Industries" 796 "Canadian Automotive" 797 "Tides Marine" 798 "Lumishore" 799 "Still Water Designs and Audio" 802 "BJ Technologies (Beneteau)" 803 "Gill Sensors" 811 "Blue Water Desalination" 815 "FLIR" 824 "Undheim Systems" 826 "Lewmar" 838 "TeamSurv" 844 "Fell Marine" 847 "Oceanvolt" 862 "Prospec" 868 "Data Panel" 890 "L3 Technologies" 894 "Rhodan Marine Systems" 896 "Nexfour Solutions" 905 "ASA Electronics" 909 "Marines Co (South Korea)" 911 "Nautic-on" 917 "Sentinel" 929 "JL Marine Systems" 930 "Ecotronix" 944 "Zontisa Marine" 951 "EXOR International" 962 "Timbolier Industries" 963 "TJC Micro" 968 "Cox Powertrain" 969 "Blue Seas" 981 "Kobelt Manufacturing" 992 "Blue Ocean IOT" 997 "Xenta Systems" 999 "Signal K" 1004 "Ultraflex" 1008 "Lintest SmartBoat" 1011 "Soundmax" 1020 "Team Italia Marine (Onyx Marine Automation s.r.l)" 1021 "Entratech" 1022 "ITC" 1029 "The Marine Guardian" 1047 "Sonic" 1051 "ProNav" 1053 "Vetus Maxwell INC." 1056 "Lithium Pros" 1059 "Boatrax" 1062 "Marol Co ltd" 1065 "CALYPSO Instruments" 1066 "Spot Zero Water" 1069 "Lithionics Battery" 1070 "Quick-teck Electronics" 1075 "Uniden America" 1083 "Nauticoncept" 1084 "Shadow-Caster LED lighting" 1085 "Wet Sounds" 1088 "E-T-A Circuit Breakers" 1092 "Scheiber" 1100 "Smart Yachts International Limited" 1109 "Dockmate" 1114 "Bobs Machine" 1118 "L3Harris ASV" 1119 "Balmar" 1120 "Elettromedia" 1127 "Electromaax" 1140 "Across Oceans Systems" 1145 "Kiwi Yachting" 1150 "BSB Artificial Intelligence" 1151 "Orca Technologies" 1154 "TBS Electronics" 1158 "Technoton Electroics" 1160 "MG Energy Systems" 1169 "Sea Machine Robotics" 1171 "Vista Manufacturing" 1183 "Zipwake" 1186 "Sailmon" 1192 "Airmoniq Pro Kft" 1194 "Sierra Marine" 1200 "Xinuo Information Technology (Xiamen)" 1218 "Septentrio" 1233 "NKE Marine Electronics" 1238 "SuperTrack Aps" 1239 "Honda Electronics" 1245 "Raritan Engineering" 1249 "Integrated Power Solutions AG" 1260 "Interactive Technologies" 1283 "LTG-Tech" 1299 "Energy Solutions (UK)" 1300 "WATT Fuel Cell" 1302 "Pro Mainer" 1305 "Dragonfly Energy" 1306 "Koden Electronics" 1311 "Humphree" 1316 "Hinkley Yachts" 1317 "Global Marine Management GmbH (GMM)" 1320 "Triskel Marine" 1330 "Warwick Control Technologies" 1331 "Dolphin Charger" 1337 "Barnacle Systems" 1348 "Radian IoT" 1353 "Ocean LED Marine" 1359 "BluNav" 1361 "OVA (Nantong Saiyang Electronics Co., Ltd)" 1368 "RAD Propulsion" 1369 "Electric Yacht" 1372 "Elco Motor Yachts" 1384 "Tecnoseal Foundry S.r.l" 1385 "Pro Charging Systems" 1389 "EVEX" 1398 "Gobius Sensor Technology" 1403 "Arco Marine" 1408 "Lenco Marine" 1413 "Naocontrol" 1417 "Revatek" 1438 "Aeolionics" 1439 "PredictWind" 1440 "Egis Mobile Electric" 1445 "Starboard Yacht Group" 1446 "Roswell Marine" 1451 "ePropulsion (Guangdong ePropulsion Technology Ltd.)" 1452 "Micro-Air" 1453 "Vital Battery" 1458 "Ride Controller" 1460 "Tocaro Blue" 1461 "Vanquish Yachts" 1471 "FT Technologies" 1478 "Alps Alpine" 1481 "E-Force Marine" 1482 "CMC Marine" 1483 "Nanjing Sandemarine Information Technology" 1850 "Teleflex Marine (SeaStar Solutions)" 1851 "Raymarine" 1852 "Navionics" 1853 "Japan Radio" 1854 "Northstar Technologies" 1855 "Furuno" 1856 "Trimble" 1857 "Simrad" 1858 "Litton" 1859 "Kvasar" 1860 "MMP" 1861 "Vector Cantech" 1862 "Yamaha Marine" 1863 "Faria Instruments" ;
VAL_ 2566838272 Device_Class 0 "Reserved for 2000 Use" 10 "System tools" 20 "Safety systems" 25 "Internetwork device" 30 "Electrical Distribution" 35 "Electrical Generation" 40 "Steering and Control surfaces" 50 "Propulsion" 60 "Navigation" 70 "Communication" 75 "Sensor Communication Interface" 80 "Instrumentation/general systems" 85 "External Environment" 90 "Internal Environment" 100 "Deck + cargo + fishing equipment systems" 110 "Human Interface" 120 "Display" 125 "Entertainment" ;
VAL_ 2566838272 Industry_Code 0 "Global" 1 "Highway" 2 "Agriculture" 3 "Construction" 4 "Marine Industry" 5 "Industrial" ;
VAL_ 2566848512 Manufacturer_Code 69 "ARKS Enterprises" 78 "FW Murphy/Enovation Controls" 80 "Twin Disc" 85 "Kohler Power Systems" 88 "Hemisphere GPS" 135 "Airmar" 137 "Maretron" 140 "Lowrance" 144 "Mercury Marine" 147 "Nautibus Electronic" 148 "Blue Water Data" 154 "Westerbeke" 157 "ISSPRO" 161 "Offshore Systems (UK)" 163 "Evinrude/BRP" 165 "CPAC Systems" 168 "Xantrex Technology" 169 "Marlin Technologies" 172 "Yanmar Marine" 174 "Volvo Penta" 176 "Carling Technologies Inc. (Moritz Aerospace)" 185 "Beede Instruments" 192 "Floscan Instrument" 193 "Nobeltec" 198 "Mystic Valley Communications" 199 "Actia" 201 "Disenos Y Technologia" 211 "Digital Switching Systems" 215 "Xintex/Atena" 224 "EMMI NETWORK" 228 "ZF" 229 "Garmin" 233 "Yacht Monitoring Solutions" 235 "Sailormade Marine Telemetry/Tetra Technology" 243 "Eride" 257 "Honda Motor" 272 "Groco" 273 "Actisense" 274 "Amphenol LTW Technology" 275 "Navico" 283 "Hamilton Jet" 285 "Sea Recovery" 286 "Coelmo SRL Italy" 295 "BEP Marine" 304 "Empir Bus" 305 "NovAtel" 306 "Sleipner Motor" 307 "MBW Technologies" 315 "ICOM" 328 "Qwerty" 329 "Dief" 341 "Boening Automationstechnologie" 345 "Korean Maritime University" 351 "Thrane and Thrane" 355 "Mastervolt" 356 "Fischer Panda Generators" 358 "Victron Energy" 370 "Rolls Royce Marine" 373 "Electronic Design" 374 "Northern Lights" 378 "Glendinning" 381 "B & G" 384 "Rose Point Navigation Systems" 385 "Johnson Outdoors Marine Electronics Inc Geonav" 394 "Capi 2" 396 "Beyond Measure" 400 "Livorsi Marine" 404 "ComNav" 409 "Chetco" 419 "Fusion Electronics" 421 "Standard Horizon" 422 "True Heading" 426 "Egersund Marine Electronics" 427 "em-trak Marine Electronics" 431 "Tohatsu Co, JP" 437 "Digital Yacht" 438 "Comar Systems Limited" 440 "Cummins" 443 "VDO (aka Continental-Corporation)" 451 "Parker Hannifin aka Village Marine Tech" 459 "Alltek Marine Electronics" 460 "SAN GIORGIO S.E.I.N" 466 "Veethree Electronics & Marine" 470 "SI-TEX Marine Electronics" 471 "Sea Cross Marine" 475 "GME aka Standard Communications" 476 "Humminbird Marine Electronics" 478 "Ocean Sat" 481 "Chetco Digital Instruments" 493 "Watcheye" 499 "Lcj Capteurs" 502 "Attwood Marine" 503 "Naviop S.R.L." 504 "Vesper Marine" 510 "Marinesoft" 513 "Simarine" 517 "NoLand Engineering" 518 "Transas USA" 529 "National Instruments Korea" 530 "National Marine Electronics Association" 532 "Onwa Marine" 540 "Webasto" 571 "Marinecraft (South Korea)" 573 "McMurdo Group aka Orolia" 578 "Advansea" 579 "KVH" 580 "San Jose Technology" 583 "Yacht Control" 586 "Suzuki Motor" 591 "US Coast Guard" 595 "Ship Module aka Customware" 600 "Aquatic AV" 605 "Aventics" 606 "Intellian" 612 "SamwonIT" 614 "Arlt Tecnologies" 637 "Bavaria Yachts" 641 "Diverse Yacht Services" 644 "Wema U.S.A dba KUS" 658 "Shenzhen Jiuzhou Himunication" 688 "Rockford" 699 "Harman International" 704 "JL Audio" 708 "Lars Thrane" 715 "Autonnic" 717 "Yacht Devices" 734 "REAP Systems" 735 "AEM Performance Electronics" 739 "LxNav" 741 "Littelfuse, Inc (formerly Carling Technologies)" 743 "DaeMyung" 744 "Woosung" 748 "ISOTTA IFRA srl" 773 "Clarion US" 776 "HMI Systems" 777 "Ocean Signal" 778 "Seakeeper" 781 "Poly Planar" 785 "Fischer Panda DE" 795 "Broyda Industries" 796 "Canadian Automotive" 797 "Tides Marine" 798 "Lumishore" 799 "Still Water Designs and Audio" 802 "BJ Technologies (Beneteau)" 803 "Gill Sensors" 811 "Blue Water Desalination" 815 "FLIR" 824 "Undheim Systems" 826 "Lewmar" 838 "TeamSurv" 844 "Fell Marine" 847 "Oceanvolt" 862 "Prospec" 868 "Data Panel" 890 "L3 Technologies" 894 "Rhodan Marine Systems" 896 "Nexfour Solutions" 905 "ASA Electronics" 909 "Marines Co (South Korea)" 911 "Nautic-on" 917 "Sentinel" 929 "JL Marine Systems" 930 "Ecotronix" 944 "Zontisa Marine" 951 "EXOR International" 962 "Timbolier Industries" 963 "TJC Micro" 968 "Cox Powertrain" 969 "Blue Seas" 981 "Kobelt Manufacturing" 992 "Blue Ocean IOT" 997 "Xenta Systems" 999 "Signal K" 1004 "Ultraflex" 1008 "Lintest SmartBoat" 1011 "Soundmax" 1020 "Team Italia Marine (Onyx Marine Automation s.r.l)" 1021 "Entratech" 1022 "ITC" 1029 "The Marine Guardian" 1047 "Sonic" 1051 "ProNav" 1053 "Vetus Maxwell INC." 1056 "Lithium Pros" 1059 "Boatrax" 1062 "Marol Co ltd" 1065 "CALYPSO Instruments" 1066 "Spot Zero Water" 1069 "Lithionics Battery" 1070 "Quick-teck Electronics" 1075 "Uniden America" 1083 "Nauticoncept" 1084 "Shadow-Caster LED lighting" 1085 "Wet Sounds" 1088 "E-T-A Circuit Breakers" 1092 "Scheiber" 1100 "Smart Yachts International Limited" 1109 "Dockmate" 1114 "Bobs Machine" 1118 "L3Harris ASV" 1119 "Balmar" 1120 "Elettromedia" 1127 "Electromaax" 1140 "Across Oceans Systems" 1145 "Kiwi Yachting" 1150 "BSB Artificial Intelligence" 1151 "Orca Technologies" 1154 "TBS Electronics" 1158 "Technoton Electroics" 1160 "MG Energy Systems" 1169 "Sea Machine Robotics" 1171 "Vista Manufacturing" 1183 "Zipwake" 1186 "Sailmon" 1192 "Airmoniq Pro Kft" 1194 "Sierra Marine" 1200 "Xinuo Information Technology (Xiamen)" 1218 "Septentrio" 1233 "NKE Marine Electronics" 1238 "SuperTrack Aps" 1239 "Honda Electronics" 1245 "Raritan Engineering" 1249 "Integrated Power Solutions AG" 1260 "Interactive Technologies" 1283 "LTG-Tech" 1299 "Energy Solutions (UK)" 1300 "WATT Fuel Cell" 1302 "Pro Mainer" 1305 "Dragonfly Energy" 1306 "Koden Electronics" 1311 "Humphree" 1316 "Hinkley Yachts" 1317 "Global Marine Management GmbH (GMM)" 1320 "Triskel Marine" 1330 "Warwick Control Technologies" 1331 "Dolphin Charger" 1337 "Barnacle Systems" 1348 "Radian IoT" 1353 "Ocean LED Marine" 1359 "BluNav" 1361 "OVA (Nantong Saiyang Electronics Co., Ltd)" 1368 "RAD Propulsion" 1369 "Electric Yacht" 1372 "Elco Motor Yachts" 1384 "Tecnoseal Foundry S.r.l" 1385 "Pro Charging Systems" 1389 "EVEX" 1398 "Gobius Sensor Technology" 1403 "Arco Marine" 1408 "Lenco Marine" 1413 "Naocontrol" 1417 "Revatek" 1438 "Aeolionics" 1439 "PredictWind" 1440 "Egis Mobile Electric" 1445 "Starboard Yacht Group" 1446 "Roswell Marine" 1451 "ePropulsion (Guangdong ePropulsion Technology Ltd.)" 1452 "Micro-Air" 1453 "Vital Battery" 1458 "Ride Controller" 1460 "Tocaro Blue" 1461 "Vanquish Yachts" 1471 "FT Technologies" 1478 "Alps Alpine" 1481 "E-Force Marine" 1482 "CMC Marine" 1483 "Nanjing Sandemarine Information Technology" 1850 "Teleflex Marine (SeaStar Solutions)" 1851 "Raymarine" 1852 "Navionics" 1853 "Japan Radio" 1854 "Northstar Technologies" 1855 "Furuno" 1856 "Trimble" 1857 "Simrad" 1858 "Litton" 1859 "Kvasar" 1860 "MMP" 1861 "Vector Cantech" 1862 "Yamaha Marine" 1863 "Faria Instruments" ;
VAL_ 2566848512 Industry_Code 0 "Global" 1 "Highway" 2 "Agriculture" 3 "Construction" 4 "Marine Industry" 5 "Industrial" ;
VAL_ 2365521920 Manufacturer_Code 69 "ARKS Enterprises" 78 "FW Murphy/Enovation Controls" 80 "Twin Disc" 85 "Kohler Power Systems" 88 "Hemisphere GPS" 135 "Airmar" 137 "Maretron" 140 "Lowrance" 144 "Mercury Marine" 147 "Nautibus Electronic" 148 "Blue Water Data" 154 "Westerbeke" 157 "ISSPRO" 161 "Offshore Systems (UK)" 163 "Evinrude/BRP" 165 "CPAC Systems" 168 "Xantrex Technology" 169 "Marlin Technologies" 172 "Yanmar Marine" 174 "Volvo Penta" 176 "Carling Technologies Inc. (Moritz Aerospace)" 185 "Beede Instruments" 192 "Floscan Instrument" 193 "Nobeltec" 198 "Mystic Valley Communications" 199 "Actia" 201 "Disenos Y Technologia" 211 "Digital Switching Systems" 215 "Xintex/Atena" 224 "EMMI NETWORK" 228 "ZF" 229 "Garmin" 233 "Yacht Monitoring Solutions" 235 "Sailormade Marine Telemetry/Tetra Technology" 243 "Eride" 257 "Honda Motor" 272 "Groco" 273 "Actisense" 274 "Amphenol LTW Technology" 275 "Navico" 283 "Hamilton Jet" 285 "Sea Recovery" 286 "Coelmo SRL Italy" 295 "BEP Marine" 304 "Empir Bus" 305 "NovAtel" 306 "Sleipner Motor" 307 "MBW Technologies" 315 "ICOM" 328 "Qwerty" 329 "Dief" 341 "Boening Automationstechnologie" 345 "Korean Maritime University" 351 "Thrane and Thrane" 355 "Mastervolt" 356 "Fischer Panda Generators" 358 "Victron Energy" 370 "Rolls Royce Marine" 373 "Electronic Design" 374 "Northern Lights" 378 "Glendinning" 381 "B & G" 384 "Rose Point Navigation Systems" 385 "Johnson Outdoors Marine Electronics Inc Geonav" 394 "Capi 2" 396 "Beyond Measure" 400 "Livorsi Marine" 404 "ComNav" 409 "Chetco" 419 "Fusion Electronics" 421 "Standard Horizon" 422 "True Heading" 426 "Egersund Marine Electronics" 427 "em-trak Marine Electronics" 431 "Tohatsu Co, JP" 437 "Digital Yacht" 438 "Comar Systems Limited" 440 "Cummins" 443 "VDO (aka Continental-Corporation)" 451 "Parker Hannifin aka Village Marine Tech" 459 "Alltek Marine Electronics" 460 "SAN GIORGIO S.E.I.N" 466 "Veethree Electronics & Marine" 470 "SI-TEX Marine Electronics" 471 "Sea Cross Marine" 475 "GME aka Standard Communications" 476 "Humminbird Marine Electronics" 478 "Ocean Sat" 481 "Chetco Digital Instruments" 493 "Watcheye" 499 "Lcj Capteurs" 502 "Attwood Marine" 503 "Naviop S.R.L." 504 "Vesper Marine" 510 "Marinesoft" 513 "Simarine" 517 "NoLand Engineering" 518 "Transas USA" 529 "National Instruments Korea" 530 "National Marine Electronics Association" 532 "Onwa Marine" 540 "Webasto" 571 "Marinecraft (South Korea)" 573 "McMurdo Group aka Orolia" 578 "Advansea" 579 "KVH" 580 "San Jose Technology" 583 "Yacht Control" 586 "Suzuki Motor" 591 "US Coast Guard" 595 "Ship Module aka Customware" 600 "Aquatic AV" 605 "Aventics" 606 "Intellian" 612 "SamwonIT" 614 "Arlt Tecnologies" 637 "Bavaria Yachts" 641 "Diverse Yacht Services" 644 "Wema U.S.A dba KUS" 658 "Shenzhen Jiuzhou Himunication" 688 "Rockford" 699 "Harman International" 704 "JL Audio" 708 "Lars Thrane" 715 "Autonnic" 717 "Yacht Devices" 734 "REAP Systems" 735 "AEM Performance Electronics" 739 "LxNav" 741 "Littelfuse, Inc (formerly Carling Technologies)" 743 "DaeMyung" 744 "Woosung" 748 "ISOTTA IFRA srl" 773 "Clarion US" 776 "HMI Systems" 777 "Ocean Signal" 778 "Seakeeper" 781 "Poly Planar" 785 "Fischer Panda DE" 795 "Broyda Industries" 796 "Canadian Automotive" 797 "Tides Marine" 798 "Lumishore" 799 "Still Water Designs and Audio" 802 "BJ Technologies (Beneteau)" 803 "Gill Sensors" 811 "Blue Water Desalination" 815 "FLIR" 824 "Undheim Systems" 826 "Lewmar" 838 "TeamSurv" 844 "Fell Marine" 847 "Oceanvolt" 862 "Prospec" 868 "Data Panel" 890 "L3 Technologies" 894 "Rhodan Marine Systems" 896 "Nexfour Solutions" 905 "ASA Electronics" 909 "Marines Co (South Korea)" 911 "Nautic-on" 917 "Sentinel" 929 "JL Marine Systems" 930 "Ecotronix" 944 "Zontisa Marine" 951 "EXOR International" 962 "Timbolier Industries" 963 "TJC Micro" 968 "Cox Powertrain" 969 "Blue Seas" 981 "Kobelt Manufacturing" 992 "Blue Ocean IOT" 997 "Xenta Systems" 999 "Signal K" 1004 "Ultraflex" 1008 "Lintest SmartBoat" 1011 "Soundmax" 1020 "Team Italia Marine (Onyx Marine Automation s.r.l)" 1021 "Entratech" 1022 "ITC" 1029 "The Marine Guardian" 1047 "Sonic" 1051 "ProNav" 1053 "Vetus Maxwell INC." 1056 "Lithium Pros" 1059 "Boatrax" 1062 "Marol Co ltd" 1065 "CALYPSO Instruments" 1066 "Spot Zero Water" 1069 "Lithionics Battery" 1070 "Quick-teck Electronics" 1075 "Uniden America" 1083 "Nauticoncept" 1084 "Shadow-Caster LED lighting" 1085 "Wet Sounds" 1088 "E-T-A Circuit Breakers" 1092 "Scheiber" 1100 "Smart Yachts International Limited" 1109 "Dockmate" 1114 "Bobs Machine" 1118 "L3Harris ASV" 1119 "Balmar" 1120 "Elettromedia" 1127 "Electromaax" 1140 "Across Oceans Systems" 1145 "Kiwi Yachting" 1150 "BSB Artificial Intelligence" 1151 "Orca Technologies" 1154 "TBS Electronics" 1158 "Technoton Electroics" 1160 "MG Energy Systems" 1169 "Sea Machine Robotics" 1171 "Vista Manufacturing" 1183 "Zipwake" 1186 "Sailmon" 1192 "Airmoniq Pro Kft" 1194 "Sierra Marine" 1200 "Xinuo Information Technology (Xiamen)" 1218 "Septentrio" 1233 "NKE Marine Electronics" 1238 "SuperTrack Aps" 1239 "Honda Electronics" 1245 "Raritan Engineering" 1249 "Integrated Power Solutions AG" 1260 "Interactive Technologies" 1283 "LTG-Tech" 1299 "Energy Solutions (UK)" 1300 "WATT Fuel Cell" 1302 "Pro Mainer" 1305 "Dragonfly Energy" 1306 "Koden Electronics" 1311 "Humphree" 1316 "Hinkley Yachts" 1317 "Global Marine Management GmbH (GMM)" 1320 "Triskel Marine" 1330 "Warwick Control Technologies" 1331 "Dolphin Charger" 1337 "Barnacle Systems" 1348 "Radian IoT" 1353 "Ocean LED Marine" 1359 "BluNav" 1361 "OVA (Nantong Saiyang Electronics Co., Ltd)" 1368 "RAD Propulsion" 1369 "Electric Yacht" 1372 "Elco Motor Yachts" 1384 "Tecnoseal Foundry S.r.l" 1385 "Pro Charging Systems" 1389 "EVEX" 1398 "Gobius Sensor Technology" 1403 "Arco Marine" 1408 "Lenco Marine" 1413 "Naocontrol" 1417 "Revatek" 1438 "Aeolionics" 1439 "PredictWind" 1440 "Egis Mobile Electric" 1445 "Starboard Yacht Group" 1446 "Roswell Marine" 1451 "ePropulsion (Guangdong ePropulsion Technology Ltd.)" 1452 "Micro-Air" 1453 "Vital Battery" 1458 "Ride Controller" 1460 "Tocaro Blue" 1461 "Vanquish Yachts" 1471 "FT Technologies" 1478 "Alps Alpine" 1481 "E-Force Marine" 1482 "CMC Marine" 1483 "Nanjing Sandemarine Information Technology" 1850 "Teleflex Marine (SeaStar Solutions)" 1851 "Raymarine" 1852 "Navionics" 1853 "Japan Radio" 1854 "Northstar Technologies" 1855 "Furuno" 1856 "Trimble" 1857 "Simrad" 1858 "Litton" 1859 "Kvasar" 1860 "MMP" 1861 "Vector Cantech" 1862 "Yamaha Marine" 1863 "Faria Instruments" ;
VAL_ 2365521920 Industry_Code 0 "Global" 1 "Highway" 2 "Agriculture" 3 "Construction" 4 "Marine Industry" 5 "Industrial" ;
VAL_ 2298413056 Manufacturer_Code 69 "ARKS Enterprises" 78 "FW Murphy/Enovation Controls" 80 "Twin Disc" 85 "Kohler Power Systems" 88 "Hemisphere GPS" 135 "Airmar" 137 "Maretron" 140 "Lowrance" 144 "Mercury Marine" 147 "Nautibus Electronic" 148 "Blue Water Data" 154 "Westerbeke" 157 "ISSPRO" 161 "Offshore Systems (UK)" 163 "Evinrude/BRP" 165 "CPAC Systems" 168 "Xantrex Technology" 169 "Marlin Technologies" 172 "Yanmar Marine" 174 "Volvo Penta" 176 "Carling Technologies Inc. (Moritz Aerospace)" 185 "Beede Instruments" 192 "Floscan Instrument" 193 "Nobeltec" 198 "Mystic Valley Communications" 199 "Actia" 201 "Disenos Y Technologia" 211 "Digital Switching Systems" 215 "Xintex/Atena" 224 "EMMI NETWORK" 228 "ZF" 229 "Garmin" 233 "Yacht Monitoring Solutions" 235 "Sailormade Marine Telemetry/Tetra Technology" 243 "Eride" 257 "Honda Motor" 272 "Groco" 273 "Actisense" 274 "Amphenol LTW Technology" 275 "Navico" 283 "Hamilton Jet" 285 "Sea Recovery" 286 "Coelmo SRL Italy" 295 "BEP Marine" 304 "Empir Bus" 305 "NovAtel" 306 "Sleipner Motor" 307 "MBW Technologies" 315 "ICOM" 328 "Qwerty" 329 "Dief" 341 "Boening Automationstechnologie" 345 "Korean Maritime University" 351 "Thrane and Thrane" 355 "Mastervolt" 356 "Fischer Panda Generators" 358 "Victron Energy" 370 "Rolls Royce Marine" 373 "Electronic Design" 374 "Northern Lights" 378 "Glendinning" 381 "B & G" 384 "Rose Point Navigation Systems" 385 "Johnson Outdoors Marine Electronics Inc Geonav" 394 "Capi 2" 396 "Beyond Measure" 400 "Livorsi Marine" 404 "ComNav" 409 "Chetco" 419 "Fusion Electronics" 421 "Standard Horizon" 422 "True Heading" 426 "Egersund Marine Electronics" 427 "em-trak Marine Electronics" 431 "Tohatsu Co, JP" 437 "Digital Yacht" 438 "Comar Systems Limited" 440 "Cummins" 443 "VDO (aka Continental-Corporation)" 451 "Parker Hannifin aka Village Marine Tech" 459 "Alltek Marine Electronics" 460 "SAN GIORGIO S.E.I.N" 466 "Veethree Electronics & Marine" 470 "SI-TEX Marine Electronics" 471 "Sea Cross Marine" 475 "GME aka Standard Communications" 476 "Humminbird Marine Electronics" 478 "Ocean Sat" 481 "Chetco Digital Instruments" 493 "Watcheye" 499 "Lcj Capteurs" 502 "Attwood Marine" 503 "Naviop S.R.L." 504 "Vesper Marine" 510 "Marinesoft" 513 "Simarine" 517 "NoLand Engineering" 518 "Transas USA" 529 "National Instruments Korea" 530 "National Marine Electronics Association" 532 "Onwa Marine" 540 "Webasto" 571 "Marinecraft (South Korea)" 573 "McMurdo Group aka Orolia" 578 "Advansea" 579 "KVH" 580 "San Jose Technology" 583 "Yacht Control" 586 "Suzuki Motor" 591 "US Coast Guard" 595 "Ship Module aka Customware" 600 "Aquatic AV" 605 "Aventics" 606 "Intellian" 612 "SamwonIT" 614 "Arlt Tecnologies" 637 "Bavaria Yachts" 641 "Diverse Yacht Services" 644 "Wema U.S.A dba KUS" 658 "Shenzhen Jiuzhou Himunication" 688 "Rockford" 699 "Harman International" 704 "JL Audio" 708 "Lars Thrane" 715 "Autonnic" 717 "Yacht Devices" 734 "REAP Systems" 735 "AEM Performance Electronics" 739 "LxNav" 741 "Littelfuse, Inc (formerly Carling Technologies)" 743 "DaeMyung" 744 "Woosung" 748 "ISOTTA IFRA srl" 773 "Clarion US" 776 "HMI Systems" 777 "Ocean Signal" 778 "Seakeeper" 781 "Poly Planar" 785 "Fischer Panda DE" 795 "Broyda Industries" 796 "Canadian Automotive" 797 "Tides Marine" 798 "Lumishore" 799 "Still Water Designs and Audio" 802 "BJ Technologies (Beneteau)" 803 "Gill Sensors" 811 "Blue Water Desalination" 815 "FLIR" 824 "Undheim Systems" 826 "Lewmar" 838 "TeamSurv" 844 "Fell Marine" 847 "Oceanvolt" 862 "Prospec" 868 "Data Panel" 890 "L3 Technologies" 894 "Rhodan Marine Systems" 896 "Nexfour Solutions" 905 "ASA Electronics" 909 "Marines Co (South Korea)" 911 "Nautic-on" 917 "Sentinel" 929 "JL Marine Systems" 930 "Ecotronix" 944 "Zontisa Marine" 951 "EXOR International" 962 "Timbolier Industries" 963 "TJC Micro" 968 "Cox Powertrain" 969 "Blue Seas" 981 "Kobelt Manufacturing" 992 "Blue Ocean IOT" 997 "Xenta Systems" 999 "Signal K" 1004 "Ultraflex" 1008 "Lintest SmartBoat" 1011 "Soundmax" 1020 "Team Italia Marine (Onyx Marine Automation s.r.l)" 1021 "Entratech" 1022 "ITC" 1029 "The Marine Guardian" 1047 "Sonic" 1051 "ProNav" 1053 "Vetus Maxwell INC." 1056 "Lithium Pros" 1059 "Boatrax" 1062 "Marol Co ltd" 1065 "CALYPSO Instruments" 1066 "Spot Zero Water" 1069 "Lithionics Battery" 1070 "Quick-teck Electronics" 1075 "Uniden America" 1083 "Nauticoncept" 1084 "Shadow-Caster LED lighting" 1085 "Wet Sounds" 1088 "E-T-A Circuit Breakers" 1092 "Scheiber" 1100 "Smart Yachts International Limited" 1109 "Dockmate" 1114 "Bobs Machine" 1118 "L3Harris ASV" 1119 "Balmar" 1120 "Elettromedia" 1127 "Electromaax" 1140 "Across Oceans Systems" 1145 "Kiwi Yachting" 1150 "BSB Artificial Intelligence" 1151 "Orca Technologies" 1154 "TBS Electronics" 1158 "Technoton Electroics" 1160 "MG Energy Systems" 1169 "Sea Machine Robotics" 1171 "Vista Manufacturing" 1183 "Zipwake" 1186 "Sailmon" 1192 "Airmoniq Pro Kft" 1194 "Sierra Marine" 1200 "Xinuo Information Technology (Xiamen)" 1218 "Septentrio" 1233 "NKE Marine Electronics" 1238 "SuperTrack Aps" 1239 "Honda Electronics" 1245 "Raritan Engineering" 1249 "Integrated Power Solutions AG" 1260 "Interactive Technologies" 1283 "LTG-Tech" 1299 "Energy Solutions (UK)" 1300 "WATT Fuel Cell" 1302 "Pro Mainer" 1305 "Dragonfly Energy" 1306 "Koden Electronics" 1311 "Humphree" 1316 "Hinkley Yachts" 1317 "Global Marine Management GmbH (GMM)" 1320 "Triskel Marine" 1330 "Warwick Control Technologies" 1331 "Dolphin Charger" 1337 "Barnacle Systems" 1348 "Radian IoT" 1353 "Ocean LED Marine" 1359 "BluNav" 1361 "OVA (Nantong Saiyang Electronics Co., Ltd)" 1368 "RAD Propulsion" 1369 "Electric Yacht" 1372 "Elco Motor Yachts" 1384 "Tecnoseal Foundry S.r.l" 1385 "Pro Charging Systems" 1389 "EVEX" 1398 "Gobius Sensor Technology" 1403 "Arco Marine" 1408 "Lenco Marine" 1413 "Naocontrol" 1417 "Revatek" 1438 "Aeolionics" 1439 "PredictWind" 1440 "Egis Mobile Electric" 1445 "Starboard Yacht Group" 1446 "Roswell Marine" 1451 "ePropulsion (Guangdong ePropulsion Technology Ltd.)" 1452 "Micro-Air" 1453 "Vital Battery" 1458 "Ride Controller" 1460 "Tocaro Blue" 1461 "Vanquish Yachts" 1471 "FT Technologies" 1478 "Alps Alpine" 1481 "E-Force Marine" 1482 "CMC Marine" 1483 "Nanjing Sandemarine Information Technology" 1850 "Teleflex Marine (SeaStar Solutions)" 1851 "Raymarine" 1852 "Navionics" 1853 "Japan Radio" 1854 "Northstar Technologies" 1855 "Furuno" 1856 "Trimble" 1857 "Simrad" 1858 "Litton" 1859 "Kvasar" 1860 "MMP" 1861 "Vector Cantech" 1862 "Yamaha Marine" 1863 "Faria Instruments" ;
VAL_ 2298413056 Industry_Code 0 "Global" 1 "Highway" 2 "Agriculture" 3 "Construction" 4 "Marine Industry" 5 "Industrial" ;
VAL_ 2566848512 Manufacturer_Code 69 "ARKS Enterprises" 78 "FW Murphy/Enovation Controls" 80 "Twin Disc" 85 "Kohler Power Systems" 88 "Hemisphere GPS" 135 "Airmar" 137 "Maretron" 140 "Lowrance" 144 "Mercury Marine" 147 "Nautibus Electronic" 148 "Blue Water Data" 154 "Westerbeke" 157 "ISSPRO" 161 "Offshore Systems (UK)" 163 "Evinrude/BRP" 165 "CPAC Systems" 168 "Xantrex Technology" 169 "Marlin Technologies" 172 "Yanmar Marine" 174 "Volvo Penta" 176 "Carling Technologies Inc. (Moritz Aerospace)" 185 "Beede Instruments" 192 "Floscan Instrument" 193 "Nobeltec" 198 "Mystic Valley Communications" 199 "Actia" 201 "Disenos Y Technologia" 211 "Digital Switching Systems" 215 "Xintex/Atena" 224 "EMMI NETWORK" 228 "ZF" 229 "Garmin" 233 "Yacht Monitoring Solutions" 235 "Sailormade Marine Telemetry/Tetra Technology" 243 "Eride" 257 "Honda Motor" 272 "Groco" 273 "Actisense" 274 "Amphenol LTW Technology" 275 "Navico" 283 "Hamilton Jet" 285 "Sea Recovery" 286 "Coelmo SRL Italy" 295 "BEP Marine" 304 "Empir Bus" 305 "NovAtel" 306 "Sleipner Motor" 307 "MBW Technologies" 315 "ICOM" 328 "Qwerty" 329 "Dief" 341 "Boening Automationstechnologie" 345 "Korean Maritime University" 351 "Thrane and Thrane" 355 "Mastervolt" 356 "Fischer Panda Generators" 358 "Victron Energy" 370 "Rolls Royce Marine" 373 "Electronic Design" 374 "Northern Lights" 378 "Glendinning" 381 "B & G" 384 "Rose Point Navigation Systems" 385 "Johnson Outdoors Marine Electronics Inc Geonav" 394 "Capi 2" 396 "Beyond Measure" 400 "Livorsi Marine" 404 "ComNav" 409 "Chetco" 419 "Fusion Electronics" 421 "Standard Horizon" 422 "True Heading" 426 "Egersund Marine Electronics" 427 "em-trak Marine Electronics" 431 "Tohatsu Co, JP" 437 "Digital Yacht" 438 "Comar Systems Limited" 440 "Cummins" 443 "VDO (aka Continental-Corporation)" 451 "Parker Hannifin aka Village Marine Tech" 459 "Alltek Marine Electronics" 460 "SAN GIORGIO S.E.I.N" 466 "Veethree Electronics & Marine" 470 "SI-TEX Marine Electronics" 471 "Sea Cross Marine" 475 "GME aka Standard Communications" 476 "Humminbird Marine Electronics" 478 "Ocean Sat" 481 "Chetco Digital Instruments" 493 "Watcheye" 499 "Lcj Capteurs" 502 "Attwood Marine" 503 "Naviop S.R.L." 504 "Vesper Marine" 510 "Marinesoft" 513 "Simarine" 517 "NoLand Engineering" 518 "Transas USA" 529 "National Instruments Korea" 530 "National Marine Electronics Association" 532 "Onwa Marine" 540 "Webasto" 571 "Marinecraft (South Korea)" 573 "McMurdo Group aka Orolia" 578 "Advansea" 579 "KVH" 580 "San Jose Technology" 583 "Yacht Control" 586 "Suzuki Motor" 591 "US Coast Guard" 595 "Ship Module aka Customware" 600 "Aquatic AV" 605 "Aventics" 606 "Intellian" 612 "SamwonIT" 614 "Arlt Tecnologies" 637 "Bavaria Yachts" 641 "Diverse Yacht Services" 644 "Wema U.S.A dba KUS" 658 "Shenzhen Jiuzhou Himunication" 688 "Rockford" 699 "Harman International" 704 "JL Audio" 708 "Lars Thrane" 715 "Autonnic" 717 "Yacht Devices" 734 "REAP Systems" 735 "AEM Performance Electronics" 739 "LxNav" 741 "Littelfuse, Inc (formerly Carling Technologies)" 743 "DaeMyung" 744 "Woosung" 748 "ISOTTA IFRA srl" 773 "Clarion US" 776 "HMI Systems" 777 "Ocean Signal" 778 "Seakeeper" 781 "Poly Planar" 785 "Fischer Panda DE" 795 "Broyda Industries" 796 "Canadian Automotive" 797 "Tides Marine" 798 "Lumishore" 799 "Still Water Designs and Audio" 802 "BJ Technologies (Beneteau)" 803 "Gill Sensors" 811 "Blue Water Desalination" 815 "FLIR" 824 "Undheim Systems" 826 "Lewmar" 838 "TeamSurv" 844 "Fell Marine" 847 "Oceanvolt" 862 "Prospec" 868 "Data Panel" 890 "L3 Technologies" 894 "Rhodan Marine Systems" 896 "Nexfour Solutions" 905 "ASA Electronics" 909 "Marines Co (South Korea)" 911 "Nautic-on" 917 "Sentinel" 929 "JL Marine Systems" 930 "Ecotronix" 944 "Zontisa Marine" 951 "EXOR International" 962 "Timbolier Industries" 963 "TJC Micro" 968 "Cox Powertrain" 969 "Blue Seas" 981 "Kobelt Manufacturing" 992 "Blue Ocean IOT" 997 "Xenta Systems" 999 "Signal K" 1004 "Ultraflex" 1008 "Lintest SmartBoat" 1011 "Soundmax" 1020 "Team Italia Marine (Onyx Marine Automation s.r.l)" 1021 "Entratech" 1022 "ITC" 1029 "The Marine Guardian" 1047 "Sonic" 1051 "ProNav" 1053 "Vetus Maxwell INC." 1056 "Lithium Pros" 1059 "Boatrax" 1062 "Marol Co ltd" 1065 "CALYPSO Instruments" 1066 "Spot Zero Water" 1069 "Lithionics Battery" 1070 "Quick-teck Electronics" 1075 "Uniden America" 1083 "Nauticoncept" 1084 "Shadow-Caster LED lighting" 1085 "Wet Sounds" 1088 "E-T-A Circuit Breakers" 1092 "Scheiber" 1100 "Smart Yachts International Limited" 1109 "Dockmate" 1114 "Bobs Machine" 1118 "L3Harris ASV" 1119 "Balmar" 1120 "Elettromedia" 1127 "Electromaax" 1140 "Across Oceans Systems" 1145 "Kiwi Yachting" 1150 "BSB Artificial Intelligence" 1151 "Orca Technologies" 1154 "TBS Electronics" 1158 "Technoton Electroics" 1160 "MG Energy Systems" 1169 "Sea Machine Robotics" 1171 "Vista Manufacturing" 1183 "Zipwake" 1186 "Sailmon" 1192 "Airmoniq Pro Kft" 1194 "Sierra Marine" 1200 "Xinuo Information Technology (Xiamen)" 1218 "Septentrio" 1233 "NKE Marine Electronics" 1238 "SuperTrack Aps" 1239 "Honda Electronics" 1245 "Raritan Engineering" 1249 "Integrated Power Solutions AG" 1260 "Interactive Technologies" 1283 "LTG-Tech" 1299 "Energy Solutions (UK)" 1300 "WATT Fuel Cell" 1302 "Pro Mainer" 1305 "Dragonfly Energy" 1306 "Koden Electronics" 1311 "Humphree" 1316 "Hinkley Yachts" 1317 "Global Marine Management GmbH (GMM)" 1320 "Triskel Marine" 1330 "Warwick Control Technologies" 1331 "Dolphin Charger" 1337 "Barnacle Systems" 1348 "Radian IoT" 1353 "Ocean LED Marine" 1359 "BluNav" 1361 "OVA (Nantong Saiyang Electronics Co., Ltd)" 1368 "RAD Propulsion" 1369 "Electric Yacht" 1372 "Elco Motor Yachts" 1384 "Tecnoseal Foundry S.r.l" 1385 "Pro Charging Systems" 1389 "EVEX" 1398 "Gobius Sensor Technology" 1403 "Arco Marine" 1408 "Lenco Marine" 1413 "Naocontrol" 1417 "Revatek" 1438 "Aeolionics" 1439 "PredictWind" 1440 "Egis Mobile Electric" 1445 "Starboard Yacht Group" 1446 "Roswell Marine" 1451 "ePropulsion (Guangdong ePropulsion Technology Ltd.)" 1452 "Micro-Air" 1453 "Vital Battery" 1458 "Ride Controller" 1460 "Tocaro Blue" 1461 "Vanquish Yachts" 1471 "FT Technologies" 1478 "Alps Alpine" 1481 "E-Force Marine" 1482 "CMC Marine" 1483 "Nanjing Sandemarine Information Technology" 1850 "Teleflex Marine (SeaStar Solutions)" 1851 "Raymarine" 1852 "Navionics" 1853 "Japan Radio" 1854 "Northstar Technologies" 1855 "Furuno" 1856 "Trimble" 1857 "Simrad" 1858 "Litton" 1859 "Kvasar" 1860 "MMP" 1861 "Vector Cantech" 1862 "Yamaha Marine" 1863 "Faria Instruments" ;
VAL_ 2566848512 Industry_Code 0 "Global" 1 "Highway" 2 "Agriculture" 3 "Construction" 4 "Marine Industry" 5 "Industrial" ;
VAL_ 2566848512 Manufacturer_Code 69 "ARKS Enterprises" 78 "FW Murphy/Enovation Controls" 80 "Twin Disc" 85 "Kohler Power Systems" 88 "Hemisphere GPS" 135 "Airmar" 137 "Maretron" 140 "Lowrance" 144 "Mercury Marine" 147 "Nautibus Electronic" 148 "Blue Water Data" 154 "Westerbeke" 157 "ISSPRO" 161 "Offshore Systems (UK)" 163 "Evinrude/BRP" 165 "CPAC Systems" 168 "Xantrex Technology" 169 "Marlin Technologies" 172 "Yanmar Marine" 174 "Volvo Penta" 176 "Carling Technologies Inc. (Moritz Aerospace)" 185 "Beede Instruments" 192 "Floscan Instrument" 193 "Nobeltec" 198 "Mystic Valley Communications" 199 "Actia" 201 "Disenos Y Technologia" 211 "Digital Switching Systems" 215 "Xintex/Atena" 224 "EMMI NETWORK" 228 "ZF" 229 "Garmin" 233 "Yacht Monitoring Solutions" 235 "Sailormade Marine Telemetry/Tetra Technology" 243 "Eride" 257 "Honda Motor" 272 "Groco" 273 "Actisense" 274 "Amphenol LTW Technology" 275 "Navico" 283 "Hamilton Jet" 285 "Sea Recovery" 286 "Coelmo SRL Italy" 295 "BEP Marine" 304 "Empir Bus" 305 "NovAtel" 306 "Sleipner Motor" 307 "MBW Technologies" 315 "ICOM" 328 "Qwerty" 329 "Dief" 341 "Boening Automationstechnologie" 345 "Korean Maritime University" 351 "Thrane and Thrane" 355 "Mastervolt" 356 "Fischer Panda Generators" 358 "Victron Energy" 370 "Rolls Royce Marine" 373 "Electronic Design" 374 "Northern Lights" 378 "Glendinning" 381 "B & G" 384 "Rose Point Navigation Systems" 385 "Johnson Outdoors Marine Electronics Inc Geonav" 394 "Capi 2" 396 "Beyond Measure" 400 "Livorsi Marine" 404 "ComNav" 409 "Chetco" 419 "Fusion Electronics" 421 "Standard Horizon" 422 "True Heading" 426 "Egersund Marine Electronics" 427 "em-trak Marine Electronics" 431 "Tohatsu Co, JP" 437 "Digital Yacht" 438 "Comar Systems Limited" 440 "Cummins" 443 "VDO (aka Continental-Corporation)" 451 "Parker Hannifin aka Village Marine Tech" 459 "Alltek Marine Electronics" 460 "SAN GIORGIO S.E.I.N" 466 "Veethree Electronics & Marine" 470 "SI-TEX Marine Electronics" 471 "Sea Cross Marine" 475 "GME aka Standard Communications" 476 "Humminbird Marine Electronics" 478 "Ocean Sat" 481 "Chetco Digital Instruments" 493 "Watcheye" 499 "Lcj Capteurs" 502 "Attwood Marine" 503 "Naviop S.R.L." 504 "Vesper Marine" 510 "Marinesoft" 513 "Simarine" 517 "NoLand Engineering" 518 "Transas USA" 529 "National Instruments Korea" 530 "National Marine Electronics Association" 532 "Onwa Marine" 540 "Webasto" 571 "Marinecraft (South Korea)" 573 "McMurdo Group aka Orolia" 578 "Advansea" 579 "KVH" 580 "San Jose Technology" 583 "Yacht Control" 586 "Suzuki Motor" 591 "US Coast Guard" 595 "Ship Module aka Customware" 600 "Aquatic AV" 605 "Aventics" 606 "Intellian" 612 "SamwonIT" 614 "Arlt Tecnologies" 637 "Bavaria Yachts" 641 "Diverse Yacht Services" 644 "Wema U.S.A dba KUS" 658 "Shenzhen Jiuzhou Himunication" 688 "Rockford" 699 "Harman International" 704 "JL Audio" 708 "Lars Thrane" 715 "Autonnic" 717 "Yacht Devices" 734 "REAP Systems" 735 "AEM Performance Electronics" 739 "LxNav" 741 "Littelfuse, Inc (formerly Carling Technologies)" 743 "DaeMyung" 744 "Woosung" 748 "ISOTTA IFRA srl" 773 "Clarion US" 776 "HMI Systems" 777 "Ocean Signal" 778 "Seakeeper" 781 "Poly Planar" 785 "Fischer Panda DE" 795 "Broyda Industries" 796 "Canadian Automotive" 797 "Tides Marine" 798 "Lumishore" 799 "Still Water Designs and Audio" 802 "BJ Technologies (Beneteau)" 803 "Gill Sensors" 811 "Blue Water Desalination" 815 "FLIR" 824 "Undheim Systems" 826 "Lewmar" 838 "TeamSurv" 844 "Fell Marine" 847 "Oceanvolt" 862 "Prospec" 868 "Data Panel" 890 "L3 Technologies" 894 "Rhodan Marine Systems" 896 "Nexfour Solutions" 905 "ASA Electronics" 909 "Marines Co (South Korea)" 911 "Nautic-on" 917 "Sentinel" 929 "JL Marine Systems" 930 "Ecotronix" 944 "Zontisa Marine" 951 "EXOR International" 962 "Timbolier Industries" 963 "TJC Micro" 968 "Cox Powertrain" 969 "Blue Seas" 981 "Kobelt Manufacturing" 992 "Blue Ocean IOT" 997 "Xenta Systems" 999 "Signal K" 1004 "Ultraflex" 1008 "Lintest SmartBoat" 1011 "Soundmax" 1020 "Team Italia Marine (Onyx Marine Automation s.r.l)" 1021 "Entratech" 1022 "ITC" 1029 "The Marine Guardian" 1047 "Sonic" 1051 "ProNav" 1053 "Vetus Maxwell INC." 1056 "Lithium Pros" 1059 "Boatrax" 1062 "Marol Co ltd" 1065 "CALYPSO Instruments" 1066 "Spot Zero Water" 1069 "Lithionics Battery" 1070 "Quick-teck Electronics" 1075 "Uniden America" 1083 "Nauticoncept" 1084 "Shadow-Caster LED lighting" 1085 "Wet Sounds" 1088 "E-T-A Circuit Breakers" 1092 "Scheiber" 1100 "Smart Yachts International Limited" 1109 "Dockmate" 1114 "Bobs Machine" 1118 "L3Harris ASV" 1119 "Balmar" 1120 "Elettromedia" 1127 "Electromaax" 1140 "Across Oceans Systems" 1145 "Kiwi Yachting" 1150 "BSB Artificial Intelligence" 1151 "Orca Technologies" 1154 "TBS Electronics" 1158 "Technoton Electroics" 1160 "MG Energy Systems" 1169 "Sea Machine Robotics" 1171 "Vista Manufacturing" 1183 "Zipwake" 1186 "Sailmon" 1192 "Airmoniq Pro Kft" 1194 "Sierra Marine" 1200 "Xinuo Information Technology (Xiamen)" 1218 "Septentrio" 1233 "NKE Marine Electronics" 1238 "SuperTrack Aps" 1239 "Honda Electronics" 1245 "Raritan Engineering" 1249 "Integrated Power Solutions AG" 1260 "Interactive Technologies" 1283 "LTG-Tech" 1299 "Energy Solutions (UK)" 1300 "WATT Fuel Cell" 1302 "Pro Mainer" 1305 "Dragonfly Energy" 1306 "Koden Electronics" 1311 "Humphree" 1316 "Hinkley Yachts" 1317 "Global Marine Management GmbH (GMM)" 1320 "Triskel Marine" 1330 "Warwick Control Technologies" 1331 "Dolphin Charger" 1337 "Barnacle Systems" 1348 "Radian IoT" 1353 "Ocean LED Marine" 1359 "BluNav" 1361 "OVA (Nantong Saiyang Electronics Co., Ltd)" 1368 "RAD Propulsion" 1369 "Electric Yacht" 1372 "Elco Motor Yachts" 1384 "Tecnoseal Foundry S.r.l" 1385 "Pro Charging Systems" 1389 "EVEX" 1398 "Gobius Sensor Technology" 1403 "Arco Marine" 1408 "Lenco Marine" 1413 "Naocontrol" 1417 "Revatek" 1438 "Aeolionics" 1439 "PredictWind" 1440 "Egis Mobile Electric" 1445 "Starboard Yacht Group" 1446 "Roswell Marine" 1451 "ePropulsion (Guangdong ePropulsion Technology Ltd.)" 1452 "Micro-Air" 1453 "Vital Battery" 1458 "Ride Controller" 1460 "Tocaro Blue" 1461 "Vanquish Yachts" 1471 "FT Technologies" 1478 "Alps Alpine" 1481 "E-Force Marine" 1482 "CMC Marine" 1483 "Nanjing Sandemarine Information Technology" 1850 "Teleflex Marine (SeaStar Solutions)" 1851 "Raymarine" 1852 "Navionics" 1853 "Japan Radio" 1854 "Northstar Technologies" 1855 "Furuno" 1856 "Trimble" 1857 "Simrad" 1858 "Litton" 1859 "Kvasar" 1860 "MMP" 1861 "Vector Cantech" 1862 "Yamaha Marine" 1863 "Faria Instruments" ;
VAL_ 2566848512 Industry_Code 0 "Global" 1 "Highway" 2 "Agriculture" 3 "Construction" 4 "Marine Industry" 5 "Industrial" ;
VAL_ 2566848512 Manufacturer_Code 69 "ARKS Enterprises" 78 "FW Murphy/Enovation Controls" 80 "Twin Disc" 85 "Kohler Power Systems" 88 "Hemisphere GPS" 135 "Airmar" 137 "Maretron" 140 "Lowrance" 144 "Mercury Marine" 147 "Nautibus Electronic" 148 "Blue Water Data" 154 "Westerbeke" 157 "ISSPRO" 161 "Offshore Systems (UK)" 163 "Evinrude/BRP" 165 "CPAC Systems" 168 "Xantrex Technology" 169 "Marlin Technologies" 172 "Yanmar Marine" 174 "Volvo Penta" 176 "Carling Technologies Inc. (Moritz Aerospace)" 185 "Beede Instruments" 192 "Floscan Instrument" 193 "Nobeltec" 198 "Mystic Valley Communications" 199 "Actia" 201 "Disenos Y Technologia" 211 "Digital Switching Systems" 215 "Xintex/Atena" 224 "EMMI NETWORK" 228 "ZF" 229 "Garmin" 233 "Yacht Monitoring Solutions" 235 "Sailormade Marine Telemetry/Tetra Technology" 243 "Eride" 257 "Honda Motor" 272 "Groco" 273 "Actisense" 274 "Amphenol LTW Technology" 275 "Navico" 283 "Hamilton Jet" 285 "Sea Recovery" 286 "Coelmo SRL Italy" 295 "BEP Marine" 304 "Empir Bus" 305 "NovAtel" 306 "Sleipner Motor" 307 "MBW Technologies" 315 "ICOM" 328 "Qwerty" 329 "Dief" 341 "Boening Automationstechnologie" 345 "Korean Maritime University" 351 "Thrane and Thrane" 355 "Mastervolt" 356 "Fischer Panda Generators" 358 "Victron Energy" 370 "Rolls Royce Marine" 373 "Electronic Design" 374 "Northern Lights" 378 "Glendinning" 381 "B & G" 384 "Rose Point Navigation Systems" 385 "Johnson Outdoors Marine Electronics Inc Geonav" 394 "Capi 2" 396 "Beyond Measure" 400 "Livorsi Marine" 404 "ComNav" 409 "Chetco" 419 "Fusion Electronics" 421 "Standard Horizon" 422 "True Heading" 426 "Egersund Marine Electronics" 427 "em-trak Marine Electronics" 431 "Tohatsu Co, JP" 437 "Digital Yacht" 438 "Comar Systems Limited" 440 "Cummins" 443 "VDO (aka Continental-Corporation)" 451 "Parker Hannifin aka Village Marine Tech" 459 "Alltek Marine Electronics" 460 "SAN GIORGIO S.E.I.N" 466 "Veethree Electronics & Marine" 470 "SI-TEX Marine Electronics" 471 "Sea Cross Marine" 475 "GME aka Standard Communications" 476 "Humminbird Marine Electronics" 478 "Ocean Sat" 481 "Chetco Digital Instruments" 493 "Watcheye" 499 "Lcj Capteurs" 502 "Attwood Marine" 503 "Naviop S.R.L." 504 "Vesper Marine" 510 "Marinesoft" 513 "Simarine" 517 "NoLand Engineering" 518 "Transas USA" 529 "National Instruments Korea" 530 "National Marine Electronics Association" 532 "Onwa Marine" 540 "Webasto" 571 "Marinecraft (South Korea)" 573 "McMurdo Group aka Orolia" 578 "Advansea" 579 "KVH" 580 "San Jose Technology" 583 "Yacht Control" 586 "Suzuki Motor" 591 "US Coast Guard" 595 "Ship Module aka Customware" 600 "Aquatic AV" 605 "Aventics" 606 "Intellian" 612 "SamwonIT" 614 "Arlt Tecnologies" 637 "Bavaria Yachts" 641 "Diverse Yacht Services" 644 "Wema U.S.A dba KUS" 658 "Shenzhen Jiuzhou Himunication" 688 "Rockford" 699 "Harman International" 704 "JL Audio" 708 "Lars Thrane" 715 "Autonnic" 717 "Yacht Devices" 734 "REAP Systems" 735 "AEM Performance Electronics" 739 "LxNav" 741 "Littelfuse, Inc (formerly Carling Technologies)" 743 "DaeMyung" 744 "Woosung" 748 "ISOTTA IFRA srl" 773 "Clarion US" 776 "HMI Systems" 777 "Ocean Signal" 778 "Seakeeper" 781 "Poly Planar" 785 "Fischer Panda DE" 795 "Broyda Industries" 796 "Canadian Automotive" 797 "Tides Marine" 798 "Lumishore" 799 "Still Water Designs and Audio" 802 "BJ Technologies (Beneteau)" 803 "Gill Sensors" 811 "Blue Water Desalination" 815 "FLIR" 824 "Undheim Systems" 826 "Lewmar" 838 "TeamSurv" 844 "Fell Marine" 847 "Oceanvolt" 862 "Prospec" 868 "Data Panel" 890 "L3 Technologies" 894 "Rhodan Marine Systems" 896 "Nexfour Solutions" 905 "ASA Electronics" 909 "Marines Co (South Korea)" 911 "Nautic-on" 917 "Sentinel" 929 "JL Marine Systems" 930 "Ecotronix" 944 "Zontisa Marine" 951 "EXOR International" 962 "Timbolier Industries" 963 "TJC Micro" 968 "Cox Powertrain" 969 "Blue Seas" 981 "Kobelt Manufacturing" 992 "Blue Ocean IOT" 997 "Xenta Systems" 999 "Signal K" 1004 "Ultraflex" 1008 "Lintest SmartBoat" 1011 "Soundmax" 1020 "Team Italia Marine (Onyx Marine Automation s.r.l)" 1021 "Entratech" 1022 "ITC" 1029 "The Marine Guardian" 1047 "Sonic" 1051 "ProNav" 1053 "Vetus Maxwell INC." 1056 "Lithium Pros" 1059 "Boatrax" 1062 "Marol Co ltd" 1065 "CALYPSO Instruments" 1066 "Spot Zero Water" 1069 "Lithionics Battery" 1070 "Quick-teck Electronics" 1075 "Uniden America" 1083 "Nauticoncept" 1084 "Shadow-Caster LED lighting" 1085 "Wet Sounds" 1088 "E-T-A Circuit Breakers" 1092 "Scheiber" 1100 "Smart Yachts International Limited" 1109 "Dockmate" 1114 "Bobs Machine" 1118 "L3Harris ASV" 1119 "Balmar" 1120 "Elettromedia" 1127 "Electromaax" 1140 "Across Oceans Systems" 1145 "Kiwi Yachting" 1150 "BSB Artificial Intelligence" 1151 "Orca Technologies" 1154 "TBS Electronics" 1158 "Technoton Electroics" 1160 "MG Energy Systems" 1169 "Sea Machine Robotics" 1171 "Vista Manufacturing" 1183 "Zipwake" 1186 "Sailmon" 1192 "Airmoniq Pro Kft" 1194 "Sierra Marine" 1200 "Xinuo Information Technology (Xiamen)" 1218 "Septentrio" 1233 "NKE Marine Electronics" 1238 "SuperTrack Aps" 1239 "Honda Electronics" 1245 "Raritan Engineering" 1249 "Integrated Power Solutions AG" 1260 "Interactive Technologies" 1283 "LTG-Tech" 1299 "Energy Solutions (UK)" 1300 "WATT Fuel Cell" 1302 "Pro Mainer" 1305 "Dragonfly Energy" 1306 "Koden Electronics" 1311 "Humphree" 1316 "Hinkley Yachts" 1317 "Global Marine Management GmbH (GMM)" 1320 "Triskel Marine" 1330 "Warwick Control Technologies" 1331 "Dolphin Charger" 1337 "Barnacle Systems" 1348 "Radian IoT" 1353 "Ocean LED Marine" 1359 "BluNav" 1361 "OVA (Nantong Saiyang Electronics Co., Ltd)" 1368 "RAD Propulsion" 1369 "Electric Yacht" 1372 "Elco Motor Yachts" 1384 "Tecnoseal Foundry S.r.l" 1385 "Pro Charging Systems" 1389 "EVEX" 1398 "Gobius Sensor Technology" 1403 "Arco Marine" 1408 "Lenco Marine" 1413 "Naocontrol" 1417 "Revatek" 1438 "Aeolionics" 1439 "PredictWind" 1440 "Egis Mobile Electric" 1445 "Starboard Yacht Group" 1446 "Roswell Marine" 1451 "ePropulsion (Guangdong ePropulsion Technology Ltd.)" 1452 "Micro-Air" 1453 "Vital Battery" 1458 "Ride Controller" 1460 "Tocaro Blue" 1461 "Vanquish Yachts" 1471 "FT Technologies" 1478 "Alps Alpine" 1481 "E-Force Marine" 1482 "CMC Marine" 1483 "Nanjing Sandemarine Information Technology" 1850 "Teleflex Marine (SeaStar Solutions)" 1851 "Raymarine" 1852 "Navionics" 1853 "Japan Radio" 1854 "Northstar Technologies" 1855 "Furuno" 1856 "Trimble" 1857 "Simrad" 1858 "Litton" 1859 "Kvasar" 1860 "MMP" 1861 "Vector Cantech" 1862 "Yamaha Marine" 1863 "Faria Instruments" ;
VAL_ 2566848512 Industry_Code 0 "Global" 1 "Highway" 2 "Agriculture" 3 "Construction" 4 "Marine Industry" 5 "Industrial" ;
VAL_ 2633957376 Manufacturer_Code 69 "ARKS Enterprises" 78 "FW Murphy/Enovation Controls" 80 "Twin Disc" 85 "Kohler Power Systems" 88 "Hemisphere GPS" 135 "Airmar" 137 "Maretron" 140 "Lowrance" 144 "Mercury Marine" 147 "Nautibus Electronic" 148 "Blue Water Data" 154 "Westerbeke" 157 "ISSPRO" 161 "Offshore Systems (UK)" 163 "Evinrude/BRP" 165 "CPAC Systems" 168 "Xantrex Technology" 169 "Marlin Technologies" 172 "Yanmar Marine" 174 "Volvo Penta" 176 "Carling Technologies Inc. (Moritz Aerospace)" 185 "Beede Instruments" 192 "Floscan Instrument" 193 "Nobeltec" 198 "Mystic Valley Communications" 199 "Actia" 201 "Disenos Y Technologia" 211 "Digital Switching Systems" 215 "Xintex/Atena" 224 "EMMI NETWORK" 228 "ZF" 229 "Garmin" 233 "Yacht Monitoring Solutions" 235 "Sailormade Marine Telemetry/Tetra Technology" 243 "Eride" 257 "Honda Motor" 272 "Groco" 273 "Actisense" 274 "Amphenol LTW Technology" 275 "Navico" 283 "Hamilton Jet" 285 "Sea Recovery" 286 "Coelmo SRL Italy" 295 "BEP Marine" 304 "Empir Bus" 305 "NovAtel" 306 "Sleipner Motor" 307 "MBW Technologies" 315 "ICOM" 328 "Qwerty" 329 "Dief" 341 "Boening Automationstechnologie" 345 "Korean Maritime University" 351 "Thrane and Thrane" 355 "Mastervolt" 356 "Fischer Panda Generators" 358 "Victron Energy" 370 "Rolls Royce Marine" 373 "Electronic Design" 374 "Northern Lights" 378 "Glendinning" 381 "B & G" 384 "Rose Point Navigation Systems" 385 "Johnson Outdoors Marine Electronics Inc Geonav" 394 "Capi 2" 396 "Beyond Measure" 400 "Livorsi Marine" 404 "ComNav" 409 "Chetco" 419 "Fusion Electronics" 421 "Standard Horizon" 422 "True Heading" 426 "Egersund Marine Electronics" 427 "em-trak Marine Electronics" 431 "Tohatsu Co, JP" 437 "Digital Yacht" 438 "Comar Systems Limited" 440 "Cummins" 443 "VDO (aka Continental-Corporation)" 451 "Parker Hannifin aka Village Marine Tech" 459 "Alltek Marine Electronics" 460 "SAN GIORGIO S.E.I.N" 466 "Veethree Electronics & Marine" 470 "SI-TEX Marine Electronics" 471 "Sea Cross Marine" 475 "GME aka Standard Communications" 476 "Humminbird Marine Electronics" 478 "Ocean Sat" 481 "Chetco Digital Instruments" 493 "Watcheye" 499 "Lcj Capteurs" 502 "Attwood Marine" 503 "Naviop S.R.L." 504 "Vesper Marine" 510 "Marinesoft" 513 "Simarine" 517 "NoLand Engineering" 518 "Transas USA" 529 "National Instruments Korea" 530 "National Marine Electronics Association" 532 "Onwa Marine" 540 "Webasto" 571 "Marinecraft (South Korea)" 573 "McMurdo Group aka Orolia" 578 "Advansea" 579 "KVH" 580 "San Jose Technology" 583 "Yacht Control" 586 "Suzuki Motor" 591 "US Coast Guard" 595 "Ship Module aka Customware" 600 "Aquatic AV" 605 "Aventics" 606 "Intellian" 612 "SamwonIT" 614 "Arlt Tecnologies" 637 "Bavaria Yachts" 641 "Diverse Yacht Services" 644 "Wema U.S.A dba KUS" 658 "Shenzhen Jiuzhou Himunication" 688 "Rockford" 699 "Harman International" 704 "JL Audio" 708 "Lars Thrane" 715 "Autonnic" 717 "Yacht Devices" 734 "REAP Systems" 735 "AEM Performance Electronics" 739 "LxNav" 741 "Littelfuse, Inc (formerly Carling Technologies)" 743 "DaeMyung" 744 "Woosung" 748 "ISOTTA IFRA srl" 773 "Clarion US" 776 "HMI Systems" 777 "Ocean Signal" 778 "Seakeeper" 781 "Poly Planar" 785 "Fischer Panda DE" 795 "Broyda Industries" 796 "Canadian Automotive" 797 "Tides Marine" 798 "Lumishore" 799 "Still Water Designs and Audio" 802 "BJ Technologies (Beneteau)" 803 "Gill Sensors" 811 "Blue Water Desalination" 815 "FLIR" 824 "Undheim Systems" 826 "Lewmar" 838 "TeamSurv" 844 "Fell Marine" 847 "Oceanvolt" 862 "Prospec" 868 "Data Panel" 890 "L3 Technologies" 894 "Rhodan Marine Systems" 896 "Nexfour Solutions" 905 "ASA Electronics" 909 "Marines Co (South Korea)" 911 "Nautic-on" 917 "Sentinel" 929 "JL Marine Systems" 930 "Ecotronix" 944 "Zontisa Marine" 951 "EXOR International" 962 "Timbolier Industries" 963 "TJC Micro" 968 "Cox Powertrain" 969 "Blue Seas" 981 "Kobelt Manufacturing" 992 "Blue Ocean IOT" 997 "Xenta Systems" 999 "Signal K" 1004 "Ultraflex" 1008 "Lintest SmartBoat" 1011 "Soundmax" 1020 "Team Italia Marine (Onyx Marine Automation s.r.l)" 1021 "Entratech" 1022 "ITC" 1029 "The Marine Guardian" 1047 "Sonic" 1051 "ProNav" 1053 "Vetus Maxwell INC." 1056 "Lithium Pros" 1059 "Boatrax" 1062 "Marol Co ltd" 1065 "CALYPSO Instruments" 1066 "Spot Zero Water" 1069 "Lithionics Battery" 1070 "Quick-teck Electronics" 1075 "Uniden America" 1083 "Nauticoncept" 1084 "Shadow-Caster LED lighting" 1085 "Wet Sounds" 1088 "E-T-A Circuit Breakers" 1092 "Scheiber" 1100 "Smart Yachts International Limited" 1109 "Dockmate" 1114 "Bobs Machine" 1118 "L3Harris ASV" 1119 "Balmar" 1120 "Elettromedia" 1127 "Electromaax" 1140 "Across Oceans Systems" 1145 "Kiwi Yachting" 1150 "BSB Artificial Intelligence" 1151 "Orca Technologies" 1154 "TBS Electronics" 1158 "Technoton Electroics" 1160 "MG Energy Systems" 1169 "Sea Machine Robotics" 1171 "Vista Manufacturing" 1183 "Zipwake" 1186 "Sailmon" 1192 "Airmoniq Pro Kft" 1194 "Sierra Marine" 1200 "Xinuo Information Technology (Xiamen)" 1218 "Septentrio" 1233 "NKE Marine Electronics" 1238 "SuperTrack Aps" 1239 "Honda Electronics" 1245 "Raritan Engineering" 1249 "Integrated Power Solutions AG" 1260 "Interactive Technologies" 1283 "LTG-Tech" 1299 "Energy Solutions (UK)" 1300 "WATT Fuel Cell" 1302 "Pro Mainer" 1305 "Dragonfly Energy" 1306 "Koden Electronics" 1311 "Humphree" 1316 "Hinkley Yachts" 1317 "Global Marine Management GmbH (GMM)" 1320 "Triskel Marine" 1330 "Warwick Control Technologies" 1331 "Dolphin Charger" 1337 "Barnacle Systems" 1348 "Radian IoT" 1353 "Ocean LED Marine" 1359 "BluNav" 1361 "OVA (Nantong Saiyang Electronics Co., Ltd)" 1368 "RAD Propulsion" 1369 "Electric Yacht" 1372 "Elco Motor Yachts" 1384 "Tecnoseal Foundry S.r.l" 1385 "Pro Charging Systems" 1389 "EVEX" 1398 "Gobius Sensor Technology" 1403 "Arco Marine" 1408 "Lenco Marine" 1413 "Naocontrol" 1417 "Revatek" 1438 "Aeolionics" 1439 "PredictWind" 1440 "Egis Mobile Electric" 1445 "Starboard Yacht Group" 1446 "Roswell Marine" 1451 "ePropulsion (Guangdong ePropulsion Technology Ltd.)" 1452 "Micro-Air" 1453 "Vital Battery" 1458 "Ride Controller" 1460 "Tocaro Blue" 1461 "Vanquish Yachts" 1471 "FT Technologies" 1478 "Alps Alpine" 1481 "E-Force Marine" 1482 "CMC Marine" 1483 "Nanjing Sandemarine Information Technology" 1850 "Teleflex Marine (SeaStar Solutions)" 1851 "Raymarine" 1852 "Navionics" 1853 "Japan Radio" 1854 "Northstar Technologies" 1855 "Furuno" 1856 "Trimble" 1857 "Simrad" 1858 "Litton" 1859 "Kvasar" 1860 "MMP" 1861 "Vector Cantech" 1862 "Yamaha Marine" 1863 "Faria Instruments" ;
VAL_ 2633957376 Industry_Code 0 "Global" 1 "Highway" 2 "Agriculture" 3 "Construction" 4 "Marine Industry" 5 "Industrial" ;
VAL_ 2298413056 Manufacturer_Code 69 "ARKS Enterprises" 78 "FW Murphy/Enovation Controls" 80 "Twin Disc" 85 "Kohler Power Systems" 88 "Hemisphere GPS" 135 "Airmar" 137 "Maretron" 140 "Lowrance" 144 "Mercury Marine" 147 "Nautibus Electronic" 148 "Blue Water Data" 154 "Westerbeke" 157 "ISSPRO" 161 "Offshore Systems (UK)" 163 "Evinrude/BRP" 165 "CPAC Systems" 168 "Xantrex Technology" 169 "Marlin Technologies" 172 "Yanmar Marine" 174 "Volvo Penta" 176 "Carling Technologies Inc. (Moritz Aerospace)" 185 "Beede Instruments" 192 "Floscan Instrument" 193 "Nobeltec" 198 "Mystic Valley Communications" 199 "Actia" 201 "Disenos Y Technologia" 211 "Digital Switching Systems" 215 "Xintex/Atena" 224 "EMMI NETWORK" 228 "ZF" 229 "Garmin" 233 "Yacht Monitoring Solutions" 235 "Sailormade Marine Telemetry/Tetra Technology" 243 "Eride" 257 "Honda Motor" 272 "Groco" 273 "Actisense" 274 "Amphenol LTW Technology" 275 "Navico" 283 "Hamilton Jet" 285 "Sea Recovery" 286 "Coelmo SRL Italy" 295 "BEP Marine" 304 "Empir Bus" 305 "NovAtel" 306 "Sleipner Motor" 307 "MBW Technologies" 315 "ICOM" 328 "Qwerty" 329 "Dief" 341 "Boening Automationstechnologie" 345 "Korean Maritime University" 351 "Thrane and Thrane" 355 "Mastervolt" 356 "Fischer Panda Generators" 358 "Victron Energy" 370 "Rolls Royce Marine" 373 "Electronic Design" 374 "Northern Lights" 378 "Glendinning" 381 "B & G" 384 "Rose Point Navigation Systems" 385 "Johnson Outdoors Marine Electronics Inc Geonav" 394 "Capi 2" 396 "Beyond Measure" 400 "Livorsi Marine" 404 "ComNav" 409 "Chetco" 419 "Fusion Electronics" 421 "Standard Horizon" 422 "True Heading" 426 "Egersund Marine Electronics" 427 "em-trak Marine Electronics" 431 "Tohatsu Co, JP" 437 "Digital Yacht" 438 "Comar Systems Limited" 440 "Cummins" 443 "VDO (aka Continental-Corporation)" 451 "Parker Hannifin aka Village Marine Tech" 459 "Alltek Marine Electronics" 460 "SAN GIORGIO S.E.I.N" 466 "Veethree Electronics & Marine" 470 "SI-TEX Marine Electronics" 471 "Sea Cross Marine" 475 "GME aka Standard Communications" 476 "Humminbird Marine Electronics" 478 "Ocean Sat" 481 "Chetco Digital Instruments" 493 "Watcheye" 499 "Lcj Capteurs" 502 "Attwood Marine" 503 "Naviop S.R.L." 504 "Vesper Marine" 510 "Marinesoft" 513 "Simarine" 517 "NoLand Engineering" 518 "Transas USA" 529 "National Instruments Korea" 530 "National Marine Electronics Association" 532 "Onwa Marine" 540 "Webasto" 571 "Marinecraft (South Korea)" 573 "McMurdo Group aka Orolia" 578 "Advansea" 579 "KVH" 580 "San Jose Technology" 583 "Yacht Control" 586 "Suzuki Motor" 591 "US Coast Guard" 595 "Ship Module aka Customware" 600 "Aquatic AV" 605 "Aventics" 606 "Intellian" 612 "SamwonIT" 614 "Arlt Tecnologies" 637 "Bavaria Yachts" 641 "Diverse Yacht Services" 644 "Wema U.S.A dba KUS" 658 "Shenzhen Jiuzhou Himunication" 688 "Rockford" 699 "Harman International" 704 "JL Audio" 708 "Lars Thrane" 715 "Autonnic" 717 "Yacht Devices" 734 "REAP Systems" 735 "AEM Performance Electronics" 739 "LxNav" 741 "Littelfuse, Inc (formerly Carling Technologies)" 743 "DaeMyung" 744 "Woosung" 748 "ISOTTA IFRA srl" 773 "Clarion US" 776 "HMI Systems" 777 "Ocean Signal" 778 "Seakeeper" 781 "Poly Planar" 785 "Fischer Panda DE" 795 "Broyda Industries" 796 "Canadian Automotive" 797 "Tides Marine" 798 "Lumishore" 799 "Still Water Designs and Audio" 802 "BJ Technologies (Beneteau)" 803 "Gill Sensors" 811 "Blue Water Desalination" 815 "FLIR" 824 "Undheim Systems" 826 "Lewmar" 838 "TeamSurv" 844 "Fell Marine" 847 "Oceanvolt" 862 "Prospec" 868 "Data Panel" 890 "L3 Technologies" 894 "Rhodan Marine Systems" 896 "Nexfour Solutions" 905 "ASA Electronics" 909 "Marines Co (South Korea)" 911 "Nautic-on" 917 "Sentinel" 929 "JL Marine Systems" 930 "Ecotronix" 944 "Zontisa Marine" 951 "EXOR International" 962 "Timbolier Industries" 963 "TJC Micro" 968 "Cox Powertrain" 969 "Blue Seas" 981 "Kobelt Manufacturing" 992 "Blue Ocean IOT" 997 "Xenta Systems" 999 "Signal K" 1004 "Ultraflex" 1008 "Lintest SmartBoat" 1011 "Soundmax" 1020 "Team Italia Marine (Onyx Marine Automation s.r.l)" 1021 "Entratech" 1022 "ITC" 1029 "The Marine Guardian" 1047 "Sonic" 1051 "ProNav" 1053 "Vetus Maxwell INC." 1056 "Lithium Pros" 1059 "Boatrax" 1062 "Marol Co ltd" 1065 "CALYPSO Instruments" 1066 "Spot Zero Water" 1069 "Lithionics Battery" 1070 "Quick-teck Electronics" 1075 "Uniden America" 1083 "Nauticoncept" 1084 "Shadow-Caster LED lighting" 1085 "Wet Sounds" 1088 "E-T-A Circuit Breakers" 1092 "Scheiber" 1100 "Smart Yachts International Limited" 1109 "Dockmate" 1114 "Bobs Machine" 1118 "L3Harris ASV" 1119 "Balmar" 1120 "Elettromedia" 1127 "Electromaax" 1140 "Across Oceans Systems" 1145 "Kiwi Yachting" 1150 "BSB Artificial Intelligence" 1151 "Orca Technologies" 1154 "TBS Electronics" 1158 "Technoton Electroics" 1160 "MG Energy Systems" 1169 "Sea Machine Robotics" 1171 "Vista Manufacturing" 1183 "Zipwake" 1186 "Sailmon" 1192 "Airmoniq Pro Kft" 1194 "Sierra Marine" 1200 "Xinuo Information Technology (Xiamen)" 1218 "Septentrio" 1233 "NKE Marine Electronics" 1238 "SuperTrack Aps" 1239 "Honda Electronics" 1245 "Raritan Engineering" 1249 "Integrated Power Solutions AG" 1260 "Interactive Technologies" 1283 "LTG-Tech" 1299 "Energy Solutions (UK)" 1300 "WATT Fuel Cell" 1302 "Pro Mainer" 1305 "Dragonfly Energy" 1306 "Koden Electronics" 1311 "Humphree" 1316 "Hinkley Yachts" 1317 "Global Marine Management GmbH (GMM)" 1320 "Triskel Marine" 1330 "Warwick Control Technologies" 1331 "Dolphin Charger" 1337 "Barnacle Systems" 1348 "Radian IoT" 1353 "Ocean LED Marine" 1359 "BluNav" 1361 "OVA (Nantong Saiyang Electronics Co., Ltd)" 1368 "RAD Propulsion" 1369 "Electric Yacht" 1372 "Elco Motor Yachts" 1384 "Tecnoseal Foundry S.r.l" 1385 "Pro Charging Systems" 1389 "EVEX" 1398 "Gobius Sensor Technology" 1403 "Arco Marine" 1408 "Lenco Marine" 1413 "Naocontrol" 1417 "Revatek" 1438 "Aeolionics" 1439 "PredictWind" 1440 "Egis Mobile Electric" 1445 "Starboard Yacht Group" 1446 "Roswell Marine" 1451 "ePropulsion (Guangdong ePropulsion Technology Ltd.)" 1452 "Micro-Air" 1453 "Vital Battery" 1458 "Ride Controller" 1460 "Tocaro Blue" 1461 "Vanquish Yachts" 1471 "FT Technologies" 1478 "Alps Alpine" 1481 "E-Force Marine" 1482 "CMC Marine" 1483 "Nanjing Sandemarine Information Technology" 1850 "Teleflex Marine (SeaStar Solutions)" 1851 "Raymarine" 1852 "Navionics" 1853 "Japan Radio" 1854 "Northstar Technologies" 1855 "Furuno" 1856 "Trimble" 1857 "Simrad" 1858 "Litton" 1859 "Kvasar" 1860 "MMP" 1861 "Vector Cantech" 1862 "Yamaha Marine" 1863 "Faria Instruments" ;
VAL_ 2298413056 Industry_Code 0 "Global" 1 "Highway" 2 "Agriculture" 3 "Construction" 4 "Marine Industry" 5 "Industrial" ;
VAL_ 2298413056 Direction 0 "None" 1 "Direction 1" 2 "Direction 2" ;
VAL_ 2298413056 Device_Action 1 "Active" 2 "Standby" ;
VAL_ 2566848512 Manufacturer_Code 69 "ARKS Enterprises" 78 "FW Murphy/Enovation Controls" 80 "Twin Disc" 85 "Kohler Power Systems" 88 "Hemisphere GPS" 135 "Airmar" 137 "Maretron" 140 "Lowrance" 144 "Mercury Marine" 147 "Nautibus Electronic" 148 "Blue Water Data" 154 "Westerbeke" 157 "ISSPRO" 161 "Offshore Systems (UK)" 163 "Evinrude/BRP" 165 "CPAC Systems" 168 "Xantrex Technology" 169 "Marlin Technologies" 172 "Yanmar Marine" 174 "Volvo Penta" 176 "Carling Technologies Inc. (Moritz Aerospace)" 185 "Beede Instruments" 192 "Floscan Instrument" 193 "Nobeltec" 198 "Mystic Valley Communications" 199 "Actia" 201 "Disenos Y Technologia" 211 "Digital Switching Systems" 215 "Xintex/Atena" 224 "EMMI NETWORK" 228 "ZF" 229 "Garmin" 233 "Yacht Monitoring Solutions" 235 "Sailormade Marine Telemetry/Tetra Technology" 243 "Eride" 257 "Honda Motor" 272 "Groco" 273 "Actisense" 274 "Amphenol LTW Technology" 275 "Navico" 283 "Hamilton Jet" 285 "Sea Recovery" 286 "Coelmo SRL Italy" 295 "BEP Marine" 304 "Empir Bus" 305 "NovAtel" 306 "Sleipner Motor" 307 "MBW Technologies" 315 "ICOM" 328 "Qwerty" 329 "Dief" 341 "Boening Automationstechnologie" 345 "Korean Maritime University" 351 "Thrane and Thrane" 355 "Mastervolt" 356 "Fischer Panda Generators" 358 "Victron Energy" 370 "Rolls Royce Marine" 373 "Electronic Design" 374 "Northern Lights" 378 "Glendinning" 381 "B & G" 384 "Rose Point Navigation Systems" 385 "Johnson Outdoors Marine Electronics Inc Geonav" 394 "Capi 2" 396 "Beyond Measure" 400 "Livorsi Marine" 404 "ComNav" 409 "Chetco" 419 "Fusion Electronics" 421 "Standard Horizon" 422 "True Heading" 426 "Egersund Marine Electronics" 427 "em-trak Marine Electronics" 431 "Tohatsu Co, JP" 437 "Digital Yacht" 438 "Comar Systems Limited" 440 "Cummins" 443 "VDO (aka Continental-Corporation)" 451 "Parker Hannifin aka Village Marine Tech" 459 "Alltek Marine Electronics" 460 "SAN GIORGIO S.E.I.N" 466 "Veethree Electronics & Marine" 470 "SI-TEX Marine Electronics" 471 "Sea Cross Marine" 475 "GME aka Standard Communications" 476 "Humminbird Marine Electronics" 478 "Ocean Sat" 481 "Chetco Digital Instruments" 493 "Watcheye" 499 "Lcj Capteurs" 502 "Attwood Marine" 503 "Naviop S.R.L." 504 "Vesper Marine" 510 "Marinesoft" 513 "Simarine" 517 "NoLand Engineering" 518 "Transas USA" 529 "National Instruments Korea" 530 "National Marine Electronics Association" 532 "Onwa Marine" 540 "Webasto" 571 "Marinecraft (South Korea)" 573 "McMurdo Group aka Orolia" 578 "Advansea" 579 "KVH" 580 "San Jose Technology" 583 "Yacht Control" 586 "Suzuki Motor" 591 "US Coast Guard" 595 "Ship Module aka Customware" 600 "Aquatic AV" 605 "Aventics" 606 "Intellian" 612 "SamwonIT" 614 "Arlt Tecnologies" 637 "Bavaria Yachts" 641 "Diverse Yacht Services" 644 "Wema U.S.A dba KUS" 658 "Shenzhen Jiuzhou Himunication" 688 "Rockford" 699 "Harman International" 704 "JL Audio" 708 "Lars Thrane" 715 "Autonnic" 717 "Yacht Devices" 734 "REAP Systems" 735 "AEM Performance Electronics" 739 "LxNav" 741 "Littelfuse, Inc (formerly Carling Technologies)" 743 "DaeMyung" 744 "Woosung" 748 "ISOTTA IFRA srl" 773 "Clarion US" 776 "HMI Systems" 777 "Ocean Signal" 778 "Seakeeper" 781 "Poly Planar" 785 "Fischer Panda DE" 795 "Broyda Industries" 796 "Canadian Automotive" 797 "Tides Marine" 798 "Lumishore" 799 "Still Water Designs and Audio" 802 "BJ Technologies (Beneteau)" 803 "Gill Sensors" 811 "Blue Water Desalination" 815 "FLIR" 824 "Undheim Systems" 826 "Lewmar" 838 "TeamSurv" 844 "Fell Marine" 847 "Oceanvolt" 862 "Prospec" 868 "Data Panel" 890 "L3 Technologies" 894 "Rhodan Marine Systems" 896 "Nexfour Solutions" 905 "ASA Electronics" 909 "Marines Co (South Korea)" 911 "Nautic-on" 917 "Sentinel" 929 "JL Marine Systems" 930 "Ecotronix" 944 "Zontisa Marine" 951 "EXOR International" 962 "Timbolier Industries" 963 "TJC Micro" 968 "Cox Powertrain" 969 "Blue Seas" 981 "Kobelt Manufacturing" 992 "Blue Ocean IOT" 997 "Xenta Systems" 999 "Signal K" 1004 "Ultraflex" 1008 "Lintest SmartBoat" 1011 "Soundmax" 1020 "Team Italia Marine (Onyx Marine Automation s.r.l)" 1021 "Entratech" 1022 "ITC" 1029 "The Marine Guardian" 1047 "Sonic" 1051 "ProNav" 1053 "Vetus Maxwell INC." 1056 "Lithium Pros" 1059 "Boatrax" 1062 "Marol Co ltd" 1065 "CALYPSO Instruments" 1066 "Spot Zero Water" 1069 "Lithionics Battery" 1070 "Quick-teck Electronics" 1075 "Uniden America" 1083 "Nauticoncept" 1084 "Shadow-Caster LED lighting" 1085 "Wet Sounds" 1088 "E-T-A Circuit Breakers" 1092 "Scheiber" 1100 "Smart Yachts International Limited" 1109 "Dockmate" 1114 "Bobs Machine" 1118 "L3Harris ASV" 1119 "Balmar" 1120 "Elettromedia" 1127 "Electromaax" 1140 "Across Oceans Systems" 1145 "Kiwi Yachting" 1150 "BSB Artificial Intelligence" 1151 "Orca Technologies" 1154 "TBS Electronics" 1158 "Technoton Electroics" 1160 "MG Energy Systems" 1169 "Sea Machine Robotics" 1171 "Vista Manufacturing" 1183 "Zipwake" 1186 "Sailmon" 1192 "Airmoniq Pro Kft" 1194 "Sierra Marine" 1200 "Xinuo Information Technology (Xiamen)" 1218 "Septentrio" 1233 "NKE Marine Electronics" 1238 "SuperTrack Aps" 1239 "Honda Electronics" 1245 "Raritan Engineering" 1249 "Integrated Power Solutions AG" 1260 "Interactive Technologies" 1283 "LTG-Tech" 1299 "Energy Solutions (UK)" 1300 "WATT Fuel Cell" 1302 "Pro Mainer" 1305 "Dragonfly Energy" 1306 "Koden Electronics" 1311 "Humphree" 1316 "Hinkley Yachts" 1317 "Global Marine Management GmbH (GMM)" 1320 "Triskel Marine" 1330 "Warwick Control Technologies" 1331 "Dolphin Charger" 1337 "Barnacle Systems" 1348 "Radian IoT" 1353 "Ocean LED Marine" 1359 "BluNav" 1361 "OVA (Nantong Saiyang Electronics Co., Ltd)" 1368 "RAD Propulsion" 1369 "Electric Yacht" 1372 "Elco Motor Yachts" 1384 "Tecnoseal Foundry S.r.l" 1385 "Pro Charging Systems" 1389 "EVEX" 1398 "Gobius Sensor Technology" 1403 "Arco Marine" 1408 "Lenco Marine" 1413 "Naocontrol" 1417 "Revatek" 1438 "Aeolionics" 1439 "PredictWind" 1440 "Egis Mobile Electric" 1445 "Starboard Yacht Group" 1446 "Roswell Marine" 1451 "ePropulsion (Guangdong ePropulsion Technology Ltd.)" 1452 "Micro-Air" 1453 "Vital Battery" 1458 "Ride Controller" 1460 "Tocaro Blue" 1461 "Vanquish Yachts" 1471 "FT Technologies" 1478 "Alps Alpine" 1481 "E-Force Marine" 1482 "CMC Marine" 1483 "Nanjing Sandemarine Information Technology" 1850 "Teleflex Marine (SeaStar Solutions)" 1851 "Raymarine" 1852 "Navionics" 1853 "Japan Radio" 1854 "Northstar Technologies" 1855 "Furuno" 1856 "Trimble" 1857 "Simrad" 1858 "Litton" 1859 "Kvasar" 1860 "MMP" 1861 "Vector Cantech" 1862 "Yamaha Marine" 1863 "Faria Instruments" ;
VAL_ 2566848512 Industry_Code 0 "Global" 1 "Highway" 2 "Agriculture" 3 "Construction" 4 "Marine Industry" 5 "Industrial" ;
VAL_ 2566848512 Engine_Instance 0 "Single Engine or Dual Engine Port" 1 "Dual Engine Starboard" ;
VAL_ 2566848512 Transmission_Gear 0 "Forward" 1 "Neutral" 2 "Reverse" ;
VAL_ 2566848768 Manufacturer_Code 69 "ARKS Enterprises" 78 "FW Murphy/Enovation Controls" 80 "Twin Disc" 85 "Kohler Power Systems" 88 "Hemisphere GPS" 135 "Airmar" 137 "Maretron" 140 "Lowrance" 144 "Mercury Marine" 147 "Nautibus Electronic" 148 "Blue Water Data" 154 "Westerbeke" 157 "ISSPRO" 161 "Offshore Systems (UK)" 163 "Evinrude/BRP" 165 "CPAC Systems" 168 "Xantrex Technology" 169 "Marlin Technologies" 172 "Yanmar Marine" 174 "Volvo Penta" 176 "Carling Technologies Inc. (Moritz Aerospace)" 185 "Beede Instruments" 192 "Floscan Instrument" 193 "Nobeltec" 198 "Mystic Valley Communications" 199 "Actia" 201 "Disenos Y Technologia" 211 "Digital Switching Systems" 215 "Xintex/Atena" 224 "EMMI NETWORK" 228 "ZF" 229 "Garmin" 233 "Yacht Monitoring Solutions" 235 "Sailormade Marine Telemetry/Tetra Technology" 243 "Eride" 257 "Honda Motor" 272 "Groco" 273 "Actisense" 274 "Amphenol LTW Technology" 275 "Navico" 283 "Hamilton Jet" 285 "Sea Recovery" 286 "Coelmo SRL Italy" 295 "BEP Marine" 304 "Empir Bus" 305 "NovAtel" 306 "Sleipner Motor" 307 "MBW Technologies" 315 "ICOM" 328 "Qwerty" 329 "Dief" 341 "Boening Automationstechnologie" 345 "Korean Maritime University" 351 "Thrane and Thrane" 355 "Mastervolt" 356 "Fischer Panda Generators" 358 "Victron Energy" 370 "Rolls Royce Marine" 373 "Electronic Design" 374 "Northern Lights" 378 "Glendinning" 381 "B & G" 384 "Rose Point Navigation Systems" 385 "Johnson Outdoors Marine Electronics Inc Geonav" 394 "Capi 2" 396 "Beyond Measure" 400 "Livorsi Marine" 404 "ComNav" 409 "Chetco" 419 "Fusion Electronics" 421 "Standard Horizon" 422 "True Heading" 426 "Egersund Marine Electronics" 427 "em-trak Marine Electronics" 431 "Tohatsu Co, JP" 437 "Digital Yacht" 438 "Comar Systems Limited" 440 "Cummins" 443 "VDO (aka Continental-Corporation)" 451 "Parker Hannifin aka Village Marine Tech" 459 "Alltek Marine Electronics" 460 "SAN GIORGIO S.E.I.N" 466 "Veethree Electronics & Marine" 470 "SI-TEX Marine Electronics" 471 "Sea Cross Marine" 475 "GME aka Standard Communications" 476 "Humminbird Marine Electronics" 478 "Ocean Sat" 481 "Chetco Digital Instruments" 493 "Watcheye" 499 "Lcj Capteurs" 502 "Attwood Marine" 503 "Naviop S.R.L." 504 "Vesper Marine" 510 "Marinesoft" 513 "Simarine" 517 "NoLand Engineering" 518 "Transas USA" 529 "National Instruments Korea" 530 "National Marine Electronics Association" 532 "Onwa Marine" 540 "Webasto" 571 "Marinecraft (South Korea)" 573 "McMurdo Group aka Orolia" 578 "Advansea" 579 "KVH" 580 "San Jose Technology" 583 "Yacht Control" 586 "Suzuki Motor" 591 "US Coast Guard" 595 "Ship Module aka Customware" 600 "Aquatic AV" 605 "Aventics" 606 "Intellian" 612 "SamwonIT" 614 "Arlt Tecnologies" 637 "Bavaria Yachts" 641 "Diverse Yacht Services" 644 "Wema U.S.A dba KUS" 658 "Shenzhen Jiuzhou Himunication" 688 "Rockford" 699 "Harman International" 704 "JL Audio" 708 "Lars Thrane" 715 "Autonnic" 717 "Yacht Devices" 734 "REAP Systems" 735 "AEM Performance Electronics" 739 "LxNav" 741 "Littelfuse, Inc (formerly Carling Technologies)" 743 "DaeMyung" 744 "Woosung" 748 "ISOTTA IFRA srl" 773 "Clarion US" 776 "HMI Systems" 777 "Ocean Signal" 778 "Seakeeper" 781 "Poly Planar" 785 "Fischer Panda DE" 795 "Broyda Industries" 796 "Canadian Automotive" 797 "Tides Marine" 798 "Lumishore" 799 "Still Water Designs and Audio" 802 "BJ Technologies (Beneteau)" 803 "Gill Sensors" 811 "Blue Water Desalination" 815 "FLIR" 824 "Undheim Systems" 826 "Lewmar" 838 "TeamSurv" 844 "Fell Marine" 847 "Oceanvolt" 862 "Prospec" 868 "Data Panel" 890 "L3 Technologies" 894 "Rhodan Marine Systems" 896 "Nexfour Solutions" 905 "ASA Electronics" 909 "Marines Co (South Korea)" 911 "Nautic-on" 917 "Sentinel" 929 "JL Marine Systems" 930 "Ecotronix" 944 "Zontisa Marine" 951 "EXOR International" 962 "Timbolier Industries" 963 "TJC Micro" 968 "Cox Powertrain" 969 "Blue Seas" 981 "Kobelt Manufacturing" 992 "Blue Ocean IOT" 997 "Xenta Systems" 999 "Signal K" 1004 "Ultraflex" 1008 "Lintest SmartBoat" 1011 "Soundmax" 1020 "Team Italia Marine (Onyx Marine Automation s.r.l)" 1021 "Entratech" 1022 "ITC" 1029 "The Marine Guardian" 1047 "Sonic" 1051 "ProNav" 1053 "Vetus Maxwell INC." 1056 "Lithium Pros" 1059 "Boatrax" 1062 "Marol Co ltd" 1065 "CALYPSO Instruments" 1066 "Spot Zero Water" 1069 "Lithionics Battery" 1070 "Quick-teck Electronics" 1075 "Uniden America" 1083 "Nauticoncept" 1084 "Shadow-Caster LED lighting" 1085 "Wet Sounds" 1088 "E-T-A Circuit Breakers" 1092 "Scheiber" 1100 "Smart Yachts International Limited" 1109 "Dockmate" 1114 "Bobs Machine" 1118 "L3Harris ASV" 1119 "Balmar" 1120 "Elettromedia" 1127 "Electromaax" 1140 "Across Oceans Systems" 1145 "Kiwi Yachting" 1150 "BSB Artificial Intelligence" 1151 "Orca Technologies" 1154 "TBS Electronics" 1158 "Technoton Electroics" 1160 "MG Energy Systems" 1169 "Sea Machine Robotics" 1171 "Vista Manufacturing" 1183 "Zipwake" 1186 "Sailmon" 1192 "Airmoniq Pro Kft" 1194 "Sierra Marine" 1200 "Xinuo Information Technology (Xiamen)" 1218 "Septentrio" 1233 "NKE Marine Electronics" 1238 "SuperTrack Aps" 1239 "Honda Electronics" 1245 "Raritan Engineering" 1249 "Integrated Power Solutions AG" 1260 "Interactive Technologies" 1283 "LTG-Tech" 1299 "Energy Solutions (UK)" 1300 "WATT Fuel Cell" 1302 "Pro Mainer" 1305 "Dragonfly Energy" 1306 "Koden Electronics" 1311 "Humphree" 1316 "Hinkley Yachts" 1317 "Global Marine Management GmbH (GMM)" 1320 "Triskel Marine" 1330 "Warwick Control Technologies" 1331 "Dolphin Charger" 1337 "Barnacle Systems" 1348 "Radian IoT" 1353 "Ocean LED Marine" 1359 "BluNav" 1361 "OVA (Nantong Saiyang Electronics Co., Ltd)" 1368 "RAD Propulsion" 1369 "Electric Yacht" 1372 "Elco Motor Yachts" 1384 "Tecnoseal Foundry S.r.l" 1385 "Pro Charging Systems" 1389 "EVEX" 1398 "Gobius Sensor Technology" 1403 "Arco Marine" 1408 "Lenco Marine" 1413 "Naocontrol" 1417 "Revatek" 1438 "Aeolionics" 1439 "PredictWind" 1440 "Egis Mobile Electric" 1445 "Starboard Yacht Group" 1446 "Roswell Marine" 1451 "ePropulsion (Guangdong ePropulsion Technology Ltd.)" 1452 "Micro-Air" 1453 "Vital Battery" 1458 "Ride Controller" 1460 "Tocaro Blue" 1461 "Vanquish Yachts" 1471 "FT Technologies" 1478 "Alps Alpine" 1481 "E-Force Marine" 1482 "CMC Marine" 1483 "Nanjing Sandemarine Information Technology" 1850 "Teleflex Marine (SeaStar Solutions)" 1851 "Raymarine" 1852 "Navionics" 1853 "Japan Radio" 1854 "Northstar Technologies" 1855 "Furuno" 1856 "Trimble" 1857 "Simrad" 1858 "Litton" 1859 "Kvasar" 1860 "MMP" 1861 "Vector Cantech" 1862 "Yamaha Marine" 1863 "Faria Instruments" ;
VAL_ 2566848768 Industry_Code 0 "Global" 1 "Highway" 2 "Agriculture" 3 "Construction" 4 "Marine Industry" 5 "Industrial" ;
VAL_ 2566848768 Manufacturer_Code 69 "ARKS Enterprises" 78 "FW Murphy/Enovation Controls" 80 "Twin Disc" 85 "Kohler Power Systems" 88 "Hemisphere GPS" 135 "Airmar" 137 "Maretron" 140 "Lowrance" 144 "Mercury Marine" 147 "Nautibus Electronic" 148 "Blue Water Data" 154 "Westerbeke" 157 "ISSPRO" 161 "Offshore Systems (UK)" 163 "Evinrude/BRP" 165 "CPAC Systems" 168 "Xantrex Technology" 169 "Marlin Technologies" 172 "Yanmar Marine" 174 "Volvo Penta" 176 "Carling Technologies Inc. (Moritz Aerospace)" 185 "Beede Instruments" 192 "Floscan Instrument" 193 "Nobeltec" 198 "Mystic Valley Communications" 199 "Actia" 201 "Disenos Y Technologia" 211 "Digital Switching Systems" 215 "Xintex/Atena" 224 "EMMI NETWORK" 228 "ZF" 229 "Garmin" 233 "Yacht Monitoring Solutions" 235 "Sailormade Marine Telemetry/Tetra Technology" 243 "Eride" 257 "Honda Motor" 272 "Groco" 273 "Actisense" 274 "Amphenol LTW Technology" 275 "Navico" 283 "Hamilton Jet" 285 "Sea Recovery" 286 "Coelmo SRL Italy" 295 "BEP Marine" 304 "Empir Bus" 305 "NovAtel" 306 "Sleipner Motor" 307 "MBW Technologies" 315 "ICOM" 328 "Qwerty" 329 "Dief" 341 "Boening Automationstechnologie" 345 "Korean Maritime University" 351 "Thrane and Thrane" 355 "Mastervolt" 356 "Fischer Panda Generators" 358 "Victron Energy" 370 "Rolls Royce Marine" 373 "Electronic Design" 374 "Northern Lights" 378 "Glendinning" 381 "B & G" 384 "Rose Point Navigation Systems" 385 "Johnson Outdoors Marine Electronics Inc Geonav" 394 "Capi 2" 396 "Beyond Measure" 400 "Livorsi Marine" 404 "ComNav" 409 "Chetco" 419 "Fusion Electronics" 421 "Standard Horizon" 422 "True Heading" 426 "Egersund Marine Electronics" 427 "em-trak Marine Electronics" 431 "Tohatsu Co, JP" 437 "Digital Yacht" 438 "Comar Systems Limited" 440 "Cummins" 443 "VDO (aka Continental-Corporation)" 451 "Parker Hannifin aka Village Marine Tech" 459 "Alltek Marine Electronics" 460 "SAN GIORGIO S.E.I.N" 466 "Veethree Electronics & Marine" 470 "SI-TEX Marine Electronics" 471 "Sea Cross Marine" 475 "GME aka Standard Communications" 476 "Humminbird Marine Electronics" 478 "Ocean Sat" 481 "Chetco Digital Instruments" 493 "Watcheye" 499 "Lcj Capteurs" 502 "Attwood Marine" 503 "Naviop S.R.L." 504 "Vesper Marine" 510 "Marinesoft" 513 "Simarine" 517 "NoLand Engineering" 518 "Transas USA" 529 "National Instruments Korea" 530 "National Marine Electronics Association" 532 "Onwa Marine" 540 "Webasto" 571 "Marinecraft (South Korea)" 573 "McMurdo Group aka Orolia" 578 "Advansea" 579 "KVH" 580 "San Jose Technology" 583 "Yacht Control" 586 "Suzuki Motor" 591 "US Coast Guard" 595 "Ship Module aka Customware" 600 "Aquatic AV" 605 "Aventics" 606 "Intellian" 612 "SamwonIT" 614 "Arlt Tecnologies" 637 "Bavaria Yachts" 641 "Diverse Yacht Services" 644 "Wema U.S.A dba KUS" 658 "Shenzhen Jiuzhou Himunication" 688 "Rockford" 699 "Harman International" 704 "JL Audio" 708 "Lars Thrane" 715 "Autonnic" 717 "Yacht Devices" 734 "REAP Systems" 735 "AEM Performance Electronics" 739 "LxNav" 741 "Littelfuse, Inc (formerly Carling Technologies)" 743 "DaeMyung" 744 "Woosung" 748 "ISOTTA IFRA srl" 773 "Clarion US" 776 "HMI Systems" 777 "Ocean Signal" 778 "Seakeeper" 781 "Poly Planar" 785 "Fischer Panda DE" 795 "Broyda Industries" 796 "Canadian Automotive" 797 "Tides Marine" 798 "Lumishore" 799 "Still Water Designs and Audio" 802 "BJ Technologies (Beneteau)" 803 "Gill Sensors" 811 "Blue Water Desalination" 815 "FLIR" 824 "Undheim Systems" 826 "Lewmar" 838 "TeamSurv" 844 "Fell Marine" 847 "Oceanvolt" 862 "Prospec" 868 "Data Panel" 890 "L3 Technologies" 894 "Rhodan Marine Systems" 896 "Nexfour Solutions" 905 "ASA Electronics" 909 "Marines Co (South Korea)" 911 "Nautic-on" 917 "Sentinel" 929 "JL Marine Systems" 930 "Ecotronix" 944 "Zontisa Marine" 951 "EXOR International" 962 "Timbolier Industries" 963 "TJC Micro" 968 "Cox Powertrain" 969 "Blue Seas" 981 "Kobelt Manufacturing" 992 "Blue Ocean IOT" 997 "Xenta Systems" 999 "Signal K" 1004 "Ultraflex" 1008 "Lintest SmartBoat" 1011 "Soundmax" 1020 "Team Italia Marine (Onyx Marine Automation s.r.l)" 1021 "Entratech" 1022 "ITC" 1029 "The Marine Guardian" 1047 "Sonic" 1051 "ProNav" 1053 "Vetus Maxwell INC." 1056 "Lithium Pros" 1059 "Boatrax" 1062 "Marol Co ltd" 1065 "CALYPSO Instruments" 1066 "Spot Zero Water" 1069 "Lithionics Battery" 1070 "Quick-teck Electronics" 1075 "Uniden America" 1083 "Nauticoncept" 1084 "Shadow-Caster LED lighting" 1085 "Wet Sounds" 1088 "E-T-A Circuit Breakers" 1092 "Scheiber" 1100 "Smart Yachts International Limited" 1109 "Dockmate" 1114 "Bobs Machine" 1118 "L3Harris ASV" 1119 "Balmar" 1120 "Elettromedia" 1127 "Electromaax" 1140 "Across Oceans Systems" 1145 "Kiwi Yachting" 1150 "BSB Artificial Intelligence" 1151 "Orca Technologies" 1154 "TBS Electronics" 1158 "Technoton Electroics" 1160 "MG Energy Systems" 1169 "Sea Machine Robotics" 1171 "Vista Manufacturing" 1183 "Zipwake" 1186 "Sailmon" 1192 "Airmoniq Pro Kft" 1194 "Sierra Marine" 1200 "Xinuo Information Technology (Xiamen)" 1218 "Septentrio" 1233 "NKE Marine Electronics" 1238 "SuperTrack Aps" 1239 "Honda Electronics" 1245 "Raritan Engineering" 1249 "Integrated Power Solutions AG" 1260 "Interactive Technologies" 1283 "LTG-Tech" 1299 "Energy Solutions (UK)" 1300 "WATT Fuel Cell" 1302 "Pro Mainer" 1305 "Dragonfly Energy" 1306 "Koden Electronics" 1311 "Humphree" 1316 "Hinkley Yachts" 1317 "Global Marine Management GmbH (GMM)" 1320 "Triskel Marine" 1330 "Warwick Control Technologies" 1331 "Dolphin Charger" 1337 "Barnacle Systems" 1348 "Radian IoT" 1353 "Ocean LED Marine" 1359 "BluNav" 1361 "OVA (Nantong Saiyang Electronics Co., Ltd)" 1368 "RAD Propulsion" 1369 "Electric Yacht" 1372 "Elco Motor Yachts" 1384 "Tecnoseal Foundry S.r.l" 1385 "Pro Charging Systems" 1389 "EVEX" 1398 "Gobius Sensor Technology" 1403 "Arco Marine" 1408 "Lenco Marine" 1413 "Naocontrol" 1417 "Revatek" 1438 "Aeolionics" 1439 "PredictWind" 1440 "Egis Mobile Electric" 1445 "Starboard Yacht Group" 1446 "Roswell Marine" 1451 "ePropulsion (Guangdong ePropulsion Technology Ltd.)" 1452 "Micro-Air" 1453 "Vital Battery" 1458 "Ride Controller" 1460 "Tocaro Blue" 1461 "Vanquish Yachts" 1471 "FT Technologies" 1478 "Alps Alpine" 1481 "E-Force Marine" 1482 "CMC Marine" 1483 "Nanjing Sandemarine Information Technology" 1850 "Teleflex Marine (SeaStar Solutions)" 1851 "Raymarine" 1852 "Navionics" 1853 "Japan Radio" 1854 "Northstar Technologies" 1855 "Furuno" 1856 "Trimble" 1857 "Simrad" 1858 "Litton" 1859 "Kvasar" 1860 "MMP" 1861 "Vector Cantech" 1862 "Yamaha Marine" 1863 "Faria Instruments" ;
VAL_ 2566848768 Industry_Code 0 "Global" 1 "Highway" 2 "Agriculture" 3 "Construction" 4 "Marine Industry" 5 "Industrial" ;
VAL_ 2566849024 Manufacturer_Code 69 "ARKS Enterprises" 78 "FW Murphy/Enovation Controls" 80 "Twin Disc" 85 "Kohler Power Systems" 88 "Hemisphere GPS" 135 "Airmar" 137 "Maretron" 140 "Lowrance" 144 "Mercury Marine" 147 "Nautibus Electronic" 148 "Blue Water Data" 154 "Westerbeke" 157 "ISSPRO" 161 "Offshore Systems (UK)" 163 "Evinrude/BRP" 165 "CPAC Systems" 168 "Xantrex Technology" 169 "Marlin Technologies" 172 "Yanmar Marine" 174 "Volvo Penta" 176 "Carling Technologies Inc. (Moritz Aerospace)" 185 "Beede Instruments" 192 "Floscan Instrument" 193 "Nobeltec" 198 "Mystic Valley Communications" 199 "Actia" 201 "Disenos Y Technologia" 211 "Digital Switching Systems" 215 "Xintex/Atena" 224 "EMMI NETWORK" 228 "ZF" 229 "Garmin" 233 "Yacht Monitoring Solutions" 235 "Sailormade Marine Telemetry/Tetra Technology" 243 "Eride" 257 "Honda Motor" 272 "Groco" 273 "Actisense" 274 "Amphenol LTW Technology" 275 "Navico" 283 "Hamilton Jet" 285 "Sea Recovery" 286 "Coelmo SRL Italy" 295 "BEP Marine" 304 "Empir Bus" 305 "NovAtel" 306 "Sleipner Motor" 307 "MBW Technologies" 315 "ICOM" 328 "Qwerty" 329 "Dief" 341 "Boening Automationstechnologie" 345 "Korean Maritime University" 351 "Thrane and Thrane" 355 "Mastervolt" 356 "Fischer Panda Generators" 358 "Victron Energy" 370 "Rolls Royce Marine" 373 "Electronic Design" 374 "Northern Lights" 378 "Glendinning" 381 "B & G" 384 "Rose Point Navigation Systems" 385 "Johnson Outdoors Marine Electronics Inc Geonav" 394 "Capi 2" 396 "Beyond Measure" 400 "Livorsi Marine" 404 "ComNav" 409 "Chetco" 419 "Fusion Electronics" 421 "Standard Horizon" 422 "True Heading" 426 "Egersund Marine Electronics" 427 "em-trak Marine Electronics" 431 "Tohatsu Co, JP" 437 "Digital Yacht" 438 "Comar Systems Limited" 440 "Cummins" 443 "VDO (aka Continental-Corporation)" 451 "Parker Hannifin aka Village Marine Tech" 459 "Alltek Marine Electronics" 460 "SAN GIORGIO S.E.I.N" 466 "Veethree Electronics & Marine" 470 "SI-TEX Marine Electronics" 471 "Sea Cross Marine" 475 "GME aka Standard Communications" 476 "Humminbird Marine Electronics" 478 "Ocean Sat" 481 "Chetco Digital Instruments" 493 "Watcheye" 499 "Lcj Capteurs" 502 "Attwood Marine" 503 "Naviop S.R.L." 504 "Vesper Marine" 510 "Marinesoft" 513 "Simarine" 517 "NoLand Engineering" 518 "Transas USA" 529 "National Instruments Korea" 530 "National Marine Electronics Association" 532 "Onwa Marine" 540 "Webasto" 571 "Marinecraft (South Korea)" 573 "McMurdo Group aka Orolia" 578 "Advansea" 579 "KVH" 580 "San Jose Technology" 583 "Yacht Control" 586 "Suzuki Motor" 591 "US Coast Guard" 595 "Ship Module aka Customware" 600 "Aquatic AV" 605 "Aventics" 606 "Intellian" 612 "SamwonIT" 614 "Arlt Tecnologies" 637 "Bavaria Yachts" 641 "Diverse Yacht Services" 644 "Wema U.S.A dba KUS" 658 "Shenzhen Jiuzhou Himunication" 688 "Rockford" 699 "Harman International" 704 "JL Audio" 708 "Lars Thrane" 715 "Autonnic" 717 "Yacht Devices" 734 "REAP Systems" 735 "AEM Performance Electronics" 739 "LxNav" 741 "Littelfuse, Inc (formerly Carling Technologies)" 743 "DaeMyung" 744 "Woosung" 748 "ISOTTA IFRA srl" 773 "Clarion US" 776 "HMI Systems" 777 "Ocean Signal" 778 "Seakeeper" 781 "Poly Planar" 785 "Fischer Panda DE" 795 "Broyda Industries" 796 "Canadian Automotive" 797 "Tides Marine" 798 "Lumishore" 799 "Still Water Designs and Audio" 802 "BJ Technologies (Beneteau)" 803 "Gill Sensors" 811 "Blue Water Desalination" 815 "FLIR" 824 "Undheim Systems" 826 "Lewmar" 838 "TeamSurv" 844 "Fell Marine" 847 "Oceanvolt" 862 "Prospec" 868 "Data Panel" 890 "L3 Technologies" 894 "Rhodan Marine Systems" 896 "Nexfour Solutions" 905 "ASA Electronics" 909 "Marines Co (South Korea)" 911 "Nautic-on" 917 "Sentinel" 929 "JL Marine Systems" 930 "Ecotronix" 944 "Zontisa Marine" 951 "EXOR International" 962 "Timbolier Industries" 963 "TJC Micro" 968 "Cox Powertrain" 969 "Blue Seas" 981 "Kobelt Manufacturing" 992 "Blue Ocean IOT" 997 "Xenta Systems" 999 "Signal K" 1004 "Ultraflex" 1008 "Lintest SmartBoat" 1011 "Soundmax" 1020 "Team Italia Marine (Onyx Marine Automation s.r.l)" 1021 "Entratech" 1022 "ITC" 1029 "The Marine Guardian" 1047 "Sonic" 1051 "ProNav" 1053 "Vetus Maxwell INC." 1056 "Lithium Pros" 1059 "Boatrax" 1062 "Marol Co ltd" 1065 "CALYPSO Instruments" 1066 "Spot Zero Water" 1069 "Lithionics Battery" 1070 "Quick-teck Electronics" 1075 "Uniden America" 1083 "Nauticoncept" 1084 "Shadow-Caster LED lighting" 1085 "Wet Sounds" 1088 "E-T-A Circuit Breakers" 1092 "Scheiber" 1100 "Smart Yachts International Limited" 1109 "Dockmate" 1114 "Bobs Machine" 1118 "L3Harris ASV" 1119 "Balmar" 1120 "Elettromedia" 1127 "Electromaax" 1140 "Across Oceans Systems" 1145 "Kiwi Yachting" 1150 "BSB Artificial Intelligence" 1151 "Orca Technologies" 1154 "TBS Electronics" 1158 "Technoton Electroics" 1160 "MG Energy Systems" 1169 "Sea Machine Robotics" 1171 "Vista Manufacturing" 1183 "Zipwake" 1186 "Sailmon" 1192 "Airmoniq Pro Kft" 1194 "Sierra Marine" 1200 "Xinuo Information Technology (Xiamen)" 1218 "Septentrio" 1233 "NKE Marine Electronics" 1238 "SuperTrack Aps" 1239 "Honda Electronics" 1245 "Raritan Engineering" 1249 "Integrated Power Solutions AG" 1260 "Interactive Technologies" 1283 "LTG-Tech" 1299 "Energy Solutions (UK)" 1300 "WATT Fuel Cell" 1302 "Pro Mainer" 1305 "Dragonfly Energy" 1306 "Koden Electronics" 1311 "Humphree" 1316 "Hinkley Yachts" 1317 "Global Marine Management GmbH (GMM)" 1320 "Triskel Marine" 1330 "Warwick Control Technologies" 1331 "Dolphin Charger" 1337 "Barnacle Systems" 1348 "Radian IoT" 1353 "Ocean LED Marine" 1359 "BluNav" 1361 "OVA (Nantong Saiyang Electronics Co., Ltd)" 1368 "RAD Propulsion" 1369 "Electric Yacht" 1372 "Elco Motor Yachts" 1384 "Tecnoseal Foundry S.r.l" 1385 "Pro Charging Systems" 1389 "EVEX" 1398 "Gobius Sensor Technology" 1403 "Arco Marine" 1408 "Lenco Marine" 1413 "Naocontrol" 1417 "Revatek" 1438 "Aeolionics" 1439 "PredictWind" 1440 "Egis Mobile Electric" 1445 "Starboard Yacht Group" 1446 "Roswell Marine" 1451 "ePropulsion (Guangdong ePropulsion Technology Ltd.)" 1452 "Micro-Air" 1453 "Vital Battery" 1458 "Ride Controller" 1460 "Tocaro Blue" 1461 "Vanquish Yachts" 1471 "FT Technologies" 1478 "Alps Alpine" 1481 "E-Force Marine" 1482 "CMC Marine" 1483 "Nanjing Sandemarine Information Technology" 1850 "Teleflex Marine (SeaStar Solutions)" 1851 "Raymarine" 1852 "Navionics" 1853 "Japan Radio" 1854 "Northstar Technologies" 1855 "Furuno" 1856 "Trimble" 1857 "Simrad" 1858 "Litton" 1859 "Kvasar" 1860 "MMP" 1861 "Vector Cantech" 1862 "Yamaha Marine" 1863 "Faria Instruments" ;
VAL_ 2566849024 Industry_Code 0 "Global" 1 "Highway" 2 "Agriculture" 3 "Construction" 4 "Marine Industry" 5 "Industrial" ;
VAL_ 2566849024 Manufacturer_Code 69 "ARKS Enterprises" 78 "FW Murphy/Enovation Controls" 80 "Twin Disc" 85 "Kohler Power Systems" 88 "Hemisphere GPS" 135 "Airmar" 137 "Maretron" 140 "Lowrance" 144 "Mercury Marine" 147 "Nautibus Electronic" 148 "Blue Water Data" 154 "Westerbeke" 157 "ISSPRO" 161 "Offshore Systems (UK)" 163 "Evinrude/BRP" 165 "CPAC Systems" 168 "Xantrex Technology" 169 "Marlin Technologies" 172 "Yanmar Marine" 174 "Volvo Penta" 176 "Carling Technologies Inc. (Moritz Aerospace)" 185 "Beede Instruments" 192 "Floscan Instrument" 193 "Nobeltec" 198 "Mystic Valley Communications" 199 "Actia" 201 "Disenos Y Technologia" 211 "Digital Switching Systems" 215 "Xintex/Atena" 224 "EMMI NETWORK" 228 "ZF" 229 "Garmin" 233 "Yacht Monitoring Solutions" 235 "Sailormade Marine Telemetry/Tetra Technology" 243 "Eride" 257 "Honda Motor" 272 "Groco" 273 "Actisense" 274 "Amphenol LTW Technology" 275 "Navico" 283 "Hamilton Jet" 285 "Sea Recovery" 286 "Coelmo SRL Italy" 295 "BEP Marine" 304 "Empir Bus" 305 "NovAtel" 306 "Sleipner Motor" 307 "MBW Technologies" 315 "ICOM" 328 "Qwerty" 329 "Dief" 341 "Boening Automationstechnologie" 345 "Korean Maritime University" 351 "Thrane and Thrane" 355 "Mastervolt" 356 "Fischer Panda Generators" 358 "Victron Energy" 370 "Rolls Royce Marine" 373 "Electronic Design" 374 "Northern Lights" 378 "Glendinning" 381 "B & G" 384 "Rose Point Navigation Systems" 385 "Johnson Outdoors Marine Electronics Inc Geonav" 394 "Capi 2" 396 "Beyond Measure" 400 "Livorsi Marine" 404 "ComNav" 409 "Chetco" 419 "Fusion Electronics" 421 "Standard Horizon" 422 "True Heading" 426 "Egersund Marine Electronics" 427 "em-trak Marine Electronics" 431 "Tohatsu Co, JP" 437 "Digital Yacht" 438 "Comar Systems Limited" 440 "Cummins" 443 "VDO (aka Continental-Corporation)" 451 "Parker Hannifin aka Village Marine Tech" 459 "Alltek Marine Electronics" 460 "SAN GIORGIO S.E.I.N" 466 "Veethree Electronics & Marine" 470 "SI-TEX Marine Electronics" 471 "Sea Cross Marine" 475 "GME aka Standard Communications" 476 "Humminbird Marine Electronics" 478 "Ocean Sat" 481 "Chetco Digital Instruments" 493 "Watcheye" 499 "Lcj Capteurs" 502 "Attwood Marine" 503 "Naviop S.R.L." 504 "Vesper Marine" 510 "Marinesoft" 513 "Simarine" 517 "NoLand Engineering" 518 "Transas USA" 529 "National Instruments Korea" 530 "National Marine Electronics Association" 532 "Onwa Marine" 540 "Webasto" 571 "Marinecraft (South Korea)" 573 "McMurdo Group aka Orolia" 578 "Advansea" 579 "KVH" 580 "San Jose Technology" 583 "Yacht Control" 586 "Suzuki Motor" 591 "US Coast Guard" 595 "Ship Module aka Customware" 600 "Aquatic AV" 605 "Aventics" 606 "Intellian" 612 "SamwonIT" 614 "Arlt Tecnologies" 637 "Bavaria Yachts" 641 "Diverse Yacht Services" 644 "Wema U.S.A dba KUS" 658 "Shenzhen Jiuzhou Himunication" 688 "Rockford" 699 "Harman International" 704 "JL Audio" 708 "Lars Thrane" 715 "Autonnic" 717 "Yacht Devices" 734 "REAP Systems" 735 "AEM Performance Electronics" 739 "LxNav" 741 "Littelfuse, Inc (formerly Carling Technologies)" 743 "DaeMyung" 744 "Woosung" 748 "ISOTTA IFRA srl" 773 "Clarion US" 776 "HMI Systems" 777 "Ocean Signal" 778 "Seakeeper" 781 "Poly Planar" 785 "Fischer Panda DE" 795 "Broyda Industries" 796 "Canadian Automotive" 797 "Tides Marine" 798 "Lumishore" 799 "Still Water Designs and Audio" 802 "BJ Technologies (Beneteau)" 803 "Gill Sensors" 811 "Blue Water Desalination" 815 "FLIR" 824 "Undheim Systems" 826 "Lewmar" 838 "TeamSurv" 844 "Fell Marine" 847 "Oceanvolt" 862 "Prospec" 868 "Data Panel" 890 "L3 Technologies" 894 "Rhodan Marine Systems" 896 "Nexfour Solutions" 905 "ASA Electronics" 909 "Marines Co (South Korea)" 911 "Nautic-on" 917 "Sentinel" 929 "JL Marine Systems" 930 "Ecotronix" 944 "Zontisa Marine" 951 "EXOR International" 962 "Timbolier Industries" 963 "TJC Micro" 968 "Cox Powertrain" 969 "Blue Seas" 981 "Kobelt Manufacturing" 992 "Blue Ocean IOT" 997 "Xenta Systems" 999 "Signal K" 1004 "Ultraflex" 1008 "Lintest SmartBoat" 1011 "Soundmax" 1020 "Team Italia Marine (Onyx Marine Automation s.r.l)" 1021 "Entratech" 1022 "ITC" 1029 "The Marine Guardian" 1047 "Sonic" 1051 "ProNav" 1053 "Vetus Maxwell INC." 1056 "Lithium Pros" 1059 "Boatrax" 1062 "Marol Co ltd" 1065 "CALYPSO Instruments" 1066 "Spot Zero Water" 1069 "Lithionics Battery" 1070 "Quick-teck Electronics" 1075 "Uniden America" 1083 "Nauticoncept" 1084 "Shadow-Caster LED lighting" 1085 "Wet Sounds" 1088 "E-T-A Circuit Breakers" 1092 "Scheiber" 1100 "Smart Yachts International Limited" 1109 "Dockmate" 1114 "Bobs Machine" 1118 "L3Harris ASV" 1119 "Balmar" 1120 "Elettromedia" 1127 "Electromaax" 1140 "Across Oceans Systems" 1145 "Kiwi Yachting" 1150 "BSB Artificial Intelligence" 1151 "Orca Technologies" 1154 "TBS Electronics" 1158 "Technoton Electroics" 1160 "MG Energy Systems" 1169 "Sea Machine Robotics" 1171 "Vista Manufacturing" 1183 "Zipwake" 1186 "Sailmon" 1192 "Airmoniq Pro Kft" 1194 "Sierra Marine" 1200 "Xinuo Information Technology (Xiamen)" 1218 "Septentrio" 1233 "NKE Marine Electronics" 1238 "SuperTrack Aps" 1239 "Honda Electronics" 1245 "Raritan Engineering" 1249 "Integrated Power Solutions AG" 1260 "Interactive Technologies" 1283 "LTG-Tech" 1299 "Energy Solutions (UK)" 1300 "WATT Fuel Cell" 1302 "Pro Mainer" 1305 "Dragonfly Energy" 1306 "Koden Electronics" 1311 "Humphree" 1316 "Hinkley Yachts" 1317 "Global Marine Management GmbH (GMM)" 1320 "Triskel Marine" 1330 "Warwick Control Technologies" 1331 "Dolphin Charger" 1337 "Barnacle Systems" 1348 "Radian IoT" 1353 "Ocean LED Marine" 1359 "BluNav" 1361 "OVA (Nantong Saiyang Electronics Co., Ltd)" 1368 "RAD Propulsion" 1369 "Electric Yacht" 1372 "Elco Motor Yachts" 1384 "Tecnoseal Foundry S.r.l" 1385 "Pro Charging Systems" 1389 "EVEX" 1398 "Gobius Sensor Technology" 1403 "Arco Marine" 1408 "Lenco Marine" 1413 "Naocontrol" 1417 "Revatek" 1438 "Aeolionics" 1439 "PredictWind" 1440 "Egis Mobile Electric" 1445 "Starboard Yacht Group" 1446 "Roswell Marine" 1451 "ePropulsion (Guangdong ePropulsion Technology Ltd.)" 1452 "Micro-Air" 1453 "Vital Battery" 1458 "Ride Controller" 1460 "Tocaro Blue" 1461 "Vanquish Yachts" 1471 "FT Technologies" 1478 "Alps Alpine" 1481 "E-Force Marine" 1482 "CMC Marine" 1483 "Nanjing Sandemarine Information Technology" 1850 "Teleflex Marine (SeaStar Solutions)" 1851 "Raymarine" 1852 "Navionics" 1853 "Japan Radio" 1854 "Northstar Technologies" 1855 "Furuno" 1856 "Trimble" 1857 "Simrad" 1858 "Litton" 1859 "Kvasar" 1860 "MMP" 1861 "Vector Cantech" 1862 "Yamaha Marine" 1863 "Faria Instruments" ;
VAL_ 2566849024 Industry_Code 0 "Global" 1 "Highway" 2 "Agriculture" 3 "Construction" 4 "Marine Industry" 5 "Industrial" ;

CM_ BU_ Vector__XXX "Converted from canboat database (Apache-2.0). NMEA2000 PGN definitions. NOT AN OFFICIAL SAE/NMEA RELEASE; see repository README for attribution requirements.";

BA_DEF_ BO_ "GenMsgCycleTime" INT 0 60000;
BA_DEF_ BO_ "ProtocolType" STRING;
BA_DEF_ "BusType" STRING;
BA_ "BusType" "CAN";
BA_ "ProtocolType" "NMEA2000";

BA_DEF_ BO_ "J1939PGN" INT 0 262143;

BA_ "J1939PGN" BO_ 2565341184 59392;
BA_ "J1939PGN" BO_ 2565341184 59392;
BA_ "J1939PGN" BO_ 2565472256 59904;
BA_ "J1939PGN" BO_ 2565537792 60160;
BA_ "J1939PGN" BO_ 2565603328 60416;
BA_ "J1939PGN" BO_ 2565603328 60416;
BA_ "J1939PGN" BO_ 2565603328 60416;
BA_ "J1939PGN" BO_ 2565603328 60416;
BA_ "J1939PGN" BO_ 2565603328 60416;
BA_ "J1939PGN" BO_ 2565734400 60928;
BA_ "J1939PGN" BO_ 2565799936 61184;
BA_ "J1939PGN" BO_ 2297364480 61184;
BA_ "J1939PGN" BO_ 2565799936 61184;
BA_ "J1939PGN" BO_ 2565799936 61184;
BA_ "J1939PGN" BO_ 2632908800 61184;
BA_ "J1939PGN" BO_ 2632908800 61184;
BA_ "J1939PGN" BO_ 2565865472 61440;
BA_ "J1939PGN" BO_ 2365450496 65001;
BA_ "J1939PGN" BO_ 2365450752 65002;
BA_ "J1939PGN" BO_ 2365451008 65003;
BA_ "J1939PGN" BO_ 2365451264 65004;
BA_ "J1939PGN" BO_ 2365451520 65005;
BA_ "J1939PGN" BO_ 2365451776 65006;
BA_ "J1939PGN" BO_ 2365452032 65007;
BA_ "J1939PGN" BO_ 2365452288 65008;
BA_ "J1939PGN" BO_ 2365452544 65009;
BA_ "J1939PGN" BO_ 2365452800 65010;
BA_ "J1939PGN" BO_ 2365453056 65011;
BA_ "J1939PGN" BO_ 2365453312 65012;
BA_ "J1939PGN" BO_ 2365453568 65013;
BA_ "J1939PGN" BO_ 2365453824 65014;
BA_ "J1939PGN" BO_ 2365454080 65015;
BA_ "J1939PGN" BO_ 2365454336 65016;
BA_ "J1939PGN" BO_ 2365454592 65017;
BA_ "J1939PGN" BO_ 2365454848 65018;
BA_ "J1939PGN" BO_ 2365455104 65019;
BA_ "J1939PGN" BO_ 2365455360 65020;
BA_ "J1939PGN" BO_ 2365455616 65021;
BA_ "J1939PGN" BO_ 2365455872 65022;
BA_ "J1939PGN" BO_ 2365456128 65023;
BA_ "J1939PGN" BO_ 2365456384 65024;
BA_ "J1939PGN" BO_ 2365456640 65025;
BA_ "J1939PGN" BO_ 2365456896 65026;
BA_ "J1939PGN" BO_ 2365457152 65027;
BA_ "J1939PGN" BO_ 2365457408 65028;
BA_ "J1939PGN" BO_ 2365457664 65029;
BA_ "J1939PGN" BO_ 2365457920 65030;
BA_ "J1939PGN" BO_ 2566838272 65240;
BA_ "J1939PGN" BO_ 2566848512 65280;
BA_ "J1939PGN" BO_ 2365521920 65280;
BA_ "J1939PGN" BO_ 2298413056 65280;
BA_ "J1939PGN" BO_ 2566848512 65280;
BA_ "J1939PGN" BO_ 2566848512 65280;
BA_ "J1939PGN" BO_ 2566848512 65280;
BA_ "J1939PGN" BO_ 2633957376 65280;
BA_ "J1939PGN" BO_ 2298413056 65280;
BA_ "J1939PGN" BO_ 2566848512 65280;
BA_ "J1939PGN" BO_ 2566848768 65281;
BA_ "J1939PGN" BO_ 2566848768 65281;
BA_ "J1939PGN" BO_ 2566849024 65282;
BA_ "J1939PGN" BO_ 2566849024 65282;

CM_ "Generated from canboat (Apache-2.0). 620 PGN, 4105 signal, 1564 enum tablosu.";
